VERSION ""

NS_ :

BS_:

BU_: VDM CMR_DSMC SOBDMC_HPCM_FD1 IPMA_ADAS PSCM ABS_ESC TCCM TCM_DSL PCM_HEV PCM ECM_Diesel GENERIC_GWMWakeup GWM _delete TSTR

BO_ 1046 BrakeSysFeatures_2: 8 ABS_ESC
 SG_ HsaMde_D_Mem : 33|2@0+ (1,0) [0|3] "SED"  GWM
 SG_ BrkBstrVac_B_Rq : 27|1@0+ (1,0) [0|1] "Discrete"  ECM_Diesel,PCM,PCM_HEV,GWM
 SG_ HdcMde_D_Actl : 31|3@0+ (1,0) [0|7] "SED"  GWM
 SG_ RearDiffLck_Tq2_RqMx : 51|12@0+ (4,0) [0|16376] "Nm"  GWM
 SG_ TRLR_SWAY_EVNT_IN_PROG : 25|1@0+ (1,0) [0|1] "SED"  GWM
 SG_ TRLR_SWAY_CONFIG_STAT : 26|1@0+ (1,0) [0|1] "SED"  GWM
 SG_ TCMode : 15|1@0+ (1,0) [0|1] "SED"  VDM,IPMA_ADAS,ECM_Diesel,PCM,PCM_HEV,GWM
 SG_ DrvSlipCtlLamp_D_Rq : 42|2@0+ (1,0) [0|3] "SED"  VDM,IPMA_ADAS,ECM_Diesel,PCM,PCM_HEV,GWM
 SG_ Abs_B_Falt : 5|1@0+ (1,0) [0|1] "SED"  ECM_Diesel,PCM,PCM_HEV,GWM
 SG_ DrvSlipCtlMde_D_Ind : 44|2@0+ (1,0) [0|3] "SED"  TCCM,IPMA_ADAS,ECM_Diesel,PCM,PCM_HEV,GWM
 SG_ DrvAntiLckLamp_D_Rq : 55|2@0+ (1,0) [0|3] "SED"  ECM_Diesel,GWM,IPMA_ADAS
 SG_ BpedMove_No_Cnt : 3|4@0+ (1,0) [0|15] "Unitless"  ECM_Diesel,GWM
 SG_ StabCtlBrk_B_Avail : 4|1@0+ (1,0) [0|1] "SED"  VDM,TCCM,GWM
 SG_ DrvHdcWarnInfo_D_Rq : 35|2@0+ (1,0) [0|3] "SED"  GWM
 SG_ DrvHdcMsg_D_Rq : 10|3@0+ (1,0) [0|7] "SED"  GWM
 SG_ DrvHdcLampInfo_D_Rq : 12|2@0+ (1,0) [0|3] "SED"  GWM
 SG_ BpedMove_D_Actl : 7|2@0+ (1,0) [0|3] "SED"  ECM_Diesel,GWM
 SG_ ChimeBrk_B_Rq : 14|1@0+ (1,0) [0|1] "SED"  GWM
 SG_ BrkLamp_B_Rq : 13|1@0+ (1,0) [0|1] "SED"  GWM
 SG_ HILL_DESC_MC : 47|3@0+ (1,0) [0|7] "SED"  GWM
 SG_ RearDiffElckrOpen_B_Rq : 40|1@0+ (1,0) [0|1] "SED"  GWM,TCCM

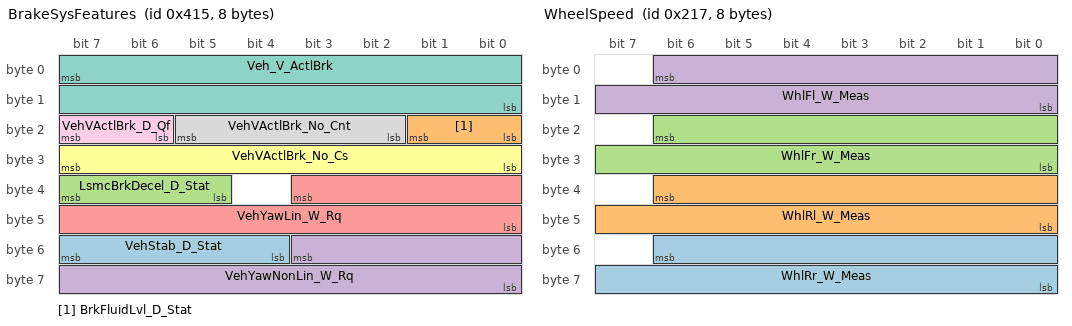
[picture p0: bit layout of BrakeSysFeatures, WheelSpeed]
BO_ 1045 BrakeSysFeatures: 8 ABS_ESC
 SG_ VehStab_D_Stat : 55|4@0+ (1,0) [0|15] "SED"  TCCM,PCM_HEV,PCM,GWM
 SG_ BrkFluidLvl_D_Stat : 17|2@0+ (1,0) [0|3] "SED"  GWM
 SG_ LsmcBrkDecel_D_Stat : 39|3@0+ (1,0) [0|7] "SED"  PSCM,GWM
 SG_ VehYawNonLin_W_Rq : 51|12@0+ (0.03663,-75) [-75|74.92659] "deg/s"  ECM_Diesel,GWM
 SG_ VehYawLin_W_Rq : 35|12@0+ (0.03663,-75) [-75|74.92659] "deg/s"  ECM_Diesel,GWM
 SG_ VehVActlBrk_No_Cs : 31|8@0+ (1,0) [0|255] "Unitless"  TCCM,CMR_DSMC,SOBDMC_HPCM_FD1,ECM_Diesel,PCM,PCM_HEV,PSCM,TCM_DSL,GWM,IPMA_ADAS
 SG_ Veh_V_ActlBrk : 7|16@0+ (0.01,0) [0|655.35] "kph"  TCCM,CMR_DSMC,SOBDMC_HPCM_FD1,IPMA_ADAS,ECM_Diesel,PCM,PCM_HEV,PSCM,TCM_DSL,GWM
 SG_ VehVActlBrk_No_Cnt : 21|4@0+ (1,0) [0|15] "Unitless"  TCCM,CMR_DSMC,SOBDMC_HPCM_FD1,ECM_Diesel,PCM,PCM_HEV,PSCM,TCM_DSL,GWM,IPMA_ADAS
 SG_ VehVActlBrk_D_Qf : 23|2@0+ (1,0) [0|3] "SED"  TCCM,CMR_DSMC,SOBDMC_HPCM_FD1,IPMA_ADAS,ECM_Diesel,PCM,PCM_HEV,PSCM,TCM_DSL,GWM

BO_ 535 WheelSpeed: 8 ABS_ESC
 SG_ WhlRr_W_Meas : 54|15@0+ (0.01,0) [0|327.65] "rad/s"  VDM,IPMA_ADAS,GWM,ECM_Diesel,PCM,PCM_HEV,PSCM,TCCM,TCM_DSL
 SG_ WhlRl_W_Meas : 38|15@0+ (0.01,0) [0|327.65] "rad/s"  VDM,IPMA_ADAS,GWM,ECM_Diesel,PCM,PCM_HEV,PSCM,TCCM,TCM_DSL
 SG_ WhlFr_W_Meas : 22|15@0+ (0.01,0) [0|327.65] "rad/s"  VDM,IPMA_ADAS,GWM,ECM_Diesel,PCM,PCM_HEV,PSCM,TCCM,TCM_DSL
 SG_ WhlFl_W_Meas : 6|15@0+ (0.01,0) [0|327.65] "rad/s"  VDM,IPMA_ADAS,GWM,ECM_Diesel,PCM,PCM_HEV,PSCM,TCCM,TCM_DSL

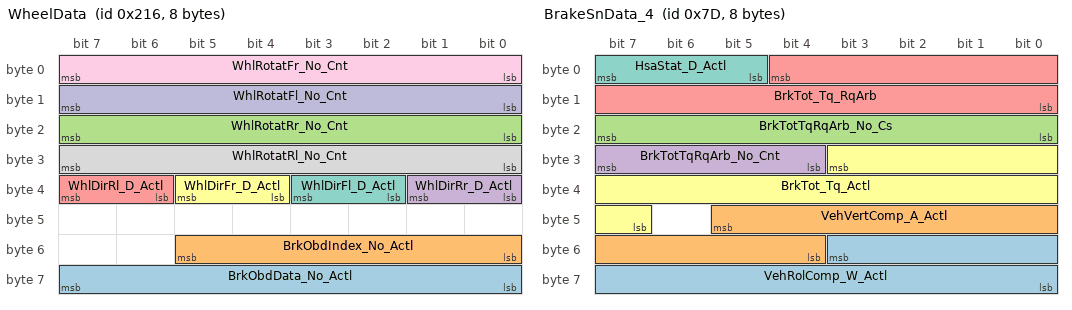
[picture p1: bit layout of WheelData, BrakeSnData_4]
BO_ 534 WheelData: 8 ABS_ESC
 SG_ BrkObdData_No_Actl : 63|8@0+ (1,0) [0|255] "unitless"  SOBDMC_HPCM_FD1,GWM
 SG_ BrkObdIndex_No_Actl : 53|6@0+ (1,0) [0|63] "unitless"  SOBDMC_HPCM_FD1,GWM
 SG_ WhlRotatRr_No_Cnt : 23|8@0+ (1,0) [0|255] "Unitless"  IPMA_ADAS,GWM,PSCM
 SG_ WhlDirRr_D_Actl : 33|2@0+ (1,0) [0|3] "SED"  IPMA_ADAS,GWM,ECM_Diesel,PCM_HEV,PSCM
 SG_ WhlDirRl_D_Actl : 39|2@0+ (1,0) [0|3] "SED"  IPMA_ADAS,GWM,PSCM,ECM_Diesel,PCM_HEV
 SG_ WhlDirFr_D_Actl : 37|2@0+ (1,0) [0|3] "SED"  IPMA_ADAS,GWM,ECM_Diesel,PCM_HEV,PSCM
 SG_ WhlDirFl_D_Actl : 35|2@0+ (1,0) [0|3] "SED"  IPMA_ADAS,GWM,ECM_Diesel,PCM_HEV,PSCM
 SG_ WhlRotatRl_No_Cnt : 31|8@0+ (1,0) [0|255] "Unitless"  IPMA_ADAS,GWM,PSCM
 SG_ WhlRotatFr_No_Cnt : 7|8@0+ (1,0) [0|255] "Unitless"  IPMA_ADAS,GWM,PSCM
 SG_ WhlRotatFl_No_Cnt : 15|8@0+ (1,0) [0|255] "Unitless"  IPMA_ADAS,GWM,PSCM

BO_ 531 DesiredTorqBrk: 8 ABS_ESC
 SG_ VehStop_D_Stat : 28|2@0+ (1,0) [0|3] "SED"  IPMA_ADAS,GWM
 SG_ TracCtlPtActv_B_Actl : 31|1@0+ (1,0) [0|1] "SED"  VDM,IPMA_ADAS,TCCM,ECM_Diesel,PCM,PCM_HEV,TCM_DSL,GWM
 SG_ LscmbbMntr_B_Err : 17|1@0+ (1,0) [0|1] "SED"  GWM
 SG_ LscmbbBrkDis_B_Actl : 19|1@0+ (1,0) [0|1] "SED"  GWM
 SG_ LscmbbDeny_B_ActlBrk : 18|1@0+ (1,0) [0|1] "SED"  GWM
 SG_ PrkBrkYwLamp_D_Rq : 38|2@0+ (1,0) [0|3] "SED"  GWM
 SG_ PrkBrkRedLamp_D_Rq : 30|2@0+ (1,0) [0|3] "SED"  GWM
 SG_ LscmbbBrkDecel_B_Actl : 20|1@0+ (1,0) [0|1] "SED"  GWM
 SG_ AbsActv_B_Actl : 45|1@0+ (1,0) [0|1] "SED"  VDM,SOBDMC_HPCM_FD1,IPMA_ADAS,ECM_Diesel,PCM,PCM_HEV,TCM_DSL,PSCM,GWM
 SG_ StabCtlBrkActv_B_Actl : 23|1@0+ (1,0) [0|1] "SED"  VDM,IPMA_ADAS,PCM,PCM_HEV,TCM_DSL,PSCM,TCCM,ECM_Diesel,GWM
 SG_ CmbbBrkPrchg_B_Actl : 59|1@0+ (1,0) [0|1] "SED"  IPMA_ADAS,GWM
 SG_ CmbbBrkDecel_B_Actl : 58|1@0+ (1,0) [0|1] "SED"  CMR_DSMC,IPMA_ADAS,GWM
 SG_ CmbbBaSensInc_B_Actl : 57|1@0+ (1,0) [0|1] "SED"  IPMA_ADAS,GWM
 SG_ AccBrkWarm_B_Actl : 63|1@0+ (1,0) [0|1] "SED"  IPMA_ADAS,GWM
 SG_ AccBrkTotTqMn_B_Actl : 62|1@0+ (1,0) [0|1] "SED"  IPMA_ADAS,GWM
 SG_ AccBrkPrchgActv_B_Actl : 61|1@0+ (1,0) [0|1] "SED"  IPMA_ADAS,GWM
 SG_ AccBrkDis_B_Actl : 44|1@0+ (1,0) [0|1] "SED"  IPMA_ADAS,GWM
 SG_ AccBrkDeny_B_Actl : 42|1@0+ (1,0) [0|1] "SED"  IPMA_ADAS,ECM_Diesel,PCM,PCM_HEV,GWM
 SG_ AccBrkActv_B_Actl : 43|1@0+ (1,0) [0|1] "SED"  IPMA_ADAS,ECM_Diesel,GWM
 SG_ PrplDrgCtlActv_B_Actl : 46|1@0+ (1,0) [0|1] "SED"  ECM_Diesel,PCM,PCM_HEV,TCM_DSL,GWM
 SG_ PrplWhlTot_Tq_RqMx : 7|16@0+ (4,-131072) [-131072|131068] "Nm"  ECM_Diesel,PCM,PCM_HEV,TCCM,GWM
 SG_ LscmbbBaSensInc_B_Actl : 21|1@0+ (1,0) [0|1] "SED"  GWM
 SG_ CmbbBrkDis_B_Actl : 56|1@0+ (1,0) [0|1] "SED"  IPMA_ADAS,PSCM,GWM
 SG_ CmbbDeny_B_ActlBrk : 60|1@0+ (1,0) [0|1] "SED"  IPMA_ADAS,PSCM,ECM_Diesel,PCM,PCM_HEV,GWM
 SG_ CcDis_B_Cmd : 47|1@0+ (1,0) [0|1] "SED"  PCM,PCM_HEV,GWM
 SG_ VehLongOvrGnd_A_Est : 41|10@0+ (0.035,-17.9) [-17.9|17.835] "m/s^2"  VDM,IPMA_ADAS,TCCM,GWM
 SG_ LscmbBrkPrchg_B_Actl : 16|1@0+ (1,0) [0|1] "SED"  GWM
 SG_ AccStopActv_B_ActlBrk : 22|1@0+ (1,0) [0|1] "SED"  IPMA_ADAS,ECM_Diesel,PCM,PCM_HEV,GWM
 SG_ AccDis_B_ActlEpb : 32|1@0+ (1,0) [0|1] "SED"  IPMA_ADAS,GWM
 SG_ PrkBrkMsgTxt_D_Rq : 36|4@0+ (1,0) [0|15] "SED"  GWM
 SG_ PrkBrkStatus : 26|3@0+ (1,0) [0|7] "SED"  IPMA_ADAS,ECM_Diesel,PCM,PCM_HEV,TCM_DSL,GWM

BO_ 125 BrakeSnData_4: 8 ABS_ESC
 SG_ VehRolComp_W_Actl : 51|12@0+ (0.03663,-75) [-75|74.92659] "degrees/sec"  VDM,GWM
 SG_ VehVertComp_A_Actl : 45|10@0+ (0.035,-17.9) [-17.9|17.835] "m/s^2"  VDM,PSCM,GWM
 SG_ BrkTotTqRqArb_No_Cs : 23|8@0+ (1,0) [0|255] "Unitless"  ECM_Diesel,PCM,PCM_HEV,GWM
 SG_ BrkTotTqRqArb_No_Cnt : 31|4@0+ (1,0) [0|15] "Unitless"  ECM_Diesel,PCM,PCM_HEV,GWM
 SG_ BrkTot_Tq_RqArb : 4|13@0+ (4,0) [0|32756] "Nm"  VDM,IPMA_ADAS,ECM_Diesel,PCM,PCM_HEV,TCM_DSL,PSCM,GWM
 SG_ BrkTot_Tq_Actl : 27|13@0+ (4,0) [0|32756] "Nm"  ECM_Diesel,PCM,PCM_HEV,PSCM,GWM,TCCM
 SG_ HsaStat_D_Actl : 7|3@0+ (1,0) [0|7] "SED"  ECM_Diesel,PCM,PCM_HEV,TCM_DSL,GWM

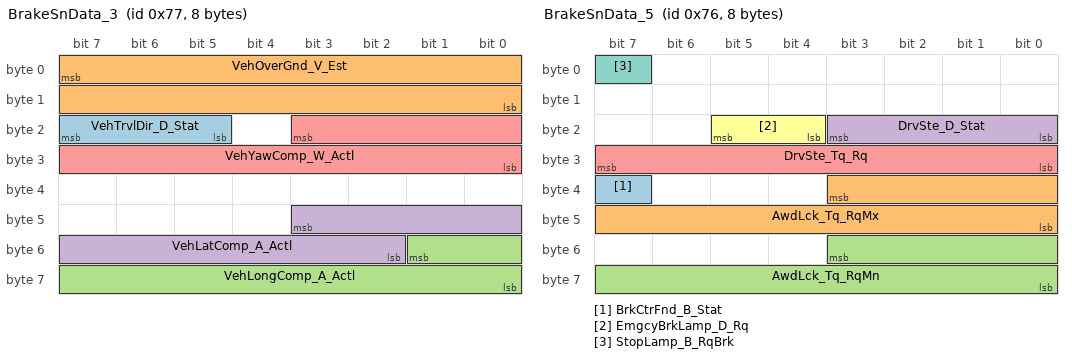
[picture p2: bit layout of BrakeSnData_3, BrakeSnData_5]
BO_ 119 BrakeSnData_3: 8 ABS_ESC
 SG_ VehTrvlDir_D_Stat : 23|3@0+ (1,0) [0|7] "SED"  GWM
 SG_ VehOverGnd_V_Est : 7|16@0+ (0.01,0) [0|655.33] "kph"  VDM,IPMA_ADAS,TCCM,PSCM,GWM
 SG_ VehLongComp_A_Actl : 49|10@0+ (0.035,-17.9) [-17.9|17.835] "m/s^2"  VDM,ECM_Diesel,PCM,PCM_HEV,TCM_DSL,PSCM,GWM
 SG_ VehLatComp_A_Actl : 43|10@0+ (0.035,-17.9) [-17.9|17.835] "m/s^2"  VDM,ECM_Diesel,PCM,PCM_HEV,TCM_DSL,PSCM,TCCM,GWM
 SG_ VehYawComp_W_Actl : 19|12@0+ (0.03663,-75) [-75|74.92659] "deg/s"  VDM,TCCM,IPMA_ADAS,ECM_Diesel,PCM,PCM_HEV,TCM_DSL,PSCM,GWM

BO_ 118 BrakeSnData_5: 8 ABS_ESC
 SG_ BrkCtrFnd_B_Stat : 39|1@0+ (1,0) [0|1] "SED"  GWM
 SG_ AwdLck_Tq_RqMx : 35|12@0+ (1,0) [0|4095] "Nm"  GWM,TCCM
 SG_ AwdLck_Tq_RqMn : 51|12@0+ (1,0) [0|4095] "Nm"  GWM,TCCM
 SG_ DrvSte_D_Stat : 19|4@0+ (1,0) [0|15] "SED"  PSCM,GWM
 SG_ DrvSte_Tq_Rq : 31|8@0+ (0.0625,-8) [-8|7.8125] "Nm"  PSCM,GWM
 SG_ EmgcyBrkLamp_D_Rq : 21|2@0+ (1,0) [0|3] "SED"  GWM
 SG_ StopLamp_B_RqBrk : 7|1@0+ (1,0) [0|1] "SED"  GWM

BO_ 1034 GGCC_Config_Mgmt_ID_1_FD1: 8 GWM
 SG_ VehicleGGCCData : 7|64@0+ (1,0) [0|1.84467e+19] "mixed"  VDM,CMR_DSMC,SOBDMC_HPCM_FD1,IPMA_ADAS,ABS_ESC,ECM_Diesel,PCM,PCM_HEV,PSCM,TCCM,TCM_DSL

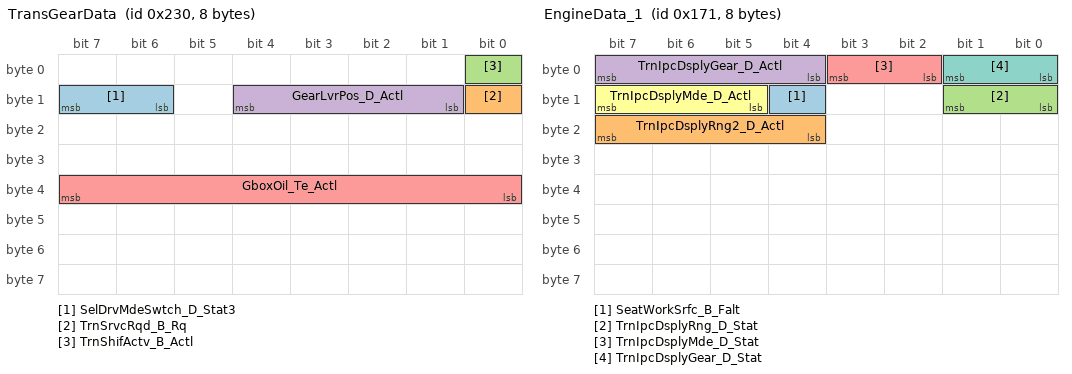
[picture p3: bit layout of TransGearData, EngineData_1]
BO_ 560 TransGearData: 8 TCM_DSL
 SG_ SelDrvMdeSwtch_D_Stat3 : 15|2@0+ (1,0) [0|3] "SED"  GWM,ABS_ESC
 SG_ TrnSrvcRqd_B_Rq : 8|1@0+ (1,0) [0|1] "SED"  GWM
 SG_ TrnShifActv_B_Actl : 0|1@0+ (1,0) [0|1] "SED"  GWM,ABS_ESC,ECM_Diesel
 SG_ GearLvrPos_D_Actl : 12|4@0+ (1,0) [0|15] "SED"  VDM,IPMA_ADAS,GWM,ABS_ESC,PSCM,TCCM,ECM_Diesel
 SG_ GboxOil_Te_Actl : 39|8@0+ (1,-60) [-60|193] "degC"  SOBDMC_HPCM_FD1,GWM,TCCM,ECM_Diesel

BO_ 369 EngineData_1: 8 PCM
 SG_ SeatWorkSrfc_B_Falt : 12|1@0+ (1,0) [0|1] "SED"  GWM
 SG_ TrnIpcDsplyRng2_D_Actl : 23|4@0+ (1,0) [0|15] "SED"  GWM
 SG_ TrnIpcDsplyRng_D_Stat : 9|2@0+ (1,0) [0|3] "SED"  GWM
 SG_ TrnIpcDsplyGear_D_Actl : 7|4@0+ (1,0) [0|15] "SED"  GWM
 SG_ TrnIpcDsplyMde_D_Stat : 3|2@0+ (1,0) [0|3] "SED"  GWM
 SG_ TrnIpcDsplyMde_D_Actl : 15|3@0+ (1,0) [0|7] "SED"  GWM
 SG_ TrnIpcDsplyGear_D_Stat : 1|2@0+ (1,0) [0|3] "SED"  GWM

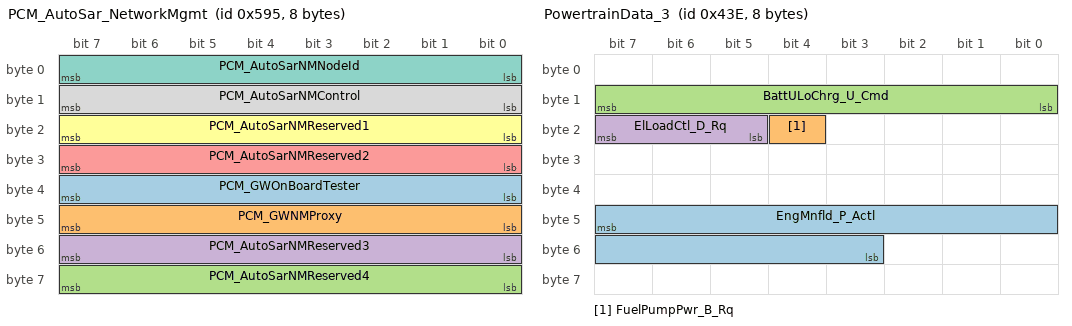
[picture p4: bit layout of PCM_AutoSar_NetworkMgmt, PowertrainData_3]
BO_ 1429 PCM_AutoSar_NetworkMgmt: 8 PCM_HEV
 SG_ PCM_GWOnBoardTester : 39|8@0+ (1,0) [0|255] "unitless"  TCM_DSL
 SG_ PCM_GWNMProxy : 47|8@0+ (1,0) [0|255] "unitless"  TCM_DSL
 SG_ PCM_AutoSarNMReserved4 : 63|8@0+ (1,0) [0|255] "unitless"  TCM_DSL
 SG_ PCM_AutoSarNMReserved3 : 55|8@0+ (1,0) [0|255] "unitless"  TCM_DSL
 SG_ PCM_AutoSarNMReserved2 : 31|8@0+ (1,0) [0|255] "unitless"  TCM_DSL
 SG_ PCM_AutoSarNMReserved1 : 23|8@0+ (1,0) [0|255] "unitless"  TCM_DSL
 SG_ PCM_AutoSarNMNodeId : 7|8@0+ (1,0) [0|255] "unitless"  TCM_DSL
 SG_ PCM_AutoSarNMControl : 15|8@0+ (1,0) [0|255] "unitless"  TCM_DSL

BO_ 1086 PowertrainData_3: 8 PCM_HEV
 SG_ EngMnfld_P_Actl : 47|13@0+ (0.1,-206.8) [-206.8|612.3] "kilopascal"  GWM
 SG_ FuelPumpPwr_B_Rq : 20|1@0+ (1,0) [0|1] "SED"  GWM
 SG_ BattULoChrg_U_Cmd : 15|8@0+ (0.025,10.6) [10.6|16.975] "volt"  GWM
 SG_ ElLoadCtl_D_Rq : 23|3@0+ (1,0) [0|7] "SED"  GWM

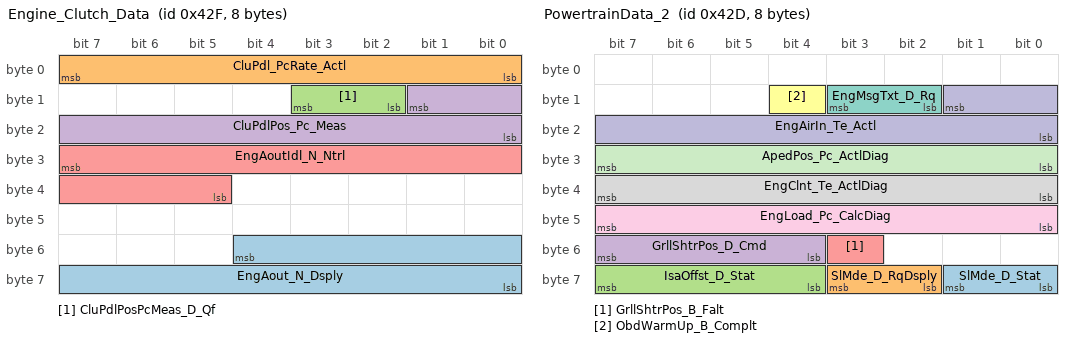
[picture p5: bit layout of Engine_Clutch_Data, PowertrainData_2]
BO_ 1071 Engine_Clutch_Data: 8 PCM_HEV
 SG_ EngAout_N_Dsply : 52|13@0+ (2,0) [0|16382] "rpm"  GWM
 SG_ CluPdl_PcRate_Actl : 7|8@0+ (0.04,-5) [-5|5.2] "%/ms"  GWM
 SG_ CluPdlPosPcMeas_D_Qf : 11|2@0+ (1,0) [0|3] "SED"  ABS_ESC,GWM
 SG_ CluPdlPos_Pc_Meas : 9|10@0+ (0.1,0) [0|102.3] "%"  ABS_ESC,GWM
 SG_ EngAoutIdl_N_Ntrl : 31|11@0+ (2,0) [0|4094] "rpm"  ABS_ESC,GWM

BO_ 1069 PowertrainData_2: 8 PCM_HEV
 SG_ SlMde_D_Stat : 57|2@0+ (1,0) [0|3] "SED"  GWM
 SG_ SlMde_D_RqDsply : 59|2@0+ (1,0) [0|3] "SED"  GWM
 SG_ IsaOffst_D_Stat : 63|4@0+ (1,0) [0|15] "SED"  GWM
 SG_ GrllShtrPos_D_Cmd : 55|4@0+ (1,0) [0|15] "SED"  GWM
 SG_ GrllShtrPos_B_Falt : 51|1@0+ (1,0) [0|1] "SED"  GWM
 SG_ ObdWarmUp_B_Complt : 12|1@0+ (1,0) [0|1] "SED"  SOBDMC_HPCM_FD1,GWM
 SG_ EngMsgTxt_D_Rq : 11|2@0+ (1,0) [0|3] "SED"  GWM
 SG_ EngClnt_Te_ActlDiag : 39|8@0+ (1,-40) [-40|215] "degC"  SOBDMC_HPCM_FD1,TCM_DSL,GWM
 SG_ EngLoad_Pc_CalcDiag : 47|8@0+ (0.392157,0) [0|100.000035] "%"  SOBDMC_HPCM_FD1,TCM_DSL,GWM
 SG_ EngAirIn_Te_Actl : 9|10@0+ (0.25,-128) [-128|127.25] "degC"  GWM,TCM_DSL
 SG_ ApedPos_Pc_ActlDiag : 31|8@0+ (0.392157,0) [0|100.000035] "%"  SOBDMC_HPCM_FD1,TCM_DSL,GWM

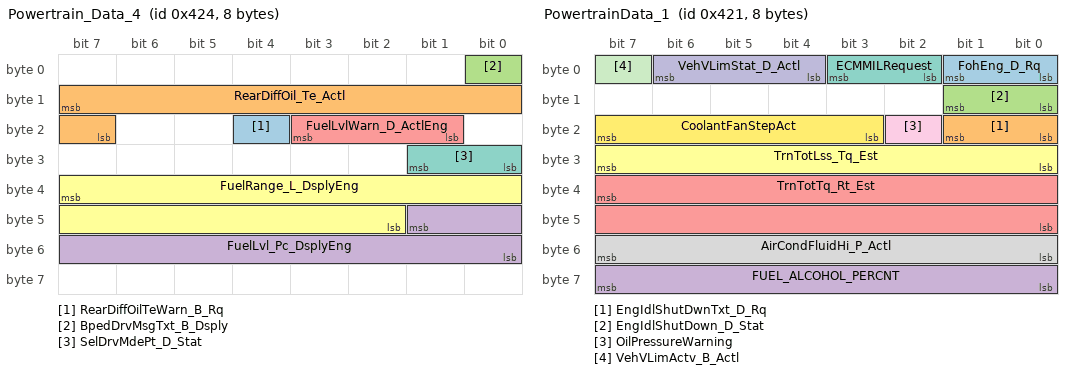
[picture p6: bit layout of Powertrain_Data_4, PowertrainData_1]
BO_ 1060 Powertrain_Data_4: 8 PCM_HEV
 SG_ RearDiffOilTeWarn_B_Rq : 20|1@0+ (1,0) [0|1] "SED"  GWM
 SG_ RearDiffOil_Te_Actl : 15|9@0+ (1,-40) [-40|470] "degC"  GWM
 SG_ BpedDrvMsgTxt_B_Dsply : 0|1@0+ (1,0) [0|1] "SED"  GWM
 SG_ FuelLvl_Pc_DsplyEng : 41|10@0+ (0.108696,-5.217408) [-5.217408|105.9786] "percent"  GWM
 SG_ FuelLvlWarn_D_ActlEng : 19|3@0+ (1,0) [0|7] "SED"  GWM
 SG_ FuelRange_L_DsplyEng : 39|14@0+ (0.1,0) [0|1638.3] "kilometer"  GWM
 SG_ SelDrvMdePt_D_Stat : 25|2@0+ (1,0) [0|3] "SED"  ABS_ESC,GWM

BO_ 1057 PowertrainData_1: 8 PCM_HEV
 SG_ FohEng_D_Rq : 1|2@0+ (1,0) [0|3] "SED"  GWM
 SG_ EngIdlShutDwnTxt_D_Rq : 17|2@0+ (1,0) [0|3] "SED"  GWM
 SG_ EngIdlShutDown_D_Stat : 9|2@0+ (1,0) [0|3] "SED"  GWM
 SG_ FUEL_ALCOHOL_PERCNT : 63|8@0+ (0.393700787,0) [0|99.999899898] "Percent"  GWM
 SG_ TrnTotTq_Rt_Est : 39|16@0+ (0.001,0) [0|65.533] "Unitless"  GWM
 SG_ TrnTotLss_Tq_Est : 31|8@0+ (0.5,0) [0|126.5] "Nm"  GWM
 SG_ ECMMILRequest : 3|2@0+ (1,0) [0|3] "SED"  GWM
 SG_ AirCondFluidHi_P_Actl : 55|8@0+ (0.125,0) [0|31.625] "bar"  SOBDMC_HPCM_FD1,GWM
 SG_ OilPressureWarning : 18|1@0+ (1,0) [0|1] "SED"  GWM
 SG_ VehVLimStat_D_Actl : 6|3@0+ (1,0) [0|7] "SED"  GWM,TCM_DSL
 SG_ VehVLimActv_B_Actl : 7|1@0+ (1,0) [0|1] "SED"  GWM,TCM_DSL
 SG_ CoolantFanStepAct : 23|5@0+ (1,0) [0|31] "Steps"  GWM

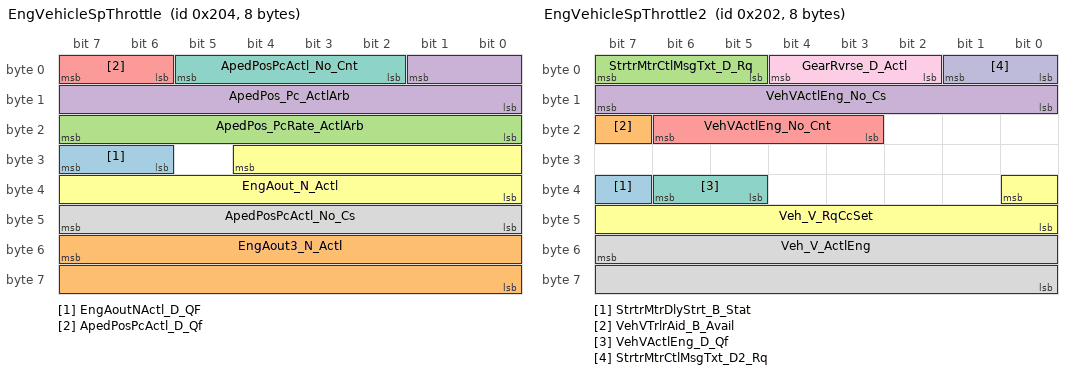
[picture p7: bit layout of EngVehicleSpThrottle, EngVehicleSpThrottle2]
BO_ 516 EngVehicleSpThrottle: 8 PCM_HEV
 SG_ EngAoutNActl_D_QF : 31|2@0+ (1,0) [0|3] "SED"  TCM_DSL,GWM
 SG_ EngAout3_N_Actl : 55|16@0+ (0.25,0) [0|16383.5] "RPM"  SOBDMC_HPCM_FD1,GWM
 SG_ ApedPos_PcRate_ActlArb : 23|8@0+ (0.04,-5) [-5|5.12] "%/ms"  TCM_DSL,GWM
 SG_ ApedPos_Pc_ActlArb : 1|10@0+ (0.1,0) [0|102.3] "%"  VDM,CMR_DSMC,SOBDMC_HPCM_FD1,IPMA_ADAS,TCCM,ABS_ESC,PSCM,TCM_DSL,GWM
 SG_ ApedPosPcActl_D_Qf : 7|2@0+ (1,0) [0|3] "SED"  VDM,CMR_DSMC,IPMA_ADAS,SOBDMC_HPCM_FD1,ABS_ESC,PSCM,TCM_DSL,GWM
 SG_ EngAout_N_Actl : 28|13@0+ (2,0) [0|16382] "rpm"  VDM,ABS_ESC,PSCM,TCCM,TCM_DSL,GWM
 SG_ ApedPosPcActl_No_Cnt : 5|4@0+ (1,0) [0|15] "Unitless"  ABS_ESC,SOBDMC_HPCM_FD1,GWM
 SG_ ApedPosPcActl_No_Cs : 47|8@0+ (1,0) [0|255] "Unitless"  ABS_ESC,SOBDMC_HPCM_FD1,GWM

BO_ 514 EngVehicleSpThrottle2: 8 PCM_HEV
 SG_ StrtrMtrDlyStrt_B_Stat : 39|1@0+ (1,0) [0|1] "SED"  GWM
 SG_ VehVTrlrAid_B_Avail : 23|1@0+ (1,0) [0|1] "SED"  PSCM,GWM
 SG_ StrtrMtrCtlMsgTxt_D_Rq : 7|3@0+ (1,0) [0|7] "SED"  GWM
 SG_ VehVActlEng_No_Cs : 15|8@0+ (1,0) [0|255] "Unitless"  PSCM,GWM
 SG_ VehVActlEng_No_Cnt : 22|4@0+ (1,0) [0|15] "Unitless"  PSCM,GWM
 SG_ Veh_V_RqCcSet : 32|9@0+ (0.5,0) [0|255.5] "kph"  IPMA_ADAS,ABS_ESC,TCM_DSL,GWM
 SG_ VehVActlEng_D_Qf : 38|2@0+ (1,0) [0|3] "SED"  VDM,IPMA_ADAS,ABS_ESC,PSCM,TCM_DSL,GWM
 SG_ Veh_V_ActlEng : 55|16@0+ (0.01,0) [0|655.35] "kph"  VDM,SOBDMC_HPCM_FD1,IPMA_ADAS,ABS_ESC,PSCM,TCM_DSL,GWM
 SG_ GearRvrse_D_Actl : 4|3@0+ (1,0) [0|7] "SED"  CMR_DSMC,IPMA_ADAS,ABS_ESC,PSCM,GWM
 SG_ StrtrMtrCtlMsgTxt_D2_Rq : 1|2@0+ (1,0) [0|3] "SED"  GWM

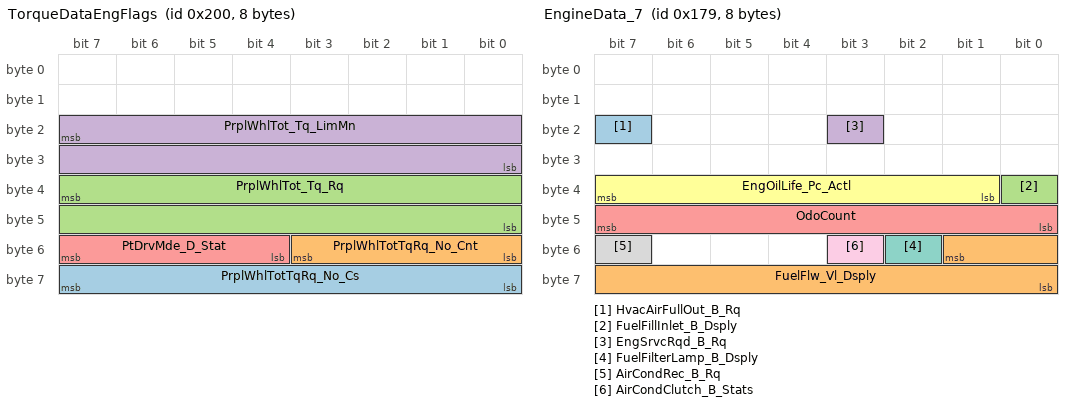
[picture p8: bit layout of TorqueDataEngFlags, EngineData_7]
BO_ 512 TorqueDataEngFlags: 8 PCM_HEV
 SG_ PrplWhlTotTqRq_No_Cs : 63|8@0+ (1,0) [0|255] "Unitless"  ABS_ESC,GWM
 SG_ PrplWhlTotTqRq_No_Cnt : 51|4@0+ (1,0) [0|15] "Unitless"  ABS_ESC,GWM
 SG_ PrplWhlTot_Tq_Rq : 39|16@0+ (4,-131072) [-131072|131068] "Nm"  VDM,TCCM,ABS_ESC,GWM
 SG_ PrplWhlTot_Tq_LimMn : 23|16@0+ (4,-131072) [-131072|131068] "Nm"  ABS_ESC,GWM
 SG_ PtDrvMde_D_Stat : 55|4@0+ (1,0) [0|15] "SED"  IPMA_ADAS,GWM

BO_ 377 EngineData_7: 8 PCM_HEV
 SG_ HvacAirFullOut_B_Rq : 23|1@0+ (1,0) [0|1] "SED"  GWM
 SG_ FuelFlw_Vl_Dsply : 49|10@0+ (25,0) [0|25575] "Micro_Liter"  GWM
 SG_ FuelFillInlet_B_Dsply : 32|1@0+ (1,0) [0|1] "SED"  GWM
 SG_ EngSrvcRqd_B_Rq : 19|1@0+ (1,0) [0|1] "SED"  GWM
 SG_ OdoCount : 47|8@0+ (0.2,0) [0|50.8] "Meters"  GWM
 SG_ EngOilLife_Pc_Actl : 39|7@0+ (1,0) [0|100] "Percent"  GWM
 SG_ FuelFilterLamp_B_Dsply : 50|1@0+ (1,0) [0|1] "SED"  GWM
 SG_ AirCondRec_B_Rq : 55|1@0+ (1,0) [0|1] "SED"  GWM
 SG_ AirCondClutch_B_Stats : 51|1@0+ (1,0) [0|1] "SED"  GWM

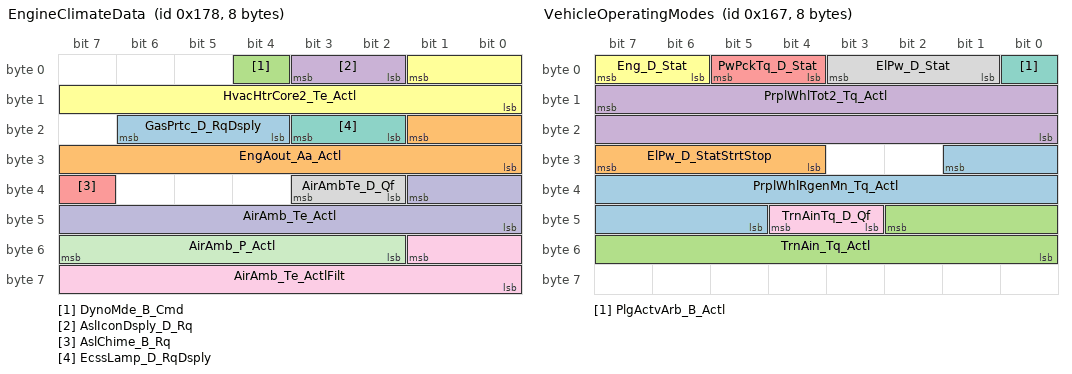
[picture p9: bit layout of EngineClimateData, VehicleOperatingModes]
BO_ 376 EngineClimateData: 8 PCM_HEV
 SG_ GasPrtc_D_RqDsply : 22|3@0+ (1,0) [0|7] "SED"  GWM
 SG_ EngAout_Aa_Actl : 17|10@0+ (0.05,-25.6) [-25.6|25.55] "rpm/ms"  ABS_ESC,GWM
 SG_ DynoMde_B_Cmd : 4|1@0+ (1,0) [0|1] "SED"  TCM_DSL,ABS_ESC,GWM
 SG_ AslIconDsply_D_Rq : 3|2@0+ (1,0) [0|3] "SED"  GWM
 SG_ AslChime_B_Rq : 39|1@0+ (1,0) [0|1] "SED"  GWM
 SG_ HvacHtrCore2_Te_Actl : 1|10@0+ (0.25,-50) [-50|205.5] "degC"  SOBDMC_HPCM_FD1,GWM
 SG_ EcssLamp_D_RqDsply : 19|2@0+ (1,0) [0|3] "SED"  GWM
 SG_ AirAmbTe_D_Qf : 35|2@0+ (1,0) [0|3] "SED"  SOBDMC_HPCM_FD1,IPMA_ADAS,ABS_ESC,TCCM,GWM
 SG_ AirAmb_Te_ActlFilt : 49|10@0+ (0.25,-128) [-128|127.75] "deg C"  SOBDMC_HPCM_FD1,IPMA_ADAS,GWM
 SG_ AirAmb_Te_Actl : 33|10@0+ (0.25,-128) [-128|127.75] "degC"  ABS_ESC,TCCM,GWM
 SG_ AirAmb_P_Actl : 55|6@0+ (10,500) [500|1110] "mbar"  ABS_ESC,TCM_DSL,GWM

BO_ 359 VehicleOperatingModes: 8 PCM_HEV
 SG_ PrplWhlRgenMn_Tq_Actl : 25|13@0+ (4,-16380) [-16380|16380] "Nm"  ABS_ESC,GWM
 SG_ ElPw_D_StatStrtStop : 31|4@0+ (1,0) [0|15] "SED"  ABS_ESC,PSCM,GWM
 SG_ TrnAin_Tq_Actl : 42|11@0+ (1,-500) [-500|1547] "Nm"  ABS_ESC,GWM
 SG_ PrplWhlTot2_Tq_Actl : 15|16@0+ (4,-131072) [-131072|131060] "Nm"  ABS_ESC,PSCM,TCCM,GWM
 SG_ PwPckTq_D_Stat : 5|2@0+ (1,0) [0|3] "SED"  VDM,CMR_DSMC,IPMA_ADAS,ABS_ESC,PSCM,TCCM,TCM_DSL,GWM
 SG_ Eng_D_Stat : 7|2@0+ (1,0) [0|3] "SED"  ABS_ESC,GWM
 SG_ PlgActvArb_B_Actl : 0|1@0+ (1,0) [0|1] "SED"  GWM
 SG_ ElPw_D_Stat : 3|3@0+ (1,0) [0|7] "SED"  VDM,CMR_DSMC,IPMA_ADAS,ABS_ESC,PSCM,TCCM,TCM_DSL,GWM
 SG_ TrnAinTq_D_Qf : 44|2@0+ (1,0) [0|3] "SED"  ABS_ESC,GWM

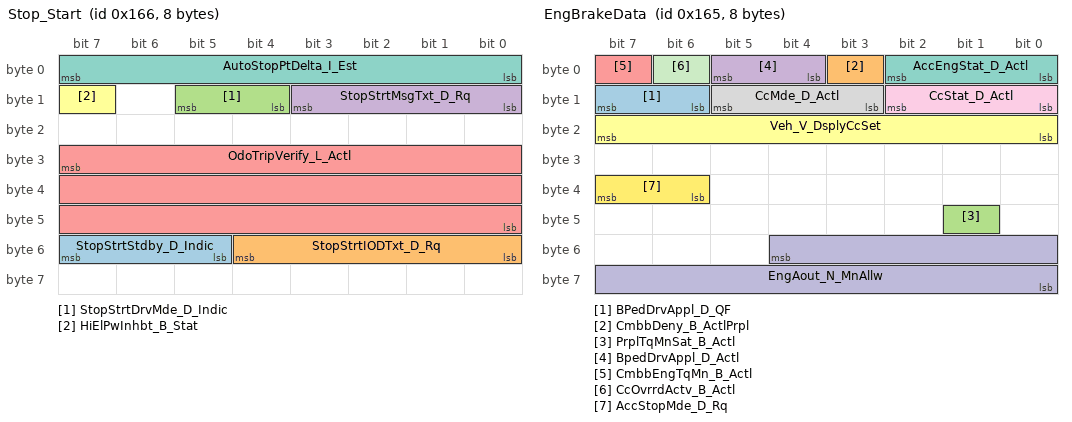
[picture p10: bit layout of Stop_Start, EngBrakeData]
BO_ 358 Stop_Start: 8 PCM_HEV
 SG_ StopStrtStdby_D_Indic : 55|3@0+ (1,0) [0|7] "SED"  GWM
 SG_ StopStrtIODTxt_D_Rq : 52|5@0+ (1,0) [0|31] "SED"  GWM
 SG_ StopStrtDrvMde_D_Indic : 13|2@0+ (1,0) [0|3] "SED"  GWM
 SG_ StopStrtMsgTxt_D_Rq : 11|4@0+ (1,0) [0|15] "SED"  GWM
 SG_ OdoTripVerify_L_Actl : 31|24@0+ (0.1,0) [0|1677721.4] "km"  GWM
 SG_ HiElPwInhbt_B_Stat : 15|1@0+ (1,0) [0|1] "SED"  GWM
 SG_ AutoStopPtDelta_I_Est : 7|8@0+ (1,-127) [-127|127] "Amps"  GWM

BO_ 357 EngBrakeData: 8 PCM_HEV
 SG_ BPedDrvAppl_D_QF : 15|2@0+ (1,0) [0|3] "SED"  CMR_DSMC,SOBDMC_HPCM_FD1,IPMA_ADAS,ABS_ESC,PSCM,TCM_DSL,GWM
 SG_ CmbbDeny_B_ActlPrpl : 3|1@0+ (1,0) [0|1] "SED"  IPMA_ADAS,GWM
 SG_ PrplTqMnSat_B_Actl : 41|1@0+ (1,0) [0|1] "SED"  IPMA_ADAS,GWM
 SG_ BpedDrvAppl_D_Actl : 5|2@0+ (1,0) [0|3] "SED"  CMR_DSMC,SOBDMC_HPCM_FD1,IPMA_ADAS,ABS_ESC,PSCM,TCCM,TCM_DSL,GWM
 SG_ CmbbEngTqMn_B_Actl : 7|1@0+ (1,0) [0|1] "SED"  IPMA_ADAS,GWM
 SG_ Veh_V_DsplyCcSet : 23|8@0+ (1,0) [0|253] "Unitless"  GWM,IPMA_ADAS
 SG_ AccEngStat_D_Actl : 2|3@0+ (1,0) [0|7] "SED"  IPMA_ADAS,GWM
 SG_ CcMde_D_Actl : 13|3@0+ (1,0) [0|7] "SED"  VDM,TCM_DSL,ABS_ESC,GWM
 SG_ CcStat_D_Actl : 10|3@0+ (1,0) [0|7] "SED"  CMR_DSMC,SOBDMC_HPCM_FD1,IPMA_ADAS,ABS_ESC,TCCM,TCM_DSL,GWM
 SG_ EngAout_N_MnAllw : 52|13@0+ (2,0) [0|16382] "rpm"  SOBDMC_HPCM_FD1,GWM
 SG_ CcOvrrdActv_B_Actl : 6|1@0+ (1,0) [0|1] "SED"  VDM,IPMA_ADAS,ABS_ESC,TCCM,TCM_DSL,GWM
 SG_ AccStopMde_D_Rq : 39|2@0+ (1,0) [0|3] "SED"  IPMA_ADAS,ABS_ESC,GWM

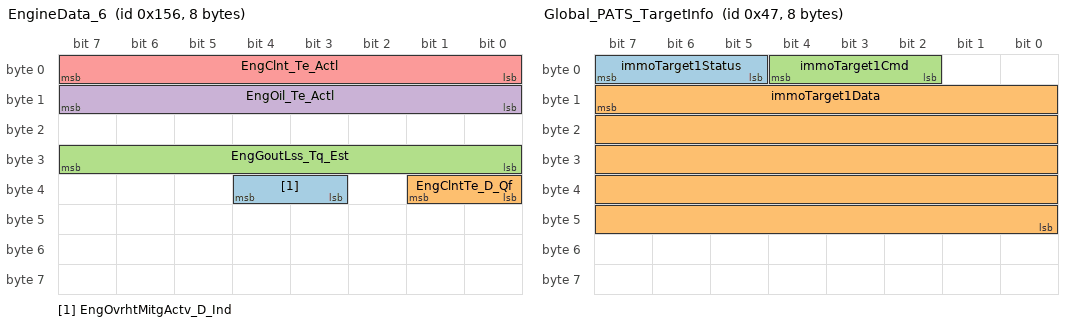
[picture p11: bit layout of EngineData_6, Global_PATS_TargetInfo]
BO_ 342 EngineData_6: 8 PCM_HEV
 SG_ EngOvrhtMitgActv_D_Ind : 36|2@0+ (1,0) [0|3] "SED"  GWM
 SG_ EngClntTe_D_Qf : 33|2@0+ (1,0) [0|3] "SED"  VDM,SOBDMC_HPCM_FD1,TCM_DSL,GWM
 SG_ EngGoutLss_Tq_Est : 31|8@0+ (1,0) [0|255] "Nm"  SOBDMC_HPCM_FD1,GWM
 SG_ EngOil_Te_Actl : 15|8@0+ (1,-60) [-60|193] "degC"  GWM
 SG_ EngClnt_Te_Actl : 7|8@0+ (1,-60) [-60|195] "degC"  VDM,SOBDMC_HPCM_FD1,TCM_DSL,GWM

BO_ 71 Global_PATS_TargetInfo: 8 PCM_HEV
 SG_ immoTarget1Status : 7|3@0+ (1,0) [0|7] "SED"  ABS_ESC,TCM_DSL,GWM
 SG_ immoTarget1Data : 15|40@0+ (1,0) [0|1.0995116278e+12] "Encrypted"  ABS_ESC,GWM
 SG_ immoTarget1Cmd : 4|3@0+ (1,0) [0|7] "SED"  ABS_ESC,GWM

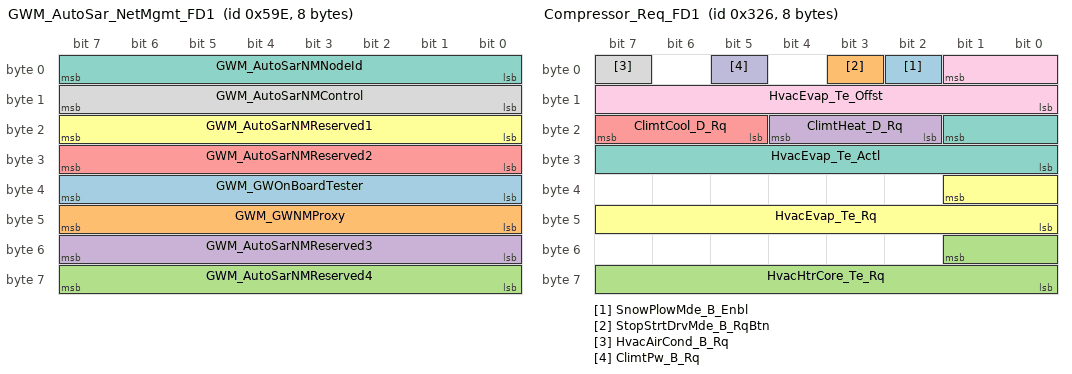
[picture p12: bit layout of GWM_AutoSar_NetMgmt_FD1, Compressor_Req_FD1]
BO_ 1438 GWM_AutoSar_NetMgmt_FD1: 8 GWM
 SG_ GWM_GWOnBoardTester : 39|8@0+ (1,0) [0|255] "unitless"  PCM_HEV,PCM,SOBDMC_HPCM_FD1,PSCM,ABS_ESC
 SG_ GWM_GWNMProxy : 47|8@0+ (1,0) [0|255] "unitless"  PCM_HEV,PCM,SOBDMC_HPCM_FD1,PSCM,ABS_ESC
 SG_ GWM_AutoSarNMReserved4 : 63|8@0+ (1,0) [0|255] "unitless"  PCM_HEV,PCM,SOBDMC_HPCM_FD1,PSCM,ABS_ESC
 SG_ GWM_AutoSarNMReserved3 : 55|8@0+ (1,0) [0|255] "unitless"  PCM_HEV,PCM,SOBDMC_HPCM_FD1,PSCM,ABS_ESC
 SG_ GWM_AutoSarNMReserved2 : 31|8@0+ (1,0) [0|255] "unitless"  PCM_HEV,PCM,SOBDMC_HPCM_FD1,PSCM,ABS_ESC
 SG_ GWM_AutoSarNMReserved1 : 23|8@0+ (1,0) [0|255] "unitless"  PCM_HEV,PCM,SOBDMC_HPCM_FD1,PSCM,ABS_ESC
 SG_ GWM_AutoSarNMNodeId : 7|8@0+ (1,0) [0|255] "unitless"  PCM_HEV,PCM,SOBDMC_HPCM_FD1,PSCM,ABS_ESC
 SG_ GWM_AutoSarNMControl : 15|8@0+ (1,0) [0|255] "unitless"  PCM_HEV,PCM,SOBDMC_HPCM_FD1,PSCM,ABS_ESC

BO_ 131 Steering_Data_FD1: 8 GWM
 SG_ HeadLghtHiFlash_D_Stat : 7|2@0+ (1,0) [0|3] "SED" Vector__XXX
 SG_ TurnLghtSwtch_D_Stat : 5|2@0+ (1,0) [0|3] "SED"  IPMA_ADAS,PSCM
 SG_ WiprFront_D_Stat : 3|4@0+ (1,0) [0|15] "SED"  ABS_ESC,IPMA_ADAS,PCM,PCM_HEV
 SG_ LghtAmb_D_Sns : 15|3@0+ (1,0) [0|7] "SED"  IPMA_ADAS
 SG_ AccButtnGapDecPress : 12|1@0+ (1,0) [0|1] "SED"  IPMA_ADAS
 SG_ AccButtnGapIncPress : 11|1@0+ (1,0) [0|1] "SED"  IPMA_ADAS
 SG_ AslButtnOnOffCnclPress : 10|1@0+ (1,0) [0|1] "SED"  ECM_Diesel,PCM,PCM_HEV
 SG_ AslButtnOnOffPress : 9|1@0+ (1,0) [0|1] "SED"  ECM_Diesel,PCM,PCM_HEV
 SG_ CcAslButtnCnclPress : 8|1@0+ (1,0) [0|1] "SED"  ECM_Diesel,IPMA_ADAS,PCM,PCM_HEV
 SG_ LaSwtchPos_D_Stat : 23|2@0+ (1,0) [0|3] "SED"  IPMA_ADAS
 SG_ CcAslButtnCnclResPress : 21|1@0+ (1,0) [0|1] "SED"  ECM_Diesel,IPMA_ADAS,PCM,PCM_HEV
 SG_ CcAslButtnDeny_B_Actl : 20|1@0+ (1,0) [0|1] "SED"  ECM_Diesel,IPMA_ADAS,PCM,PCM_HEV
 SG_ CcAslButtnIndxDecPress : 19|1@0+ (1,0) [0|1] "SED"  ECM_Diesel,PCM,PCM_HEV
 SG_ CcAslButtnIndxIncPress : 18|1@0+ (1,0) [0|1] "SED"  ECM_Diesel,PCM,PCM_HEV
 SG_ CcAslButtnOffCnclPress : 17|1@0+ (1,0) [0|1] "SED" Vector__XXX
 SG_ CcAslButtnOnOffCncl : 16|1@0+ (1,0) [0|1] "SED" Vector__XXX
 SG_ CcAslButtnOnPress : 31|1@0+ (1,0) [0|1] "SED"  ECM_Diesel,IPMA_ADAS,PCM,PCM_HEV
 SG_ CcAslButtnResDecPress : 30|1@0+ (1,0) [0|1] "SED" Vector__XXX
 SG_ CcAslButtnResIncPress : 29|1@0+ (1,0) [0|1] "SED"  ABS_ESC,ECM_Diesel,IPMA_ADAS,PCM,PCM_HEV
 SG_ CcAslButtnSetDecPress : 28|1@0+ (1,0) [0|1] "SED"  ABS_ESC,ECM_Diesel,IPMA_ADAS,PCM,PCM_HEV
 SG_ CcAslButtnSetIncPress : 27|1@0+ (1,0) [0|1] "SED"  ABS_ESC,ECM_Diesel,IPMA_ADAS,PCM,PCM_HEV
 SG_ CcAslButtnSetPress : 26|1@0+ (1,0) [0|1] "SED" Vector__XXX
 SG_ CcAsllButtnResPress : 25|1@0+ (1,0) [0|1] "SED"  ECM_Diesel,IPMA_ADAS,PCM,PCM_HEV
 SG_ CcButtnOffPress : 24|1@0+ (1,0) [0|1] "SED"  ECM_Diesel,IPMA_ADAS,PCM,PCM_HEV
 SG_ CcButtnOnOffCnclPress : 39|1@0+ (1,0) [0|1] "SED"  ECM_Diesel,IPMA_ADAS,PCM,PCM_HEV
 SG_ CcButtnOnOffPress : 38|1@0+ (1,0) [0|1] "SED"  ECM_Diesel,IPMA_ADAS,PCM,PCM_HEV
 SG_ CcButtnOnPress : 37|1@0+ (1,0) [0|1] "SED"  ECM_Diesel,IPMA_ADAS,PCM,PCM_HEV
 SG_ HeadLghtHiFlash_D_Actl : 36|2@0+ (1,0) [0|3] "SED"  IPMA_ADAS
 SG_ HeadLghtHiOn_B_StatAhb : 34|1@0+ (1,0) [0|1] "SED"  IPMA_ADAS
 SG_ AhbStat_B_Dsply : 33|1@0+ (1,0) [0|1] "SED" Vector__XXX
 SG_ AccButtnGapTogglePress : 32|1@0+ (1,0) [0|1] "SED"  IPMA_ADAS
 SG_ WiprFrontSwtch_D_Stat : 47|4@0+ (1,0) [0|15] "SED" Vector__XXX
 SG_ HeadLghtHiCtrl_D_RqAhb : 43|3@0+ (1,0) [0|7] "SED" Vector__XXX
 SG_ TjaButtnOnOffPress : 40|1@0+ (1,0) [0|1] "SED"  IPMA_ADAS

BO_ 968 Cluster_Lighting_Rq_FD1: 8 GWM
 SG_ SlMde_D_Rq : 27|2@0+ (1,0) [0|3] "SED"  ECM_Diesel
 SG_ IsaOffst_D_Rq : 31|4@0+ (1,0) [0|15] "SED"  ECM_Diesel

BO_ 806 Compressor_Req_FD1: 8 GWM
 SG_ SnowPlowMde_B_Enbl : 2|1@0+ (1,0) [0|1] "SED" Vector__XXX
 SG_ StopStrtDrvMde_B_RqBtn : 3|1@0+ (1,0) [0|1] "SED"  ECM_Diesel,PCM
 SG_ HvacHtrCore_Te_Rq : 49|10@0+ (0.25,-50) [-50|205.75] "degC"  PCM_HEV,SOBDMC_HPCM_FD1,ECM_Diesel
 SG_ ClimtHeat_D_Rq : 20|3@0+ (1,0) [0|7] "SED"  SOBDMC_HPCM_FD1,ECM_Diesel,PCM,PCM_HEV
 SG_ ClimtCool_D_Rq : 23|3@0+ (1,0) [0|7] "SED"  SOBDMC_HPCM_FD1,ECM_Diesel,PCM,PCM_HEV
 SG_ HvacEvap_Te_Rq : 33|10@0+ (0.125,-50) [-50|77.875] "Degrees C"  SOBDMC_HPCM_FD1,ECM_Diesel,PCM,PCM_HEV
 SG_ HvacEvap_Te_Actl : 17|10@0+ (0.125,-50) [-50|77.75] "Degrees C"  SOBDMC_HPCM_FD1,ECM_Diesel,PCM,PCM_HEV
 SG_ HvacAirCond_B_Rq : 7|1@0+ (1,0) [0|1] "SED"  ECM_Diesel,PCM,PCM_HEV
 SG_ HvacEvap_Te_Offst : 1|10@0+ (0.125,-50) [-50|77.875] "Degrees C"  ECM_Diesel,PCM,PCM_HEV
 SG_ ClimtPw_B_Rq : 5|1@0+ (1,0) [0|1] "SED"  ECM_Diesel,PCM

BO_ 1072 Cluster_Info1_FD1: 8 GWM
 SG_ LscmbbStat_B_Actl : 2|1@0+ (1,0) [0|1] "SED" Vector__XXX
 SG_ HaDsplyCpblty_B_Stat : 42|1@0+ (1,0) [0|1] "SED"  IPMA_ADAS
 SG_ AccDeny_B_RqIpc : 7|1@0+ (1,0) [0|1] "SED"  IPMA_ADAS
 SG_ DrvSlipCtlMde_D_Rq : 33|2@0+ (1,0) [0|3] "SED"  ABS_ESC
 SG_ EngIdlShutDown_B_RqDrv : 3|1@0+ (1,0) [0|1] "SED"  ECM_Diesel,PCM,PCM_HEV
 SG_ HsaMde_D_Rq : 54|2@0+ (1,0) [0|3] "SED"  ABS_ESC
 SG_ NtrlTowMdeEnbl_B_RqDrv : 1|1@0+ (1,0) [0|1] "SED"  TCCM,TCM_DSL,PCM_HEV,PCM
 SG_ BulbChkActv_B_Stat : 55|1@0+ (1,0) [0|1] "SED" Vector__XXX
 SG_ ParkDetect_Stat : 52|1@0+ (1,0) [0|1] "SED"  PCM_HEV,PCM
 SG_ ReducedGuard_D_Rq : 51|2@0+ (1,0) [0|3] "SED" Vector__XXX
 SG_ TrlrBrkMde_D_Rq : 57|1@0+ (1,0) [0|1] "SED" Vector__XXX
 SG_ TRLR_SWAY_CONFIG_CMD : 56|1@0+ (1,0) [0|1] "SED"  ABS_ESC
 SG_ TRAILER_BRAKE_CONFIG : 37|1@0+ (1,0) [0|1] "SED" Vector__XXX
 SG_ Power_Liftgate_Mode_Cmd : 39|1@0+ (1,0) [0|1] "SED" Vector__XXX
 SG_ AccEnbl_B_RqDrv : 35|1@0+ (1,0) [0|1] "SED"  IPMA_ADAS
 SG_ OdometerMasterValue : 15|24@0+ (1,0) [0|16777214] "km"  VDM,SOBDMC_HPCM_FD1,TCCM,CMR_DSMC,ABS_ESC,ECM_Diesel,IPMA_ADAS,PCM,PCM_HEV,PSCM,TCM_DSL
 SG_ EngOilLife_B_RqReset : 43|1@0+ (1,0) [0|1] "SED"  ECM_Diesel,PCM,PCM_HEV
 SG_ ePRNDL_MODE : 0|1@0+ (1,0) [0|1] "SED"  PCM,PCM_HEV,TCM_DSL
 SG_ DrvSlipCtlMde_B_Rq2 : 34|1@0+ (1,0) [0|1] "SED"  ABS_ESC
 SG_ MetricActv_B_Actl : 6|1@0+ (1,0) [0|1] "SED"  ECM_Diesel,IPMA_ADAS,PCM,PCM_HEV
 SG_ KeyTypeChngMykey_D_Rq : 41|2@0+ (1,0) [0|3] "SED" Vector__XXX
 SG_ ManRgen_D_Rq : 5|2@0+ (1,0) [0|3] "SED"  ECM_Diesel

BO_ 963 BCM_Lamp_Stat_FD1: 8 GWM
 SG_ Illuminated_Entry_Stat : 63|2@0+ (1,0) [0|3] "SED" Vector__XXX
 SG_ Dr_Courtesy_Light_Stat : 49|2@0+ (1,0) [0|3] "SED" Vector__XXX
 SG_ Courtesy_Delay_Status : 51|2@0+ (1,0) [0|3] "SED" Vector__XXX
 SG_ ImpactEvntFdbck_D_Stat : 53|2@0+ (1,0) [0|3] "SED"  CMR_DSMC
 SG_ WrlssAcsyChrgInhbt_B_Rq : 40|1@0+ (1,0) [0|1] "SED" Vector__XXX
 SG_ PudLampPsngr_D_Rq : 57|2@0+ (1,0) [0|3] "SED" Vector__XXX
 SG_ HeadLampLoOut_B_Stat : 32|1@0+ (1,0) [0|1] "SED" Vector__XXX
 SG_ CrnrLghtRight_Pc_Rq : 47|7@0+ (1,0) [0|100] "percent" Vector__XXX
 SG_ CrnrLghtLeft_Pc_Rq : 39|7@0+ (1,0) [0|100] "percent" Vector__XXX
 SG_ HeadLghtHiFdbck_D_Stat : 55|2@0+ (1,0) [0|3] "SED" Vector__XXX
 SG_ PudLampDrv_D_Rq : 59|2@0+ (1,0) [0|3] "SED" Vector__XXX
 SG_ TrnNotInPrkChime_B_Rq : 24|1@0+ (1,0) [0|1] "SED" Vector__XXX
 SG_ PrkLightChime_B_Rq : 25|1@0+ (1,0) [0|1] "SED" Vector__XXX
 SG_ KeyInIgnWarn_B_Cmd : 27|1@0+ (1,0) [0|1] "SED" Vector__XXX
 SG_ HomeSafeLtChime_B_Rq : 28|1@0+ (1,0) [0|1] "SED" Vector__XXX
 SG_ StopLghtOn_B_Stat : 8|1@0+ (1,0) [0|1] "SED" Vector__XXX
 SG_ RvrseLghtOn_B_Stat : 9|1@0+ (1,0) [0|1] "SED" Vector__XXX
 SG_ PrkLght_D_Stat : 13|2@0+ (1,0) [0|3] "SED" Vector__XXX
 SG_ HeadLghtSwtch_D_Stat : 15|2@0+ (1,0) [0|3] "SED"  IPMA_ADAS
 SG_ HeadLampLoFrOn_B_Stat : 2|1@0+ (1,0) [0|1] "SED"  IPMA_ADAS
 SG_ HeadLampLoFlOn_B_Stat : 3|1@0+ (1,0) [0|1] "SED"  IPMA_ADAS
 SG_ HeadLampLoActv_B_Stat : 4|1@0+ (1,0) [0|1] "SED"  IPMA_ADAS,PCM,ECM_Diesel
 SG_ Headlamp_On_Wrning_Cmd : 29|1@0+ (1,0) [0|1] "SED" Vector__XXX
 SG_ Park_Brake_Chime_Rqst : 26|1@0+ (1,0) [0|1] "SED" Vector__XXX
 SG_ HeadLghtHiOn_B_Stat : 1|1@0+ (1,0) [0|1] "SED"  ECM_Diesel,IPMA_ADAS,PCM
 SG_ BrkWarnInd_B_Rq : 20|1@0+ (1,0) [0|1] "SED" Vector__XXX
 SG_ Brk_Fluid_Lvl_Low : 31|2@0+ (1,0) [0|3] "SED" Vector__XXX
 SG_ ReducedGuard_D_Stat : 19|2@0+ (1,0) [0|3] "SED" Vector__XXX
 SG_ Perimeter_Alarm_Status : 17|2@0+ (1,0) [0|3] "SED" Vector__XXX
 SG_ Courtesy_BSave_Stat : 7|2@0+ (1,0) [0|3] "SED" Vector__XXX
 SG_ DrTgateLck_D_Stat : 61|2@0+ (1,0) [0|3] "SED" Vector__XXX
 SG_ WndwGlbl_D_Cmd : 23|3@0+ (1,0) [0|7] "SED" Vector__XXX
 SG_ PudLamp_D_Rq : 11|2@0+ (1,0) [0|3] "SED" Vector__XXX
 SG_ DayRnngLampOn_B_Stat : 5|1@0+ (1,0) [0|1] "SED" Vector__XXX
 SG_ PerimeterAlarmChimeRq : 0|1@0+ (1,0) [0|1] "SED" Vector__XXX

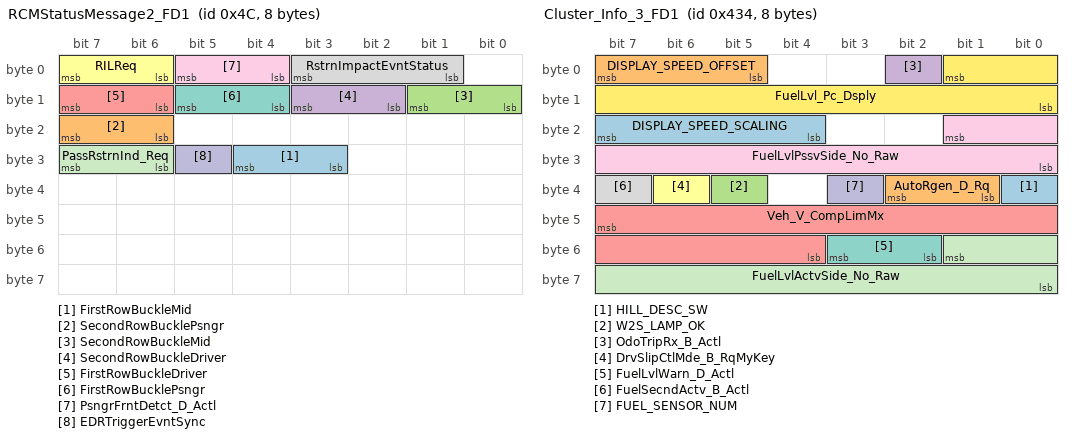
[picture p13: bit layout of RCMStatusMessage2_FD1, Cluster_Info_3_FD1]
BO_ 76 RCMStatusMessage2_FD1: 8 GWM
 SG_ FirstRowBuckleMid : 28|2@0+ (1,0) [0|3] "SED"  IPMA_ADAS
 SG_ SecondRowBucklePsngr : 23|2@0+ (1,0) [0|3] "SED" Vector__XXX
 SG_ SecondRowBuckleMid : 9|2@0+ (1,0) [0|3] "SED" Vector__XXX
 SG_ SecondRowBuckleDriver : 11|2@0+ (1,0) [0|3] "SED" Vector__XXX
 SG_ FirstRowBuckleDriver : 15|2@0+ (1,0) [0|3] "SED"  CMR_DSMC,ABS_ESC,IPMA_ADAS,ECM_Diesel,PCM,PCM_HEV,TCM_DSL
 SG_ RILReq : 7|2@0+ (1,0) [0|3] "SED" Vector__XXX
 SG_ FirstRowBucklePsngr : 13|2@0+ (1,0) [0|3] "SED"  IPMA_ADAS
 SG_ RstrnImpactEvntStatus : 3|3@0+ (1,0) [0|7] "SED"  CMR_DSMC,SOBDMC_HPCM_FD1,ABS_ESC,IPMA_ADAS,ECM_Diesel,PCM,PCM_HEV,TCM_DSL
 SG_ PsngrFrntDetct_D_Actl : 5|2@0+ (1,0) [0|3] "SED" Vector__XXX
 SG_ EDRTriggerEvntSync : 29|1@0+ (1,0) [0|1] "SED"  IPMA_ADAS
 SG_ PassRstrnInd_Req : 31|2@0+ (1,0) [0|3] "SED" Vector__XXX

BO_ 65 Global_PATS_Cntrl_Info_FD1: 8 GWM
 SG_ immoControlData_T1 : 15|40@0+ (1,0) [0|1.0995116278e+12] "Encrypted"  ECM_Diesel,PCM,PCM_HEV
 SG_ immoControlCmd_T1 : 7|3@0+ (1,0) [0|7] "SED"  ECM_Diesel,PCM,PCM_HEV

BO_ 1076 Cluster_Info_3_FD1: 8 GWM
 SG_ HILL_DESC_SW : 32|1@0+ (1,0) [0|1] "SED"  ABS_ESC
 SG_ AutoRgen_D_Rq : 34|2@0+ (1,0) [0|3] "SED"  ECM_Diesel
 SG_ W2S_LAMP_OK : 37|1@0+ (1,0) [0|1] "SED" Vector__XXX
 SG_ OdoTripRx_B_Actl : 2|1@0+ (1,0) [0|1] "SED"  ECM_Diesel,PCM,PCM_HEV
 SG_ Veh_V_CompLimMx : 47|12@0+ (0.1,0) [0|409.5] "km/h"  ECM_Diesel,PCM,PCM_HEV
 SG_ DrvSlipCtlMde_B_RqMyKey : 38|1@0+ (1,0) [0|1] "SED"  ABS_ESC
 SG_ FuelLvlWarn_D_Actl : 51|2@0+ (1,0) [0|3] "SED" Vector__XXX
 SG_ FuelSecndActv_B_Actl : 39|1@0+ (1,0) [0|1] "SED" Vector__XXX
 SG_ FuelLvlPssvSide_No_Raw : 17|10@0+ (1,0) [0|1023] "Unitless"  ECM_Diesel,PCM,PCM_HEV
 SG_ FUEL_SENSOR_NUM : 35|1@0+ (1,0) [0|1] "SED"  ECM_Diesel,PCM,PCM_HEV
 SG_ FuelLvlActvSide_No_Raw : 49|10@0+ (1,0) [0|1023] "Unitless"  ECM_Diesel,PCM,PCM_HEV
 SG_ FuelLvl_Pc_Dsply : 1|10@0+ (0.108696,-5.217408) [-5.217408|105.9786] "Percent"  VDM,ECM_Diesel
 SG_ DISPLAY_SPEED_SCALING : 23|4@0+ (0.5,100) [100|107.5] "%"  IPMA_ADAS,ECM_Diesel,PCM,PCM_HEV
 SG_ DISPLAY_SPEED_OFFSET : 7|3@0+ (0.5,0) [0|3.5] "kph"  IPMA_ADAS,ECM_Diesel,PCM,PCM_HEV

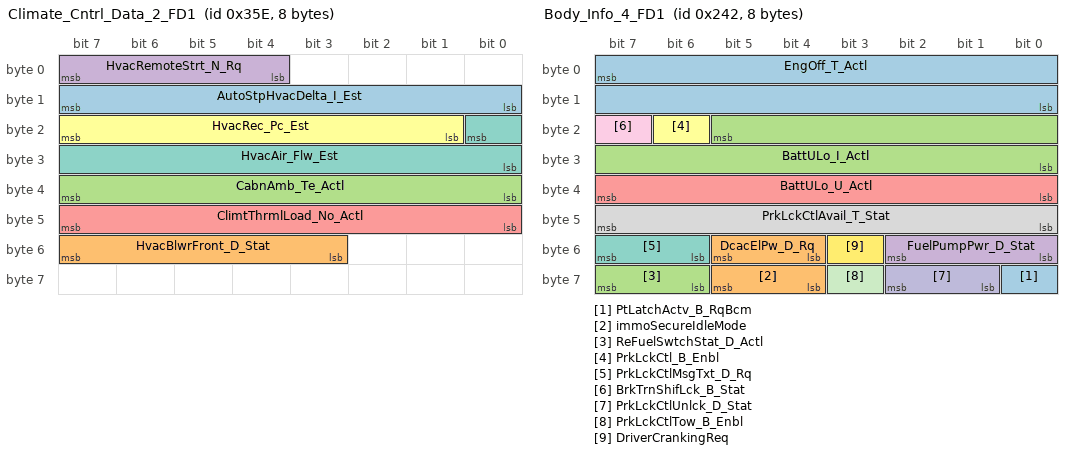
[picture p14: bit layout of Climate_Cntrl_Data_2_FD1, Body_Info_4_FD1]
BO_ 862 Climate_Cntrl_Data_2_FD1: 8 GWM
 SG_ AutoStpHvacDelta_I_Est : 15|8@0+ (1,-192) [-192|62] "ampere" Vector__XXX
 SG_ HvacBlwrFront_D_Stat : 55|5@0+ (1,0) [0|31] "SED"  ECM_Diesel,PCM,PCM_HEV
 SG_ CabnAmb_Te_Actl : 39|8@0+ (0.5,-57) [-57|70] "degreesC"  SOBDMC_HPCM_FD1,PCM_HEV
 SG_ HvacRemoteStrt_N_Rq : 7|4@0+ (100,450) [450|1950] "RPM"  ECM_Diesel,PCM,PCM_HEV
 SG_ ClimtThrmlLoad_No_Actl : 47|8@0+ (1,0) [0|254] "unitless"  SOBDMC_HPCM_FD1,PCM_HEV
 SG_ HvacRec_Pc_Est : 23|7@0+ (1,0) [0|127] "Percent"  PCM_HEV,SOBDMC_HPCM_FD1
 SG_ HvacAir_Flw_Est : 16|9@0+ (0.5,0) [0|255.5] "liter/second"  SOBDMC_HPCM_FD1

BO_ 578 Body_Info_4_FD1: 8 GWM
 SG_ PtLatchActv_B_RqBcm : 56|1@0+ (1,0) [0|1] "SED"  ECM_Diesel,PCM,PCM_HEV,TCM_DSL
 SG_ immoSecureIdleMode : 61|2@0+ (1,0) [0|3] "SED"  ECM_Diesel,PCM,PCM_HEV
 SG_ ReFuelSwtchStat_D_Actl : 63|2@0+ (1,0) [0|3] "SED" Vector__XXX
 SG_ FuelPumpPwr_D_Stat : 50|3@0+ (1,0) [0|7] "SED"  ECM_Diesel,PCM,PCM_HEV
 SG_ BattULo_U_Actl : 39|8@0+ (0.0625,0) [0|15.875] "volt"  CMR_DSMC,SOBDMC_HPCM_FD1,ABS_ESC,IPMA_ADAS,PSCM,ECM_Diesel,PCM,PCM_HEV
 SG_ PrkLckCtl_B_Enbl : 22|1@0+ (1,0) [0|1] "SED" Vector__XXX
 SG_ PrkLckCtlMsgTxt_D_Rq : 55|2@0+ (1,0) [0|3] "SED" Vector__XXX
 SG_ PrkLckCtlAvail_T_Stat : 47|8@0+ (1,0) [0|255] "second" Vector__XXX
 SG_ BrkTrnShifLck_B_Stat : 23|1@0+ (1,0) [0|1] "SED"  PCM,PCM_HEV,TCM_DSL
 SG_ PrkLckCtlUnlck_D_Stat : 58|2@0+ (1,0) [0|3] "SED" Vector__XXX
 SG_ PrkLckCtlTow_B_Enbl : 59|1@0+ (1,0) [0|1] "SED" Vector__XXX
 SG_ DriverCrankingReq : 51|1@0+ (1,0) [0|1] "SED"  ECM_Diesel,PCM,PCM_HEV
 SG_ EngOff_T_Actl : 7|16@0+ (1,0) [0|65534] "second^0.5"  ABS_ESC,IPMA_ADAS,TCCM,ECM_Diesel,PCM,PCM_HEV,TCM_DSL
 SG_ DcacElPw_D_Rq : 53|2@0+ (1,0) [0|3] "SED"  ECM_Diesel,PCM
 SG_ BattULo_I_Actl : 21|14@0+ (0.0625,-512) [-512|511.875] "ampere"  ECM_Diesel,PCM,PCM_HEV

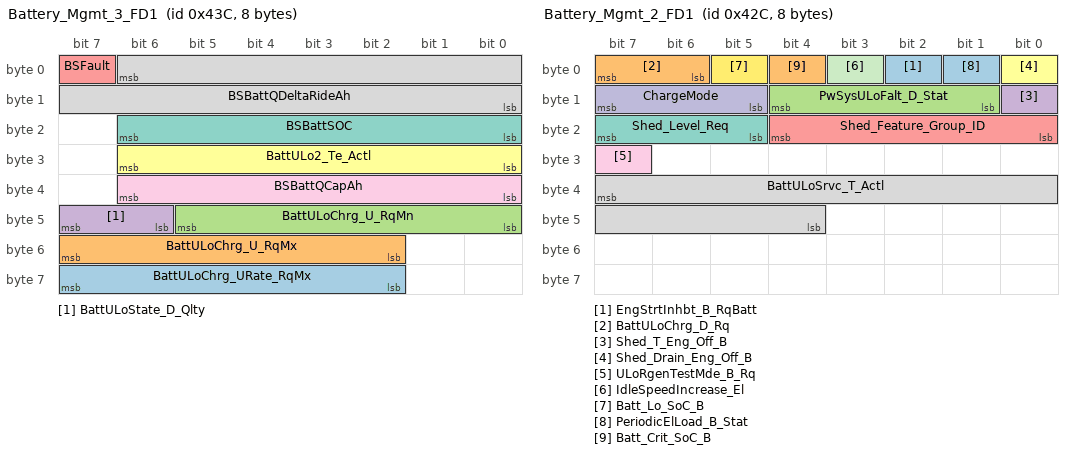
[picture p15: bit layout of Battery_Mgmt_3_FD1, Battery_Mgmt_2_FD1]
BO_ 1084 Battery_Mgmt_3_FD1: 8 GWM
 SG_ BattULoChrg_URate_RqMx : 63|6@0+ (0.1,0) [0|6.3] "volts/second"  ECM_Diesel,PCM,PCM_HEV
 SG_ BattULoChrg_U_RqMx : 55|6@0+ (0.1,10.6) [10.6|16.9] "volt"  ECM_Diesel,PCM,PCM_HEV
 SG_ BattULoChrg_U_RqMn : 45|6@0+ (0.1,10.6) [10.6|16.9] "volt"  ECM_Diesel,PCM,PCM_HEV
 SG_ BattULoState_D_Qlty : 47|2@0+ (1,0) [0|3] "SED"  ECM_Diesel,PCM,PCM_HEV
 SG_ BSFault : 7|1@0+ (1,0) [0|1] "SED"  ECM_Diesel,PCM,PCM_HEV
 SG_ BattULo2_Te_Actl : 30|7@0+ (1,-40) [-40|86] "degC"  ECM_Diesel,PCM,PCM_HEV
 SG_ BSBattSOC : 22|7@0+ (1,0) [0|127] "%"  ECM_Diesel,PCM,PCM_HEV
 SG_ BSBattQDeltaRideAh : 6|15@0+ (0.0078125,-100) [-100|155.9921875] "ampere*hour"  ECM_Diesel,PCM,PCM_HEV
 SG_ BSBattQCapAh : 38|7@0+ (1,0) [0|127] "ampere*hour"  ECM_Diesel,PCM,PCM_HEV

BO_ 1068 Battery_Mgmt_2_FD1: 8 GWM
 SG_ EngStrtInhbt_B_RqBatt : 2|1@0+ (1,0) [0|1] "SED"  ECM_Diesel,PCM
 SG_ BattULoChrg_D_Rq : 7|2@0+ (1,0) [0|3] "SED"  ECM_Diesel,PCM
 SG_ PwSysULoFalt_D_Stat : 12|4@0+ (1,0) [0|15] "SED" Vector__XXX
 SG_ Shed_T_Eng_Off_B : 8|1@0+ (1,0) [0|1] "SED" Vector__XXX
 SG_ Shed_Feature_Group_ID : 20|5@0+ (1,0) [0|31] "SED"  ECM_Diesel,PCM,PCM_HEV,IPMA_ADAS
 SG_ Shed_Drain_Eng_Off_B : 0|1@0+ (1,0) [0|1] "SED" Vector__XXX
 SG_ Shed_Level_Req : 23|3@0+ (1,0) [0|7] "SED"  ECM_Diesel,PCM,PCM_HEV,IPMA_ADAS
 SG_ BattULoSrvc_T_Actl : 39|12@0+ (1,0) [0|4095] "days" Vector__XXX
 SG_ ULoRgenTestMde_B_Rq : 31|1@0+ (1,0) [0|1] "SED"  ECM_Diesel,PCM
 SG_ ChargeMode : 15|3@0+ (1,0) [0|7] "SED"  ECM_Diesel,PCM
 SG_ IdleSpeedIncrease_El : 3|1@0+ (1,0) [0|1] "SED" Vector__XXX
 SG_ Batt_Lo_SoC_B : 5|1@0+ (1,0) [0|1] "SED" Vector__XXX
 SG_ PeriodicElLoad_B_Stat : 1|1@0+ (1,0) [0|1] "SED"  ECM_Diesel
 SG_ Batt_Crit_SoC_B : 4|1@0+ (1,0) [0|1] "SED" Vector__XXX

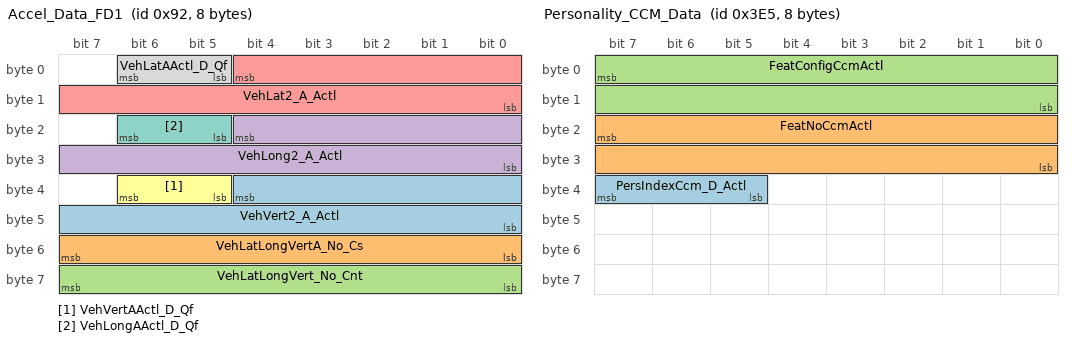
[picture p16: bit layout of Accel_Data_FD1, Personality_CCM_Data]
BO_ 146 Accel_Data_FD1: 8 GWM
 SG_ VehVert2_A_Actl : 36|13@0+ (0.01,-40) [-40|41.89] "m/s^2"  VDM,TCCM,IPMA_ADAS,ABS_ESC,ECM_Diesel
 SG_ VehLatLongVertA_No_Cs : 55|8@0+ (1,0) [0|255] "Unitless"  TCCM,IPMA_ADAS,ABS_ESC
 SG_ VehLatLongVert_No_Cnt : 63|8@0+ (1,0) [0|255] "Unitless"  VDM,TCCM,IPMA_ADAS,ABS_ESC
 SG_ VehLong2_A_Actl : 20|13@0+ (0.01,-40) [-40|41.89] "m/s^2"  VDM,TCCM,ABS_ESC,ECM_Diesel,IPMA_ADAS
 SG_ VehLat2_A_Actl : 4|13@0+ (0.01,-40) [-40|41.89] "m/s^2"  VDM,TCCM,ABS_ESC,ECM_Diesel,IPMA_ADAS
 SG_ VehVertAActl_D_Qf : 38|2@0+ (1,0) [0|3] "SED"  VDM,TCCM,IPMA_ADAS,ABS_ESC
 SG_ VehLongAActl_D_Qf : 22|2@0+ (1,0) [0|3] "SED"  VDM,TCCM,ABS_ESC,ECM_Diesel
 SG_ VehLatAActl_D_Qf : 6|2@0+ (1,0) [0|3] "SED"  VDM,TCCM,ABS_ESC

BO_ 997 Personality_CCM_Data: 8 IPMA_ADAS
 SG_ PersIndexCcm_D_Actl : 39|3@0+ (1,0) [0|7] "SED"  GWM
 SG_ FeatNoCcmActl : 23|16@0+ (1,0) [0|65535] "Number"  GWM
 SG_ FeatConfigCcmActl : 7|16@0+ (1,0) [0|65535] "Undefined"  GWM

CM_ SG_ 1046 TCMode "Signal data set to 0x0 for ABS only vehicle option content";
CM_ SG_ 1046 DrvAntiLckLamp_D_Rq "update value table v8.34, not align w/GSDB, need etracker.  ABS & IPC implemented as updated.";
CM_ SG_ 1046 BpedMove_D_Actl "CCMGenSigTimeoutTime=1000";
CM_ SG_ 534 BrkObdData_No_Actl "Signal not transmitted on gas, diesel and HEV.  Only supported on PHEV.";
CM_ SG_ 534 BrkObdIndex_No_Actl "Signal not transmitted on gas, diesel and HEV.  Only supported on PHEV.";
CM_ SG_ 534 WhlRotatRr_No_Cnt "DCR 1833 to update Tx from GWM to EP100ms. Wheel Count signals are used by complex algorithm to determine Tire Pressure by Location & can't change from 20msec. (jweinfur)";
CM_ SG_ 534 WhlRotatRl_No_Cnt "DCR 1833 to update Tx from GWM to EP100ms. Wheel Count signals are used by complex algorithm to determine Tire Pressure by Location & can't change from 20msec. (jweinfur)";
CM_ SG_ 534 WhlRotatFr_No_Cnt "DCR 1833 to update Tx from GWM to EP100ms. Wheel Count signals are used by complex algorithm to determine Tire Pressure by Location & can't change from 20msec. (jweinfur)";
CM_ SG_ 534 WhlRotatFl_No_Cnt "DCR 1833 to update Tx from GWM to EP100ms. Wheel Count signals are used by complex algorithm to determine Tire Pressure by Location & can't change from 20msec. (jweinfur)";
CM_ SG_ 531 VehLongOvrGnd_A_Est "CCMGenSigTimeoutTime=1000";
CM_ SG_ 1034 VehicleGGCCData "RCMGenSigTimeout=6000";
CM_ SG_ 560 SelDrvMdeSwtch_D_Stat3 "ECM_HEV,  PCM & PCM_HEV do not support or Transmit signal.";
CM_ SG_ 560 TrnSrvcRqd_B_Rq "Signal not transmitted on Diesel & HEV variants. MHT(U611/625) HPCM Rx 0x230 from PCM_HEV. Powersplit FWD HEVs(Cx482/3 430) HPCM Tx 0x230.";
CM_ SG_ 560 TrnShifActv_B_Actl " . MHT(U611/625) HPCM Rx 0x230 from PCM_HEV. Powersplit FWD HEVs(Cx482/3 430) HPCM Tx 0x230.";
CM_ SG_ 560 GboxOil_Te_Actl " . MHT(U611/625) HPCM Rx 0x230 from PCM_HEV. Powersplit FWD HEVs(Cx482/3 430) HPCM Tx 0x230.";
CM_ SG_ 369 SeatWorkSrfc_B_Falt "Signal Not transmitted by TCM_DSL";
CM_ SG_ 369 TrnIpcDsplyRng2_D_Actl " .";
CM_ SG_ 369 TrnIpcDsplyRng_D_Stat " .";
CM_ SG_ 1086 EngMnfld_P_Actl " ";
CM_ SG_ 1086 ElLoadCtl_D_Rq " .";
CM_ SG_ 1071 CluPdl_PcRate_Actl " .";
CM_ SG_ 1071 CluPdlPosPcMeas_D_Qf " .";
CM_ SG_ 1071 CluPdlPos_Pc_Meas " .";
CM_ SG_ 1071 EngAoutIdl_N_Ntrl "  and diesel.";
CM_ SG_ 1069 SlMde_D_Stat "IPC and HUD_ADV Receve from HS3 FGW 0x42D, not HS3 0x38A, MSG DCR 506. Signal not transmitted on Gas & HEV variants";
CM_ SG_ 1069 SlMde_D_RqDsply "IPC and HUD_ADV Receve from HS3 FGW 0x42D, not HS3 0x38A, MSG DCR 506. Signal not transmitted on Gas & HEV variants";
CM_ SG_ 1069 IsaOffst_D_Stat "Signal not transmitted on Gas & HEV variants";
CM_ SG_ 1069 ObdWarmUp_B_Complt "Signal not transmitted on diesel variants.";
CM_ SG_ 1069 EngMsgTxt_D_Rq "Signal not transmitted on diesel variants.";
CM_ SG_ 1069 EngClnt_Te_ActlDiag "Signal not transmitted on gas variants.";
CM_ SG_ 1069 EngLoad_Pc_CalcDiag "Signal not transmitted on gas variants.";
CM_ SG_ 1069 ApedPos_Pc_ActlDiag "Signal not transmitted on gas variants.";
CM_ SG_ 1060 RearDiffOilTeWarn_B_Rq " ";
CM_ SG_ 1060 RearDiffOil_Te_Actl " ";
CM_ SG_ 1057 FohEng_D_Rq "Signal not transmitted on vehicles that do not have the fuel operated heater feature. Signal not transmitted on HEV programs";
CM_ SG_ 1057 EngIdlShutDown_D_Stat "Signal not transmitted on diesel variants.";
CM_ SG_ 1057 FUEL_ALCOHOL_PERCNT "signal not transmitted on diesel and HEV variants.";
CM_ SG_ 1057 TrnTotTq_Rt_Est "Signal not transmitted on gas and HEV variants.";
CM_ SG_ 1057 TrnTotLss_Tq_Est "Signal not transmitted on gas and HEV variants.";
CM_ SG_ 1057 VehVLimStat_D_Actl "Signal not transmitted on gas and HEV variants.";
CM_ SG_ 1057 VehVLimActv_B_Actl "Signal not transmitted on gas and HEV variants.";
CM_ SG_ 516 EngAoutNActl_D_QF "Signal not transmitted on Gas & HEV variants";
CM_ SG_ 516 EngAout3_N_Actl "Signal not transmitted on gas and diesel variants.";
CM_ SG_ 516 ApedPos_Pc_ActlArb "ABSGenSigTimeoutTime=1000";
CM_ SG_ 516 ApedPosPcActl_No_Cnt "Signal not transmitted on gas and diesel variants.";
CM_ SG_ 516 ApedPosPcActl_No_Cs "Signal not transmitted on gas and diesel variants.";
CM_ SG_ 514 VehVTrlrAid_B_Avail " .";
CM_ SG_ 514 GearRvrse_D_Actl "Do not implement GearRvrse_D_Actl  until eTracker 8804151 is approved, 11/24/09";
CM_ SG_ 512 PrplWhlTotTqRq_No_Cs "Signal not transmitted on gas & Diesel variants.";
CM_ SG_ 512 PrplWhlTotTqRq_No_Cnt "Signal not transmitted on gas & Diesel variants.";
CM_ SG_ 512 PtDrvMde_D_Stat "Signal not transmitted on Gas & HEV variants.";
CM_ SG_ 377 HvacAirFullOut_B_Rq "Signal not transmitted on diesel variant";
CM_ SG_ 377 FuelFlw_Vl_Dsply "Signal not transmitted on diesel variants.";
CM_ SG_ 377 FuelFillInlet_B_Dsply "Signal not transmitted on diesel variants.";
CM_ SG_ 377 OdoCount "Signal not transmitted on diesel variants.";
CM_ SG_ 377 EngOilLife_Pc_Actl "Signal not transmitted on diesel variants.";
CM_ SG_ 377 FuelFilterLamp_B_Dsply "Signal not transmitted on Gas & HEV variants";
CM_ SG_ 377 AirCondRec_B_Rq "Signal not transmitted on diesel variants.";
CM_ SG_ 377 AirCondClutch_B_Stats "Signal not transmitted on diesel variants.";
CM_ SG_ 376 GasPrtc_D_RqDsply "Signal not transmitted on HEV & Diesel variants.";
CM_ SG_ 376 EngAout_Aa_Actl " .";
CM_ SG_ 376 AslIconDsply_D_Rq " .";
CM_ SG_ 376 AslChime_B_Rq " .";
CM_ SG_ 376 HvacHtrCore2_Te_Actl "Signal not transmitted on Gas & Diesel variants";
CM_ SG_ 376 EcssLamp_D_RqDsply "Signal not transmitted on Gas & HEV variants";
CM_ SG_ 376 AirAmb_Te_Actl "Signal not transmitted on Gas variants";
CM_ SG_ 359 PrplWhlRgenMn_Tq_Actl "Signal not transmitted on Gas & Diesel variants";
CM_ SG_ 359 ElPw_D_StatStrtStop " .";
CM_ SG_ 359 TrnAin_Tq_Actl "Signal not transmitted on HEV variances.";
CM_ SG_ 359 PlgActvArb_B_Actl "Only supported on PHEV programs.  PlgActvArb_B_Actl HPCM will Tx on Powersplit PHEVs,  On MHT PHEVs the PCM_HEV will Tx and HPCM will Rx.";
CM_ SG_ 359 TrnAinTq_D_Qf "Signal not transmitted on HEV variances.";
CM_ SG_ 358 StopStrtStdby_D_Indic " .";
CM_ SG_ 358 StopStrtIODTxt_D_Rq " .";
CM_ SG_ 358 StopStrtDrvMde_D_Indic " .";
CM_ SG_ 358 StopStrtMsgTxt_D_Rq " .";
CM_ SG_ 358 HiElPwInhbt_B_Stat "Signal not transmitted on HEV programs";
CM_ SG_ 358 AutoStopPtDelta_I_Est " . ";
CM_ SG_ 357 BpedDrvAppl_D_Actl "CCMGenSigTimeoutTime=1000";
CM_ SG_ 357 CcStat_D_Actl "ABSGenSigTimeoutTime=1000";
CM_ SG_ 357 EngAout_N_MnAllw "Signal not transmitted on Gas & Diesel variants.";
CM_ SG_ 357 AccStopMde_D_Rq "ABSGenSigTimeoutTime=1000";
CM_ SG_ 342 EngOvrhtMitgActv_D_Ind "Signal not transmitted on diesel.";
CM_ SG_ 342 EngGoutLss_Tq_Est "Signal not transmitted on gas and diesel variants.";
CM_ SG_ 342 EngOil_Te_Actl "Signal not transmitted on Gas & HEV variants. ";
CM_ SG_ 1072 MetricActv_B_Actl "0 =Inactive(English), 1=Active(Metric)";
BA_DEF_ SG_  "ECGUsedRxSignal" ENUM  "No","Yes";
BA_DEF_ SG_  "ECGUsedTxSignal" ENUM  "No","Yes";
BA_DEF_ BO_  "VFrameFormat" ENUM  "StandardCAN","ExtendedCAN","reserved","reserved","reserved","reserved","reserved","reserved","reserved","reserved","reserved","reserved","reserved","reserved","StandardCAN_FD","ExtendedCAN_FD";
BA_DEF_ BO_  "FrameRouting" STRING ;
BA_DEF_ BO_  "FrameGatewayNetwork" STRING ;
BA_DEF_ BO_  "NetworkInitialization" ENUM  "No","Yes";
BA_DEF_ BO_  "FrameGatewayId" HEX 0 1407;
BA_DEF_ BO_  "EventRateOfChange" INT 10 10000;
BA_DEF_ BO_  "GenMsgNrOfRepetition" INT 0 100;
BA_DEF_ BO_  "GenMsgDelayTime" INT 0 1000;
BA_DEF_ BO_  "GenMsgCycleTime" INT 0 100000;
BA_DEF_ BO_  "GenMsgSendType" ENUM  "FixedPeriodic","Event","EnabledPeriodic","NotUsed","NotUsed","EventPeriodic","NotUsed","NotUsed","NoMsgSendType";
BA_DEF_ SG_  "U_T6_MCA_MY2020_Tx" ENUM  "No","Yes";
BA_DEF_ SG_  "U_P702_MY2021_Tx" ENUM  "No","Yes";
BA_DEF_ SG_  "U_CX727_MY2021_Tx" ENUM  "No","Yes";
BA_DEF_ SG_  "U_T6_MCA_MY2020_Rx" ENUM  "No","Yes";
BA_DEF_ SG_  "U_P702_MY2021_Rx" ENUM  "No","Yes";
BA_DEF_ SG_  "U_CX727_MY2021_Rx" ENUM  "No","Yes";
BA_DEF_ SG_  "GenSigStartValue" HEX 0 268435455;
BA_DEF_ SG_  "MetaData" ENUM  "No","Yes";
BA_DEF_ SG_  "ContentDependant" ENUM  "No","Yes";
BA_DEF_ SG_  "GenSigStartValueInteger" INT 0 1000000000;
BA_DEF_ SG_  "UsedOnPgmDBC" ENUM  "No","Yes";
BA_DEF_ SG_  " _InfoCAN" ENUM  "No","Yes";
BA_DEF_ SG_  "WakeupSignal" ENUM  "No","Yes";
BA_DEF_ SG_  "GenSigSendType" ENUM  "Cyclic","OnWrite","vector_leerstring","OnChange","vector_leerstring","IfActive","vector_leerstring","NoSigSendType";
BA_DEF_ BO_  "SCP_FreshnessValueLength" INT 0 512;
BA_DEF_ BO_  "AuthFreshnessCounterSyncAttempt" INT 0 512;
BA_DEF_ BO_  "SCP_FreshnessValueTxLength" INT 0 512;
BA_DEF_ BO_  "SCP_AuthInfoTxLength" INT 0 512;
BA_DEF_ BO_  "NmAsrMessage" ENUM  "No","Yes";
BA_DEF_ BO_  "DiagResponse" ENUM  "No","Yes";
BA_DEF_ BO_  "GenMsgILSupport" ENUM  "No","Yes";
BA_DEF_DEF_  "ECGUsedRxSignal" "No";
BA_DEF_DEF_  "ECGUsedTxSignal" "No";
BA_DEF_DEF_  "VFrameFormat" "ExtendedCAN_FD";
BA_DEF_DEF_  "FrameRouting" "NONE";
BA_DEF_DEF_  "FrameGatewayNetwork" "NONE";
BA_DEF_DEF_  "NetworkInitialization" "Yes";
BA_DEF_DEF_  "FrameGatewayId" 0;
BA_DEF_DEF_  "EventRateOfChange" 10000;
BA_DEF_DEF_  "GenMsgNrOfRepetition" 1;
BA_DEF_DEF_  "GenMsgDelayTime" 20;
BA_DEF_DEF_  "GenMsgCycleTime" 0;
BA_DEF_DEF_  "GenMsgSendType" "NoMsgSendType";
BA_DEF_DEF_  "U_T6_MCA_MY2020_Tx" "No";
BA_DEF_DEF_  "U_P702_MY2021_Tx" "No";
BA_DEF_DEF_  "U_CX727_MY2021_Tx" "No";
BA_DEF_DEF_  "U_T6_MCA_MY2020_Rx" "No";
BA_DEF_DEF_  "U_P702_MY2021_Rx" "No";
BA_DEF_DEF_  "U_CX727_MY2021_Rx" "No";
BA_DEF_DEF_  "GenSigStartValue" 0;
BA_DEF_DEF_  "MetaData" "No";
BA_DEF_DEF_  "ContentDependant" "No";
BA_DEF_DEF_  "GenSigStartValueInteger" 0;
BA_DEF_DEF_  "UsedOnPgmDBC" "Yes";
BA_DEF_DEF_  " _InfoCAN" "No";
BA_DEF_DEF_  "WakeupSignal" "No";
BA_DEF_DEF_  "GenSigSendType" "NoSigSendType";
BA_DEF_DEF_  "SCP_FreshnessValueLength" 64;
BA_DEF_DEF_  "AuthFreshnessCounterSyncAttempt" 2;
BA_DEF_DEF_  "SCP_FreshnessValueTxLength" 8;
BA_DEF_DEF_  "SCP_AuthInfoTxLength" 56;
BA_DEF_DEF_  "NmAsrMessage" "No";
BA_DEF_DEF_  "DiagResponse" "No";
BA_DEF_DEF_  "GenMsgILSupport" "Yes";
BA_ "FrameRouting" BO_ 1046 "";
BA_ "GenMsgSendType" BO_ 1046 0;
BA_ "GenMsgCycleTime" BO_ 1046 100;
BA_ "VFrameFormat" BO_ 1046 14;
BA_ " _InfoCAN" SG_ 1046 HsaMde_D_Mem 1;
BA_ "GenSigStartValueInteger" SG_ 1046 HsaMde_D_Mem 1;
BA_ "GenSigStartValue" SG_ 1046 HsaMde_D_Mem 1;
BA_ "U_CX727_MY2021_Tx" SG_ 1046 HsaMde_D_Mem 1;
BA_ "U_P702_MY2021_Tx" SG_ 1046 HsaMde_D_Mem 1;
BA_ " _InfoCAN" SG_ 1046 BrkBstrVac_B_Rq 1;
BA_ "U_P702_MY2021_Rx" SG_ 1046 BrkBstrVac_B_Rq 1;
BA_ "U_T6_MCA_MY2020_Rx" SG_ 1046 BrkBstrVac_B_Rq 1;
BA_ "U_CX727_MY2021_Tx" SG_ 1046 BrkBstrVac_B_Rq 1;
BA_ "U_P702_MY2021_Tx" SG_ 1046 BrkBstrVac_B_Rq 1;
BA_ " _InfoCAN" SG_ 1046 HdcMde_D_Actl 1;
BA_ "U_CX727_MY2021_Tx" SG_ 1046 HdcMde_D_Actl 1;
BA_ "U_P702_MY2021_Tx" SG_ 1046 HdcMde_D_Actl 1;
BA_ "GenSigStartValueInteger" SG_ 1046 RearDiffLck_Tq2_RqMx 4094;
BA_ "GenSigStartValue" SG_ 1046 RearDiffLck_Tq2_RqMx 4094;
BA_ "U_CX727_MY2021_Tx" SG_ 1046 RearDiffLck_Tq2_RqMx 1;
BA_ "U_P702_MY2021_Tx" SG_ 1046 RearDiffLck_Tq2_RqMx 1;
BA_ "U_CX727_MY2021_Tx" SG_ 1046 TRLR_SWAY_EVNT_IN_PROG 1;
BA_ "U_P702_MY2021_Tx" SG_ 1046 TRLR_SWAY_EVNT_IN_PROG 1;
BA_ "ECGUsedRxSignal" SG_ 1046 TRLR_SWAY_EVNT_IN_PROG 1;
BA_ "U_CX727_MY2021_Tx" SG_ 1046 TRLR_SWAY_CONFIG_STAT 1;
BA_ "U_P702_MY2021_Tx" SG_ 1046 TRLR_SWAY_CONFIG_STAT 1;
BA_ " _InfoCAN" SG_ 1046 TCMode 1;
BA_ "ContentDependant" SG_ 1046 TCMode 1;
BA_ "U_P702_MY2021_Rx" SG_ 1046 TCMode 1;
BA_ "U_T6_MCA_MY2020_Rx" SG_ 1046 TCMode 1;
BA_ "U_CX727_MY2021_Tx" SG_ 1046 TCMode 1;
BA_ "U_P702_MY2021_Tx" SG_ 1046 TCMode 1;
BA_ "ECGUsedRxSignal" SG_ 1046 TCMode 1;
BA_ " _InfoCAN" SG_ 1046 DrvSlipCtlLamp_D_Rq 1;
BA_ "U_P702_MY2021_Rx" SG_ 1046 DrvSlipCtlLamp_D_Rq 1;
BA_ "U_T6_MCA_MY2020_Rx" SG_ 1046 DrvSlipCtlLamp_D_Rq 1;
BA_ "U_CX727_MY2021_Tx" SG_ 1046 DrvSlipCtlLamp_D_Rq 1;
BA_ "U_P702_MY2021_Tx" SG_ 1046 DrvSlipCtlLamp_D_Rq 1;
BA_ " _InfoCAN" SG_ 1046 Abs_B_Falt 1;
BA_ "U_P702_MY2021_Rx" SG_ 1046 Abs_B_Falt 1;
BA_ "U_T6_MCA_MY2020_Rx" SG_ 1046 Abs_B_Falt 1;
BA_ "U_CX727_MY2021_Tx" SG_ 1046 Abs_B_Falt 1;
BA_ "U_P702_MY2021_Tx" SG_ 1046 Abs_B_Falt 1;
BA_ "ECGUsedRxSignal" SG_ 1046 Abs_B_Falt 1;
BA_ " _InfoCAN" SG_ 1046 DrvSlipCtlMde_D_Ind 1;
BA_ "U_P702_MY2021_Rx" SG_ 1046 DrvSlipCtlMde_D_Ind 1;
BA_ "U_T6_MCA_MY2020_Rx" SG_ 1046 DrvSlipCtlMde_D_Ind 1;
BA_ "U_CX727_MY2021_Tx" SG_ 1046 DrvSlipCtlMde_D_Ind 1;
BA_ "U_P702_MY2021_Tx" SG_ 1046 DrvSlipCtlMde_D_Ind 1;
BA_ "ECGUsedRxSignal" SG_ 1046 DrvSlipCtlMde_D_Ind 1;
BA_ " _InfoCAN" SG_ 1046 DrvAntiLckLamp_D_Rq 1;
BA_ "U_P702_MY2021_Rx" SG_ 1046 DrvAntiLckLamp_D_Rq 1;
BA_ "U_T6_MCA_MY2020_Rx" SG_ 1046 DrvAntiLckLamp_D_Rq 1;
BA_ "U_CX727_MY2021_Tx" SG_ 1046 DrvAntiLckLamp_D_Rq 1;
BA_ "U_P702_MY2021_Tx" SG_ 1046 DrvAntiLckLamp_D_Rq 1;
BA_ " _InfoCAN" SG_ 1046 BpedMove_No_Cnt 1;
BA_ "MetaData" SG_ 1046 BpedMove_No_Cnt 1;
BA_ "U_P702_MY2021_Rx" SG_ 1046 BpedMove_No_Cnt 1;
BA_ "U_CX727_MY2021_Tx" SG_ 1046 BpedMove_No_Cnt 1;
BA_ "U_P702_MY2021_Tx" SG_ 1046 BpedMove_No_Cnt 1;
BA_ " _InfoCAN" SG_ 1046 StabCtlBrk_B_Avail 1;
BA_ "GenSigStartValueInteger" SG_ 1046 StabCtlBrk_B_Avail 1;
BA_ "GenSigStartValue" SG_ 1046 StabCtlBrk_B_Avail 1;
BA_ "U_CX727_MY2021_Tx" SG_ 1046 StabCtlBrk_B_Avail 1;
BA_ "U_P702_MY2021_Tx" SG_ 1046 StabCtlBrk_B_Avail 1;
BA_ " _InfoCAN" SG_ 1046 DrvHdcWarnInfo_D_Rq 1;
BA_ "U_CX727_MY2021_Tx" SG_ 1046 DrvHdcWarnInfo_D_Rq 1;
BA_ "U_P702_MY2021_Tx" SG_ 1046 DrvHdcWarnInfo_D_Rq 1;
BA_ " _InfoCAN" SG_ 1046 DrvHdcMsg_D_Rq 1;
BA_ "U_CX727_MY2021_Tx" SG_ 1046 DrvHdcMsg_D_Rq 1;
BA_ "U_P702_MY2021_Tx" SG_ 1046 DrvHdcMsg_D_Rq 1;
BA_ " _InfoCAN" SG_ 1046 DrvHdcLampInfo_D_Rq 1;
BA_ "U_CX727_MY2021_Tx" SG_ 1046 DrvHdcLampInfo_D_Rq 1;
BA_ "U_P702_MY2021_Tx" SG_ 1046 DrvHdcLampInfo_D_Rq 1;
BA_ " _InfoCAN" SG_ 1046 BpedMove_D_Actl 1;
BA_ "GenSigStartValueInteger" SG_ 1046 BpedMove_D_Actl 3;
BA_ "GenSigStartValue" SG_ 1046 BpedMove_D_Actl 3;
BA_ "U_P702_MY2021_Rx" SG_ 1046 BpedMove_D_Actl 1;
BA_ "U_CX727_MY2021_Tx" SG_ 1046 BpedMove_D_Actl 1;
BA_ "U_P702_MY2021_Tx" SG_ 1046 BpedMove_D_Actl 1;
BA_ " _InfoCAN" SG_ 1046 ChimeBrk_B_Rq 1;
BA_ "U_CX727_MY2021_Tx" SG_ 1046 ChimeBrk_B_Rq 1;
BA_ "U_P702_MY2021_Tx" SG_ 1046 ChimeBrk_B_Rq 1;
BA_ " _InfoCAN" SG_ 1046 BrkLamp_B_Rq 1;
BA_ "U_CX727_MY2021_Tx" SG_ 1046 BrkLamp_B_Rq 1;
BA_ "U_P702_MY2021_Tx" SG_ 1046 BrkLamp_B_Rq 1;
BA_ " _InfoCAN" SG_ 1046 HILL_DESC_MC 1;
BA_ "U_CX727_MY2021_Tx" SG_ 1046 HILL_DESC_MC 1;
BA_ "U_P702_MY2021_Tx" SG_ 1046 HILL_DESC_MC 1;
BA_ "U_P702_MY2021_Tx" SG_ 1046 RearDiffElckrOpen_B_Rq 1;
BA_ "FrameRouting" BO_ 1045 "";
BA_ "GenMsgSendType" BO_ 1045 0;
BA_ "GenMsgCycleTime" BO_ 1045 20;
BA_ "GenMsgDelayTime" BO_ 1045 10;
BA_ "VFrameFormat" BO_ 1045 14;
BA_ "GenSigStartValueInteger" SG_ 1045 VehStab_D_Stat 14;
BA_ "GenSigStartValue" SG_ 1045 VehStab_D_Stat 14;
BA_ "U_P702_MY2021_Rx" SG_ 1045 VehStab_D_Stat 1;
BA_ "U_T6_MCA_MY2020_Rx" SG_ 1045 VehStab_D_Stat 1;
BA_ "U_CX727_MY2021_Tx" SG_ 1045 VehStab_D_Stat 1;
BA_ "U_P702_MY2021_Tx" SG_ 1045 VehStab_D_Stat 1;
BA_ "U_CX727_MY2021_Tx" SG_ 1045 BrkFluidLvl_D_Stat 1;
BA_ "U_P702_MY2021_Tx" SG_ 1045 BrkFluidLvl_D_Stat 1;
BA_ "U_P702_MY2021_Rx" SG_ 1045 LsmcBrkDecel_D_Stat 1;
BA_ "U_P702_MY2021_Tx" SG_ 1045 LsmcBrkDecel_D_Stat 1;
BA_ " _InfoCAN" SG_ 1045 VehYawNonLin_W_Rq 1;
BA_ "GenSigStartValueInteger" SG_ 1045 VehYawNonLin_W_Rq 4094;
BA_ "GenSigStartValue" SG_ 1045 VehYawNonLin_W_Rq 4094;
BA_ "U_P702_MY2021_Rx" SG_ 1045 VehYawNonLin_W_Rq 1;
BA_ "U_T6_MCA_MY2020_Rx" SG_ 1045 VehYawNonLin_W_Rq 1;
BA_ "U_CX727_MY2021_Tx" SG_ 1045 VehYawNonLin_W_Rq 1;
BA_ "U_P702_MY2021_Tx" SG_ 1045 VehYawNonLin_W_Rq 1;
BA_ " _InfoCAN" SG_ 1045 VehYawLin_W_Rq 1;
BA_ "GenSigStartValueInteger" SG_ 1045 VehYawLin_W_Rq 4094;
BA_ "GenSigStartValue" SG_ 1045 VehYawLin_W_Rq 4094;
BA_ "U_P702_MY2021_Rx" SG_ 1045 VehYawLin_W_Rq 1;
BA_ "U_T6_MCA_MY2020_Rx" SG_ 1045 VehYawLin_W_Rq 1;
BA_ "U_CX727_MY2021_Tx" SG_ 1045 VehYawLin_W_Rq 1;
BA_ "U_P702_MY2021_Tx" SG_ 1045 VehYawLin_W_Rq 1;
BA_ " _InfoCAN" SG_ 1045 VehVActlBrk_No_Cs 1;
BA_ "MetaData" SG_ 1045 VehVActlBrk_No_Cs 1;
BA_ "U_P702_MY2021_Rx" SG_ 1045 VehVActlBrk_No_Cs 1;
BA_ "U_T6_MCA_MY2020_Rx" SG_ 1045 VehVActlBrk_No_Cs 1;
BA_ "U_CX727_MY2021_Rx" SG_ 1045 VehVActlBrk_No_Cs 1;
BA_ "U_CX727_MY2021_Tx" SG_ 1045 VehVActlBrk_No_Cs 1;
BA_ "U_P702_MY2021_Tx" SG_ 1045 VehVActlBrk_No_Cs 1;
BA_ " _InfoCAN" SG_ 1045 Veh_V_ActlBrk 1;
BA_ "U_P702_MY2021_Rx" SG_ 1045 Veh_V_ActlBrk 1;
BA_ "U_T6_MCA_MY2020_Rx" SG_ 1045 Veh_V_ActlBrk 1;
BA_ "U_CX727_MY2021_Rx" SG_ 1045 Veh_V_ActlBrk 1;
BA_ "U_CX727_MY2021_Tx" SG_ 1045 Veh_V_ActlBrk 1;
BA_ "U_P702_MY2021_Tx" SG_ 1045 Veh_V_ActlBrk 1;
BA_ " _InfoCAN" SG_ 1045 VehVActlBrk_No_Cnt 1;
BA_ "MetaData" SG_ 1045 VehVActlBrk_No_Cnt 1;
BA_ "U_P702_MY2021_Rx" SG_ 1045 VehVActlBrk_No_Cnt 1;
BA_ "U_T6_MCA_MY2020_Rx" SG_ 1045 VehVActlBrk_No_Cnt 1;
BA_ "U_CX727_MY2021_Rx" SG_ 1045 VehVActlBrk_No_Cnt 1;
BA_ "U_CX727_MY2021_Tx" SG_ 1045 VehVActlBrk_No_Cnt 1;
BA_ "U_P702_MY2021_Tx" SG_ 1045 VehVActlBrk_No_Cnt 1;
BA_ " _InfoCAN" SG_ 1045 VehVActlBrk_D_Qf 1;
BA_ "MetaData" SG_ 1045 VehVActlBrk_D_Qf 1;
BA_ "U_P702_MY2021_Rx" SG_ 1045 VehVActlBrk_D_Qf 1;
BA_ "U_T6_MCA_MY2020_Rx" SG_ 1045 VehVActlBrk_D_Qf 1;
BA_ "U_CX727_MY2021_Rx" SG_ 1045 VehVActlBrk_D_Qf 1;
BA_ "U_CX727_MY2021_Tx" SG_ 1045 VehVActlBrk_D_Qf 1;
BA_ "U_P702_MY2021_Tx" SG_ 1045 VehVActlBrk_D_Qf 1;
BA_ "FrameRouting" BO_ 535 "";
BA_ "GenMsgSendType" BO_ 535 0;
BA_ "GenMsgCycleTime" BO_ 535 10;
BA_ "GenMsgDelayTime" BO_ 535 0;
BA_ "VFrameFormat" BO_ 535 14;
BA_ "U_P702_MY2021_Rx" SG_ 535 WhlRr_W_Meas 1;
BA_ "U_T6_MCA_MY2020_Rx" SG_ 535 WhlRr_W_Meas 1;
BA_ "U_CX727_MY2021_Rx" SG_ 535 WhlRr_W_Meas 1;
BA_ "U_CX727_MY2021_Tx" SG_ 535 WhlRr_W_Meas 1;
BA_ "U_P702_MY2021_Tx" SG_ 535 WhlRr_W_Meas 1;
BA_ "U_P702_MY2021_Rx" SG_ 535 WhlRl_W_Meas 1;
BA_ "U_T6_MCA_MY2020_Rx" SG_ 535 WhlRl_W_Meas 1;
BA_ "U_CX727_MY2021_Rx" SG_ 535 WhlRl_W_Meas 1;
BA_ "U_CX727_MY2021_Tx" SG_ 535 WhlRl_W_Meas 1;
BA_ "U_P702_MY2021_Tx" SG_ 535 WhlRl_W_Meas 1;
BA_ "U_P702_MY2021_Rx" SG_ 535 WhlFr_W_Meas 1;
BA_ "U_T6_MCA_MY2020_Rx" SG_ 535 WhlFr_W_Meas 1;
BA_ "U_CX727_MY2021_Rx" SG_ 535 WhlFr_W_Meas 1;
BA_ "U_CX727_MY2021_Tx" SG_ 535 WhlFr_W_Meas 1;
BA_ "U_P702_MY2021_Tx" SG_ 535 WhlFr_W_Meas 1;
BA_ "U_P702_MY2021_Rx" SG_ 535 WhlFl_W_Meas 1;
BA_ "U_T6_MCA_MY2020_Rx" SG_ 535 WhlFl_W_Meas 1;
BA_ "U_CX727_MY2021_Rx" SG_ 535 WhlFl_W_Meas 1;
BA_ "U_CX727_MY2021_Tx" SG_ 535 WhlFl_W_Meas 1;
BA_ "U_P702_MY2021_Tx" SG_ 535 WhlFl_W_Meas 1;
BA_ "FrameRouting" BO_ 534 "";
BA_ "GenMsgSendType" BO_ 534 0;
BA_ "GenMsgCycleTime" BO_ 534 20;
BA_ "GenMsgDelayTime" BO_ 534 10;
BA_ "VFrameFormat" BO_ 534 14;
BA_ "ContentDependant" SG_ 534 BrkObdData_No_Actl 1;
BA_ "U_CX727_MY2021_Tx" SG_ 534 BrkObdData_No_Actl 1;
BA_ "U_P702_MY2021_Tx" SG_ 534 BrkObdData_No_Actl 1;
BA_ "ContentDependant" SG_ 534 BrkObdIndex_No_Actl 1;
BA_ "U_CX727_MY2021_Tx" SG_ 534 BrkObdIndex_No_Actl 1;
BA_ "U_P702_MY2021_Tx" SG_ 534 BrkObdIndex_No_Actl 1;
BA_ " _InfoCAN" SG_ 534 WhlRotatRr_No_Cnt 1;
BA_ "U_P702_MY2021_Rx" SG_ 534 WhlRotatRr_No_Cnt 1;
BA_ "U_CX727_MY2021_Tx" SG_ 534 WhlRotatRr_No_Cnt 1;
BA_ "U_P702_MY2021_Tx" SG_ 534 WhlRotatRr_No_Cnt 1;
BA_ " _InfoCAN" SG_ 534 WhlDirRr_D_Actl 1;
BA_ "U_CX727_MY2021_Rx" SG_ 534 WhlDirRr_D_Actl 1;
BA_ "U_P702_MY2021_Rx" SG_ 534 WhlDirRr_D_Actl 1;
BA_ "U_T6_MCA_MY2020_Rx" SG_ 534 WhlDirRr_D_Actl 1;
BA_ "U_CX727_MY2021_Tx" SG_ 534 WhlDirRr_D_Actl 1;
BA_ "U_P702_MY2021_Tx" SG_ 534 WhlDirRr_D_Actl 1;
BA_ " _InfoCAN" SG_ 534 WhlDirRl_D_Actl 1;
BA_ "U_P702_MY2021_Rx" SG_ 534 WhlDirRl_D_Actl 1;
BA_ "U_T6_MCA_MY2020_Rx" SG_ 534 WhlDirRl_D_Actl 1;
BA_ "U_CX727_MY2021_Rx" SG_ 534 WhlDirRl_D_Actl 1;
BA_ "U_CX727_MY2021_Tx" SG_ 534 WhlDirRl_D_Actl 1;
BA_ "U_P702_MY2021_Tx" SG_ 534 WhlDirRl_D_Actl 1;
BA_ " _InfoCAN" SG_ 534 WhlDirFr_D_Actl 1;
BA_ "U_CX727_MY2021_Rx" SG_ 534 WhlDirFr_D_Actl 1;
BA_ "U_P702_MY2021_Rx" SG_ 534 WhlDirFr_D_Actl 1;
BA_ "U_T6_MCA_MY2020_Rx" SG_ 534 WhlDirFr_D_Actl 1;
BA_ "U_CX727_MY2021_Tx" SG_ 534 WhlDirFr_D_Actl 1;
BA_ "U_P702_MY2021_Tx" SG_ 534 WhlDirFr_D_Actl 1;
BA_ " _InfoCAN" SG_ 534 WhlDirFl_D_Actl 1;
BA_ "U_CX727_MY2021_Rx" SG_ 534 WhlDirFl_D_Actl 1;
BA_ "U_P702_MY2021_Rx" SG_ 534 WhlDirFl_D_Actl 1;
BA_ "U_T6_MCA_MY2020_Rx" SG_ 534 WhlDirFl_D_Actl 1;
BA_ "U_CX727_MY2021_Tx" SG_ 534 WhlDirFl_D_Actl 1;
BA_ "U_P702_MY2021_Tx" SG_ 534 WhlDirFl_D_Actl 1;
BA_ " _InfoCAN" SG_ 534 WhlRotatRl_No_Cnt 1;
BA_ "U_P702_MY2021_Rx" SG_ 534 WhlRotatRl_No_Cnt 1;
BA_ "U_CX727_MY2021_Tx" SG_ 534 WhlRotatRl_No_Cnt 1;
BA_ "U_P702_MY2021_Tx" SG_ 534 WhlRotatRl_No_Cnt 1;
BA_ " _InfoCAN" SG_ 534 WhlRotatFr_No_Cnt 1;
BA_ "U_P702_MY2021_Rx" SG_ 534 WhlRotatFr_No_Cnt 1;
BA_ "U_CX727_MY2021_Tx" SG_ 534 WhlRotatFr_No_Cnt 1;
BA_ "U_P702_MY2021_Tx" SG_ 534 WhlRotatFr_No_Cnt 1;
BA_ " _InfoCAN" SG_ 534 WhlRotatFl_No_Cnt 1;
BA_ "U_P702_MY2021_Rx" SG_ 534 WhlRotatFl_No_Cnt 1;
BA_ "U_CX727_MY2021_Tx" SG_ 534 WhlRotatFl_No_Cnt 1;
BA_ "U_P702_MY2021_Tx" SG_ 534 WhlRotatFl_No_Cnt 1;
BA_ "FrameRouting" BO_ 531 "";
BA_ "GenMsgSendType" BO_ 531 0;
BA_ "GenMsgCycleTime" BO_ 531 20;
BA_ "GenMsgDelayTime" BO_ 531 10;
BA_ "VFrameFormat" BO_ 531 14;
BA_ "GenSigStartValueInteger" SG_ 531 VehStop_D_Stat 2;
BA_ "GenSigStartValue" SG_ 531 VehStop_D_Stat 2;
BA_ "U_CX727_MY2021_Tx" SG_ 531 VehStop_D_Stat 1;
BA_ "U_P702_MY2021_Tx" SG_ 531 VehStop_D_Stat 1;
BA_ " _InfoCAN" SG_ 531 TracCtlPtActv_B_Actl 1;
BA_ "U_P702_MY2021_Rx" SG_ 531 TracCtlPtActv_B_Actl 1;
BA_ "U_T6_MCA_MY2020_Rx" SG_ 531 TracCtlPtActv_B_Actl 1;
BA_ "U_CX727_MY2021_Tx" SG_ 531 TracCtlPtActv_B_Actl 1;
BA_ "U_P702_MY2021_Tx" SG_ 531 TracCtlPtActv_B_Actl 1;
BA_ " _InfoCAN" SG_ 531 LscmbbMntr_B_Err 1;
BA_ "U_P702_MY2021_Tx" SG_ 531 LscmbbMntr_B_Err 1;
BA_ " _InfoCAN" SG_ 531 LscmbbBrkDis_B_Actl 1;
BA_ "U_P702_MY2021_Tx" SG_ 531 LscmbbBrkDis_B_Actl 1;
BA_ " _InfoCAN" SG_ 531 LscmbbDeny_B_ActlBrk 1;
BA_ "U_P702_MY2021_Tx" SG_ 531 LscmbbDeny_B_ActlBrk 1;
BA_ "WakeupSignal" SG_ 531 PrkBrkYwLamp_D_Rq 1;
BA_ " _InfoCAN" SG_ 531 PrkBrkYwLamp_D_Rq 1;
BA_ "U_CX727_MY2021_Tx" SG_ 531 PrkBrkYwLamp_D_Rq 1;
BA_ "U_P702_MY2021_Tx" SG_ 531 PrkBrkYwLamp_D_Rq 1;
BA_ "WakeupSignal" SG_ 531 PrkBrkRedLamp_D_Rq 1;
BA_ " _InfoCAN" SG_ 531 PrkBrkRedLamp_D_Rq 1;
BA_ "U_CX727_MY2021_Tx" SG_ 531 PrkBrkRedLamp_D_Rq 1;
BA_ "U_P702_MY2021_Tx" SG_ 531 PrkBrkRedLamp_D_Rq 1;
BA_ " _InfoCAN" SG_ 531 LscmbbBrkDecel_B_Actl 1;
BA_ "U_P702_MY2021_Tx" SG_ 531 LscmbbBrkDecel_B_Actl 1;
BA_ " _InfoCAN" SG_ 531 AbsActv_B_Actl 1;
BA_ "U_CX727_MY2021_Rx" SG_ 531 AbsActv_B_Actl 1;
BA_ "U_P702_MY2021_Rx" SG_ 531 AbsActv_B_Actl 1;
BA_ "U_T6_MCA_MY2020_Rx" SG_ 531 AbsActv_B_Actl 1;
BA_ "U_CX727_MY2021_Tx" SG_ 531 AbsActv_B_Actl 1;
BA_ "U_P702_MY2021_Tx" SG_ 531 AbsActv_B_Actl 1;
BA_ " _InfoCAN" SG_ 531 StabCtlBrkActv_B_Actl 1;
BA_ "U_P702_MY2021_Rx" SG_ 531 StabCtlBrkActv_B_Actl 1;
BA_ "U_T6_MCA_MY2020_Rx" SG_ 531 StabCtlBrkActv_B_Actl 1;
BA_ "U_CX727_MY2021_Rx" SG_ 531 StabCtlBrkActv_B_Actl 1;
BA_ "U_CX727_MY2021_Tx" SG_ 531 StabCtlBrkActv_B_Actl 1;
BA_ "U_P702_MY2021_Tx" SG_ 531 StabCtlBrkActv_B_Actl 1;
BA_ "ECGUsedRxSignal" SG_ 531 StabCtlBrkActv_B_Actl 1;
BA_ " _InfoCAN" SG_ 531 CmbbBrkPrchg_B_Actl 1;
BA_ "U_CX727_MY2021_Tx" SG_ 531 CmbbBrkPrchg_B_Actl 1;
BA_ "U_P702_MY2021_Tx" SG_ 531 CmbbBrkPrchg_B_Actl 1;
BA_ " _InfoCAN" SG_ 531 CmbbBrkDecel_B_Actl 1;
BA_ "U_CX727_MY2021_Tx" SG_ 531 CmbbBrkDecel_B_Actl 1;
BA_ "U_P702_MY2021_Tx" SG_ 531 CmbbBrkDecel_B_Actl 1;
BA_ " _InfoCAN" SG_ 531 CmbbBaSensInc_B_Actl 1;
BA_ "U_CX727_MY2021_Tx" SG_ 531 CmbbBaSensInc_B_Actl 1;
BA_ "U_P702_MY2021_Tx" SG_ 531 CmbbBaSensInc_B_Actl 1;
BA_ " _InfoCAN" SG_ 531 AccBrkWarm_B_Actl 1;
BA_ "U_CX727_MY2021_Tx" SG_ 531 AccBrkWarm_B_Actl 1;
BA_ "U_P702_MY2021_Tx" SG_ 531 AccBrkWarm_B_Actl 1;
BA_ " _InfoCAN" SG_ 531 AccBrkTotTqMn_B_Actl 1;
BA_ "U_CX727_MY2021_Tx" SG_ 531 AccBrkTotTqMn_B_Actl 1;
BA_ "U_P702_MY2021_Tx" SG_ 531 AccBrkTotTqMn_B_Actl 1;
BA_ " _InfoCAN" SG_ 531 AccBrkPrchgActv_B_Actl 1;
BA_ "U_CX727_MY2021_Tx" SG_ 531 AccBrkPrchgActv_B_Actl 1;
BA_ "U_P702_MY2021_Tx" SG_ 531 AccBrkPrchgActv_B_Actl 1;
BA_ " _InfoCAN" SG_ 531 AccBrkDis_B_Actl 1;
BA_ "U_CX727_MY2021_Tx" SG_ 531 AccBrkDis_B_Actl 1;
BA_ "U_P702_MY2021_Tx" SG_ 531 AccBrkDis_B_Actl 1;
BA_ " _InfoCAN" SG_ 531 AccBrkDeny_B_Actl 1;
BA_ "U_P702_MY2021_Rx" SG_ 531 AccBrkDeny_B_Actl 1;
BA_ "U_T6_MCA_MY2020_Rx" SG_ 531 AccBrkDeny_B_Actl 1;
BA_ "U_CX727_MY2021_Tx" SG_ 531 AccBrkDeny_B_Actl 1;
BA_ "U_P702_MY2021_Tx" SG_ 531 AccBrkDeny_B_Actl 1;
BA_ " _InfoCAN" SG_ 531 AccBrkActv_B_Actl 1;
BA_ "U_P702_MY2021_Rx" SG_ 531 AccBrkActv_B_Actl 1;
BA_ "U_T6_MCA_MY2020_Rx" SG_ 531 AccBrkActv_B_Actl 1;
BA_ "U_CX727_MY2021_Tx" SG_ 531 AccBrkActv_B_Actl 1;
BA_ "U_P702_MY2021_Tx" SG_ 531 AccBrkActv_B_Actl 1;
BA_ " _InfoCAN" SG_ 531 PrplDrgCtlActv_B_Actl 1;
BA_ "U_P702_MY2021_Rx" SG_ 531 PrplDrgCtlActv_B_Actl 1;
BA_ "U_T6_MCA_MY2020_Rx" SG_ 531 PrplDrgCtlActv_B_Actl 1;
BA_ "U_CX727_MY2021_Tx" SG_ 531 PrplDrgCtlActv_B_Actl 1;
BA_ "U_P702_MY2021_Tx" SG_ 531 PrplDrgCtlActv_B_Actl 1;
BA_ " _InfoCAN" SG_ 531 PrplWhlTot_Tq_RqMx 1;
BA_ "U_P702_MY2021_Rx" SG_ 531 PrplWhlTot_Tq_RqMx 1;
BA_ "U_T6_MCA_MY2020_Rx" SG_ 531 PrplWhlTot_Tq_RqMx 1;
BA_ "U_CX727_MY2021_Tx" SG_ 531 PrplWhlTot_Tq_RqMx 1;
BA_ "U_P702_MY2021_Tx" SG_ 531 PrplWhlTot_Tq_RqMx 1;
BA_ " _InfoCAN" SG_ 531 LscmbbBaSensInc_B_Actl 1;
BA_ "U_P702_MY2021_Tx" SG_ 531 LscmbbBaSensInc_B_Actl 1;
BA_ " _InfoCAN" SG_ 531 CmbbBrkDis_B_Actl 1;
BA_ "U_CX727_MY2021_Rx" SG_ 531 CmbbBrkDis_B_Actl 1;
BA_ "U_P702_MY2021_Rx" SG_ 531 CmbbBrkDis_B_Actl 1;
BA_ "U_CX727_MY2021_Tx" SG_ 531 CmbbBrkDis_B_Actl 1;
BA_ "U_P702_MY2021_Tx" SG_ 531 CmbbBrkDis_B_Actl 1;
BA_ " _InfoCAN" SG_ 531 CmbbDeny_B_ActlBrk 1;
BA_ "U_P702_MY2021_Rx" SG_ 531 CmbbDeny_B_ActlBrk 1;
BA_ "U_T6_MCA_MY2020_Rx" SG_ 531 CmbbDeny_B_ActlBrk 1;
BA_ "U_CX727_MY2021_Rx" SG_ 531 CmbbDeny_B_ActlBrk 1;
BA_ "U_CX727_MY2021_Tx" SG_ 531 CmbbDeny_B_ActlBrk 1;
BA_ "U_P702_MY2021_Tx" SG_ 531 CmbbDeny_B_ActlBrk 1;
BA_ " _InfoCAN" SG_ 531 CcDis_B_Cmd 1;
BA_ "U_P702_MY2021_Rx" SG_ 531 CcDis_B_Cmd 1;
BA_ "U_T6_MCA_MY2020_Rx" SG_ 531 CcDis_B_Cmd 1;
BA_ "U_CX727_MY2021_Tx" SG_ 531 CcDis_B_Cmd 1;
BA_ "U_P702_MY2021_Tx" SG_ 531 CcDis_B_Cmd 1;
BA_ " _InfoCAN" SG_ 531 VehLongOvrGnd_A_Est 1;
BA_ "GenSigStartValueInteger" SG_ 531 VehLongOvrGnd_A_Est 511;
BA_ "U_P702_MY2021_Rx" SG_ 531 VehLongOvrGnd_A_Est 1;
BA_ "U_CX727_MY2021_Tx" SG_ 531 VehLongOvrGnd_A_Est 1;
BA_ "U_P702_MY2021_Tx" SG_ 531 VehLongOvrGnd_A_Est 1;
BA_ " _InfoCAN" SG_ 531 LscmbBrkPrchg_B_Actl 1;
BA_ "U_P702_MY2021_Tx" SG_ 531 LscmbBrkPrchg_B_Actl 1;
BA_ " _InfoCAN" SG_ 531 AccStopActv_B_ActlBrk 1;
BA_ "U_P702_MY2021_Rx" SG_ 531 AccStopActv_B_ActlBrk 1;
BA_ "U_T6_MCA_MY2020_Rx" SG_ 531 AccStopActv_B_ActlBrk 1;
BA_ "U_CX727_MY2021_Tx" SG_ 531 AccStopActv_B_ActlBrk 1;
BA_ "U_P702_MY2021_Tx" SG_ 531 AccStopActv_B_ActlBrk 1;
BA_ " _InfoCAN" SG_ 531 AccDis_B_ActlEpb 1;
BA_ "U_CX727_MY2021_Tx" SG_ 531 AccDis_B_ActlEpb 1;
BA_ "U_P702_MY2021_Tx" SG_ 531 AccDis_B_ActlEpb 1;
BA_ "WakeupSignal" SG_ 531 PrkBrkMsgTxt_D_Rq 1;
BA_ " _InfoCAN" SG_ 531 PrkBrkMsgTxt_D_Rq 1;
BA_ "U_CX727_MY2021_Tx" SG_ 531 PrkBrkMsgTxt_D_Rq 1;
BA_ "U_P702_MY2021_Tx" SG_ 531 PrkBrkMsgTxt_D_Rq 1;
BA_ " _InfoCAN" SG_ 531 PrkBrkStatus 1;
BA_ "GenSigStartValueInteger" SG_ 531 PrkBrkStatus 7;
BA_ "GenSigStartValue" SG_ 531 PrkBrkStatus 7;
BA_ "U_P702_MY2021_Rx" SG_ 531 PrkBrkStatus 1;
BA_ "U_T6_MCA_MY2020_Rx" SG_ 531 PrkBrkStatus 1;
BA_ "U_CX727_MY2021_Tx" SG_ 531 PrkBrkStatus 1;
BA_ "U_P702_MY2021_Tx" SG_ 531 PrkBrkStatus 1;
BA_ "ECGUsedRxSignal" SG_ 531 PrkBrkStatus 1;
BA_ "FrameRouting" BO_ 125 "";
BA_ "GenMsgSendType" BO_ 125 0;
BA_ "GenMsgCycleTime" BO_ 125 20;
BA_ "GenMsgDelayTime" BO_ 125 10;
BA_ "VFrameFormat" BO_ 125 14;
BA_ "GenSigStartValueInteger" SG_ 125 VehRolComp_W_Actl 4094;
BA_ "GenSigStartValue" SG_ 125 VehRolComp_W_Actl 4094;
BA_ "U_CX727_MY2021_Tx" SG_ 125 VehRolComp_W_Actl 1;
BA_ "U_P702_MY2021_Tx" SG_ 125 VehRolComp_W_Actl 1;
BA_ "GenSigStartValueInteger" SG_ 125 VehVertComp_A_Actl 1022;
BA_ "GenSigStartValue" SG_ 125 VehVertComp_A_Actl 1022;
BA_ "U_P702_MY2021_Rx" SG_ 125 VehVertComp_A_Actl 1;
BA_ "U_CX727_MY2021_Tx" SG_ 125 VehVertComp_A_Actl 1;
BA_ "U_P702_MY2021_Tx" SG_ 125 VehVertComp_A_Actl 1;
BA_ "MetaData" SG_ 125 BrkTotTqRqArb_No_Cs 1;
BA_ "U_P702_MY2021_Rx" SG_ 125 BrkTotTqRqArb_No_Cs 1;
BA_ "U_T6_MCA_MY2020_Rx" SG_ 125 BrkTotTqRqArb_No_Cs 1;
BA_ "U_CX727_MY2021_Tx" SG_ 125 BrkTotTqRqArb_No_Cs 1;
BA_ "U_P702_MY2021_Tx" SG_ 125 BrkTotTqRqArb_No_Cs 1;
BA_ "MetaData" SG_ 125 BrkTotTqRqArb_No_Cnt 1;
BA_ "U_P702_MY2021_Rx" SG_ 125 BrkTotTqRqArb_No_Cnt 1;
BA_ "U_T6_MCA_MY2020_Rx" SG_ 125 BrkTotTqRqArb_No_Cnt 1;
BA_ "U_CX727_MY2021_Tx" SG_ 125 BrkTotTqRqArb_No_Cnt 1;
BA_ "U_P702_MY2021_Tx" SG_ 125 BrkTotTqRqArb_No_Cnt 1;
BA_ "U_P702_MY2021_Rx" SG_ 125 BrkTot_Tq_RqArb 1;
BA_ "U_T6_MCA_MY2020_Rx" SG_ 125 BrkTot_Tq_RqArb 1;
BA_ "U_CX727_MY2021_Tx" SG_ 125 BrkTot_Tq_RqArb 1;
BA_ "U_P702_MY2021_Tx" SG_ 125 BrkTot_Tq_RqArb 1;
BA_ "ECGUsedRxSignal" SG_ 125 BrkTot_Tq_RqArb 1;
BA_ "U_CX727_MY2021_Rx" SG_ 125 BrkTot_Tq_Actl 1;
BA_ "U_P702_MY2021_Rx" SG_ 125 BrkTot_Tq_Actl 1;
BA_ "U_T6_MCA_MY2020_Rx" SG_ 125 BrkTot_Tq_Actl 1;
BA_ "U_CX727_MY2021_Tx" SG_ 125 BrkTot_Tq_Actl 1;
BA_ "U_P702_MY2021_Tx" SG_ 125 BrkTot_Tq_Actl 1;
BA_ " _InfoCAN" SG_ 125 HsaStat_D_Actl 1;
BA_ "U_P702_MY2021_Rx" SG_ 125 HsaStat_D_Actl 1;
BA_ "U_T6_MCA_MY2020_Rx" SG_ 125 HsaStat_D_Actl 1;
BA_ "U_CX727_MY2021_Tx" SG_ 125 HsaStat_D_Actl 1;
BA_ "U_P702_MY2021_Tx" SG_ 125 HsaStat_D_Actl 1;
BA_ "FrameRouting" BO_ 119 "";
BA_ "GenMsgSendType" BO_ 119 0;
BA_ "GenMsgCycleTime" BO_ 119 20;
BA_ "GenMsgDelayTime" BO_ 119 10;
BA_ "VFrameFormat" BO_ 119 14;
BA_ "GenSigStartValueInteger" SG_ 119 VehTrvlDir_D_Stat 6;
BA_ "GenSigStartValue" SG_ 119 VehTrvlDir_D_Stat 6;
BA_ "U_P702_MY2021_Tx" SG_ 119 VehTrvlDir_D_Stat 1;
BA_ "U_CX727_MY2021_Rx" SG_ 119 VehOverGnd_V_Est 1;
BA_ "U_P702_MY2021_Rx" SG_ 119 VehOverGnd_V_Est 1;
BA_ "U_CX727_MY2021_Tx" SG_ 119 VehOverGnd_V_Est 1;
BA_ "U_P702_MY2021_Tx" SG_ 119 VehOverGnd_V_Est 1;
BA_ "GenSigStartValueInteger" SG_ 119 VehLongComp_A_Actl 1022;
BA_ "GenSigStartValue" SG_ 119 VehLongComp_A_Actl 1022;
BA_ "U_P702_MY2021_Rx" SG_ 119 VehLongComp_A_Actl 1;
BA_ "U_T6_MCA_MY2020_Rx" SG_ 119 VehLongComp_A_Actl 1;
BA_ "U_CX727_MY2021_Tx" SG_ 119 VehLongComp_A_Actl 1;
BA_ "U_P702_MY2021_Tx" SG_ 119 VehLongComp_A_Actl 1;
BA_ "ECGUsedRxSignal" SG_ 119 VehLongComp_A_Actl 1;
BA_ "GenSigStartValueInteger" SG_ 119 VehLatComp_A_Actl 1022;
BA_ "GenSigStartValue" SG_ 119 VehLatComp_A_Actl 1022;
BA_ "U_P702_MY2021_Rx" SG_ 119 VehLatComp_A_Actl 1;
BA_ "U_CX727_MY2021_Rx" SG_ 119 VehLatComp_A_Actl 1;
BA_ "U_T6_MCA_MY2020_Rx" SG_ 119 VehLatComp_A_Actl 1;
BA_ "U_CX727_MY2021_Tx" SG_ 119 VehLatComp_A_Actl 1;
BA_ "U_P702_MY2021_Tx" SG_ 119 VehLatComp_A_Actl 1;
BA_ "ECGUsedRxSignal" SG_ 119 VehLatComp_A_Actl 1;
BA_ " _InfoCAN" SG_ 119 VehYawComp_W_Actl 1;
BA_ "GenSigStartValueInteger" SG_ 119 VehYawComp_W_Actl 4094;
BA_ "GenSigStartValue" SG_ 119 VehYawComp_W_Actl 4094;
BA_ "U_CX727_MY2021_Rx" SG_ 119 VehYawComp_W_Actl 1;
BA_ "U_P702_MY2021_Rx" SG_ 119 VehYawComp_W_Actl 1;
BA_ "U_T6_MCA_MY2020_Rx" SG_ 119 VehYawComp_W_Actl 1;
BA_ "U_CX727_MY2021_Tx" SG_ 119 VehYawComp_W_Actl 1;
BA_ "U_P702_MY2021_Tx" SG_ 119 VehYawComp_W_Actl 1;
BA_ "ECGUsedRxSignal" SG_ 119 VehYawComp_W_Actl 1;
BA_ "FrameRouting" BO_ 118 "";
BA_ "GenMsgSendType" BO_ 118 5;
BA_ "GenMsgCycleTime" BO_ 118 500;
BA_ "VFrameFormat" BO_ 118 14;
BA_ "GenSigSendType" SG_ 118 BrkCtrFnd_B_Stat 3;
BA_ "U_P702_MY2021_Tx" SG_ 118 BrkCtrFnd_B_Stat 1;
BA_ "U_P702_MY2021_Rx" SG_ 118 AwdLck_Tq_RqMx 1;
BA_ "U_P702_MY2021_Tx" SG_ 118 AwdLck_Tq_RqMx 1;
BA_ "U_P702_MY2021_Rx" SG_ 118 AwdLck_Tq_RqMn 1;
BA_ "U_P702_MY2021_Tx" SG_ 118 AwdLck_Tq_RqMn 1;
BA_ "GenSigSendType" SG_ 118 DrvSte_D_Stat 3;
BA_ "U_CX727_MY2021_Rx" SG_ 118 DrvSte_D_Stat 1;
BA_ "U_P702_MY2021_Rx" SG_ 118 DrvSte_D_Stat 1;
BA_ "U_P702_MY2021_Tx" SG_ 118 DrvSte_D_Stat 1;
BA_ "GenSigStartValueInteger" SG_ 118 DrvSte_Tq_Rq 128;
BA_ "U_CX727_MY2021_Rx" SG_ 118 DrvSte_Tq_Rq 1;
BA_ "U_P702_MY2021_Rx" SG_ 118 DrvSte_Tq_Rq 1;
BA_ "U_P702_MY2021_Tx" SG_ 118 DrvSte_Tq_Rq 1;
BA_ "GenSigSendType" SG_ 118 EmgcyBrkLamp_D_Rq 3;
BA_ "U_CX727_MY2021_Tx" SG_ 118 EmgcyBrkLamp_D_Rq 1;
BA_ "U_P702_MY2021_Tx" SG_ 118 EmgcyBrkLamp_D_Rq 1;
BA_ "GenSigSendType" SG_ 118 StopLamp_B_RqBrk 3;
BA_ "U_CX727_MY2021_Tx" SG_ 118 StopLamp_B_RqBrk 1;
BA_ "U_P702_MY2021_Tx" SG_ 118 StopLamp_B_RqBrk 1;
BA_ "FrameRouting" BO_ 1034 "";
BA_ "FrameGatewayId" BO_ 1034 1034;
BA_ "FrameGatewayNetwork" BO_ 1034 "HS1_CAN";
BA_ "VFrameFormat" BO_ 1034 14;
BA_ " _InfoCAN" SG_ 1034 VehicleGGCCData 1;
BA_ "U_P702_MY2021_Rx" SG_ 1034 VehicleGGCCData 1;
BA_ "U_T6_MCA_MY2020_Rx" SG_ 1034 VehicleGGCCData 1;
BA_ "U_CX727_MY2021_Rx" SG_ 1034 VehicleGGCCData 1;
BA_ "FrameRouting" BO_ 560 "";
BA_ "GenMsgSendType" BO_ 560 0;
BA_ "GenMsgCycleTime" BO_ 560 20;
BA_ "GenMsgDelayTime" BO_ 560 10;
BA_ "VFrameFormat" BO_ 560 14;
BA_ "ContentDependant" SG_ 560 SelDrvMdeSwtch_D_Stat3 1;
BA_ "U_P702_MY2021_Rx" SG_ 560 SelDrvMdeSwtch_D_Stat3 1;
BA_ "U_P702_MY2021_Tx" SG_ 560 SelDrvMdeSwtch_D_Stat3 1;
BA_ "U_T6_MCA_MY2020_Tx" SG_ 560 SelDrvMdeSwtch_D_Stat3 1;
BA_ " _InfoCAN" SG_ 560 TrnSrvcRqd_B_Rq 1;
BA_ "ContentDependant" SG_ 560 TrnSrvcRqd_B_Rq 1;
BA_ "U_P702_MY2021_Tx" SG_ 560 TrnSrvcRqd_B_Rq 1;
BA_ "U_T6_MCA_MY2020_Tx" SG_ 560 TrnSrvcRqd_B_Rq 1;
BA_ "ECGUsedRxSignal" SG_ 560 TrnSrvcRqd_B_Rq 1;
BA_ "ContentDependant" SG_ 560 TrnShifActv_B_Actl 1;
BA_ "U_P702_MY2021_Rx" SG_ 560 TrnShifActv_B_Actl 1;
BA_ "U_T6_MCA_MY2020_Rx" SG_ 560 TrnShifActv_B_Actl 1;
BA_ "U_CX727_MY2021_Rx" SG_ 560 TrnShifActv_B_Actl 1;
BA_ "U_P702_MY2021_Tx" SG_ 560 TrnShifActv_B_Actl 1;
BA_ "U_T6_MCA_MY2020_Tx" SG_ 560 TrnShifActv_B_Actl 1;
BA_ " _InfoCAN" SG_ 560 GearLvrPos_D_Actl 1;
BA_ "GenSigStartValueInteger" SG_ 560 GearLvrPos_D_Actl 14;
BA_ "GenSigStartValue" SG_ 560 GearLvrPos_D_Actl 14;
BA_ "U_P702_MY2021_Rx" SG_ 560 GearLvrPos_D_Actl 1;
BA_ "U_T6_MCA_MY2020_Rx" SG_ 560 GearLvrPos_D_Actl 1;
BA_ "U_CX727_MY2021_Rx" SG_ 560 GearLvrPos_D_Actl 1;
BA_ "U_P702_MY2021_Tx" SG_ 560 GearLvrPos_D_Actl 1;
BA_ "U_T6_MCA_MY2020_Tx" SG_ 560 GearLvrPos_D_Actl 1;
BA_ "GenSigStartValueInteger" SG_ 560 GboxOil_Te_Actl 254;
BA_ "ContentDependant" SG_ 560 GboxOil_Te_Actl 1;
BA_ "GenSigStartValue" SG_ 560 GboxOil_Te_Actl 254;
BA_ "U_P702_MY2021_Rx" SG_ 560 GboxOil_Te_Actl 1;
BA_ "U_T6_MCA_MY2020_Rx" SG_ 560 GboxOil_Te_Actl 1;
BA_ "U_P702_MY2021_Tx" SG_ 560 GboxOil_Te_Actl 1;
BA_ "U_T6_MCA_MY2020_Tx" SG_ 560 GboxOil_Te_Actl 1;
BA_ "FrameRouting" BO_ 369 "";
BA_ "GenMsgSendType" BO_ 369 0;
BA_ "GenMsgCycleTime" BO_ 369 30;
BA_ "GenMsgDelayTime" BO_ 369 10;
BA_ "VFrameFormat" BO_ 369 14;
BA_ "GenSigStartValueInteger" SG_ 369 TrnIpcDsplyRng2_D_Actl 15;
BA_ "GenSigStartValue" SG_ 369 TrnIpcDsplyRng2_D_Actl 15;
BA_ "U_P702_MY2021_Tx" SG_ 369 TrnIpcDsplyRng2_D_Actl 1;
BA_ "U_T6_MCA_MY2020_Tx" SG_ 369 TrnIpcDsplyRng2_D_Actl 1;
BA_ "U_P702_MY2021_Tx" SG_ 369 TrnIpcDsplyRng_D_Stat 1;
BA_ "U_T6_MCA_MY2020_Tx" SG_ 369 TrnIpcDsplyRng_D_Stat 1;
BA_ " _InfoCAN" SG_ 369 TrnIpcDsplyGear_D_Actl 1;
BA_ "GenSigStartValueInteger" SG_ 369 TrnIpcDsplyGear_D_Actl 15;
BA_ "GenSigStartValue" SG_ 369 TrnIpcDsplyGear_D_Actl 15;
BA_ "U_P702_MY2021_Tx" SG_ 369 TrnIpcDsplyGear_D_Actl 1;
BA_ "U_T6_MCA_MY2020_Tx" SG_ 369 TrnIpcDsplyGear_D_Actl 1;
BA_ "WakeupSignal" SG_ 369 TrnIpcDsplyMde_D_Stat 1;
BA_ " _InfoCAN" SG_ 369 TrnIpcDsplyMde_D_Stat 1;
BA_ "U_P702_MY2021_Tx" SG_ 369 TrnIpcDsplyMde_D_Stat 1;
BA_ "U_T6_MCA_MY2020_Tx" SG_ 369 TrnIpcDsplyMde_D_Stat 1;
BA_ "WakeupSignal" SG_ 369 TrnIpcDsplyMde_D_Actl 1;
BA_ " _InfoCAN" SG_ 369 TrnIpcDsplyMde_D_Actl 1;
BA_ "U_P702_MY2021_Tx" SG_ 369 TrnIpcDsplyMde_D_Actl 1;
BA_ "U_T6_MCA_MY2020_Tx" SG_ 369 TrnIpcDsplyMde_D_Actl 1;
BA_ " _InfoCAN" SG_ 369 TrnIpcDsplyGear_D_Stat 1;
BA_ "U_P702_MY2021_Tx" SG_ 369 TrnIpcDsplyGear_D_Stat 1;
BA_ "U_T6_MCA_MY2020_Tx" SG_ 369 TrnIpcDsplyGear_D_Stat 1;
BA_ "FrameRouting" BO_ 1429 "";
BA_ "GenMsgILSupport" BO_ 1429 0;
BA_ "NmAsrMessage" BO_ 1429 1;
BA_ "GenMsgSendType" BO_ 1429 0;
BA_ "GenMsgCycleTime" BO_ 1429 1000;
BA_ "NetworkInitialization" BO_ 1429 0;
BA_ "VFrameFormat" BO_ 1429 14;
BA_ "GenSigStartValueInteger" SG_ 1429 PCM_GWOnBoardTester 255;
BA_ "ContentDependant" SG_ 1429 PCM_GWOnBoardTester 1;
BA_ "GenSigStartValue" SG_ 1429 PCM_GWOnBoardTester 255;
BA_ "U_P702_MY2021_Rx" SG_ 1429 PCM_GWOnBoardTester 1;
BA_ "U_T6_MCA_MY2020_Rx" SG_ 1429 PCM_GWOnBoardTester 1;
BA_ "U_P702_MY2021_Tx" SG_ 1429 PCM_GWOnBoardTester 1;
BA_ "U_T6_MCA_MY2020_Tx" SG_ 1429 PCM_GWOnBoardTester 1;
BA_ "GenSigStartValueInteger" SG_ 1429 PCM_GWNMProxy 255;
BA_ "ContentDependant" SG_ 1429 PCM_GWNMProxy 1;
BA_ "GenSigStartValue" SG_ 1429 PCM_GWNMProxy 255;
BA_ "U_P702_MY2021_Rx" SG_ 1429 PCM_GWNMProxy 1;
BA_ "U_T6_MCA_MY2020_Rx" SG_ 1429 PCM_GWNMProxy 1;
BA_ "U_P702_MY2021_Tx" SG_ 1429 PCM_GWNMProxy 1;
BA_ "U_T6_MCA_MY2020_Tx" SG_ 1429 PCM_GWNMProxy 1;
BA_ "GenSigStartValueInteger" SG_ 1429 PCM_AutoSarNMReserved4 255;
BA_ "ContentDependant" SG_ 1429 PCM_AutoSarNMReserved4 1;
BA_ "GenSigStartValue" SG_ 1429 PCM_AutoSarNMReserved4 255;
BA_ "U_P702_MY2021_Rx" SG_ 1429 PCM_AutoSarNMReserved4 1;
BA_ "U_T6_MCA_MY2020_Rx" SG_ 1429 PCM_AutoSarNMReserved4 1;
BA_ "U_P702_MY2021_Tx" SG_ 1429 PCM_AutoSarNMReserved4 1;
BA_ "U_T6_MCA_MY2020_Tx" SG_ 1429 PCM_AutoSarNMReserved4 1;
BA_ "GenSigStartValueInteger" SG_ 1429 PCM_AutoSarNMReserved3 255;
BA_ "ContentDependant" SG_ 1429 PCM_AutoSarNMReserved3 1;
BA_ "GenSigStartValue" SG_ 1429 PCM_AutoSarNMReserved3 255;
BA_ "U_P702_MY2021_Rx" SG_ 1429 PCM_AutoSarNMReserved3 1;
BA_ "U_T6_MCA_MY2020_Rx" SG_ 1429 PCM_AutoSarNMReserved3 1;
BA_ "U_P702_MY2021_Tx" SG_ 1429 PCM_AutoSarNMReserved3 1;
BA_ "U_T6_MCA_MY2020_Tx" SG_ 1429 PCM_AutoSarNMReserved3 1;
BA_ "GenSigStartValueInteger" SG_ 1429 PCM_AutoSarNMReserved2 255;
BA_ "ContentDependant" SG_ 1429 PCM_AutoSarNMReserved2 1;
BA_ "GenSigStartValue" SG_ 1429 PCM_AutoSarNMReserved2 255;
BA_ "U_P702_MY2021_Rx" SG_ 1429 PCM_AutoSarNMReserved2 1;
BA_ "U_T6_MCA_MY2020_Rx" SG_ 1429 PCM_AutoSarNMReserved2 1;
BA_ "U_P702_MY2021_Tx" SG_ 1429 PCM_AutoSarNMReserved2 1;
BA_ "U_T6_MCA_MY2020_Tx" SG_ 1429 PCM_AutoSarNMReserved2 1;
BA_ "GenSigStartValueInteger" SG_ 1429 PCM_AutoSarNMReserved1 255;
BA_ "ContentDependant" SG_ 1429 PCM_AutoSarNMReserved1 1;
BA_ "GenSigStartValue" SG_ 1429 PCM_AutoSarNMReserved1 255;
BA_ "U_P702_MY2021_Rx" SG_ 1429 PCM_AutoSarNMReserved1 1;
BA_ "U_T6_MCA_MY2020_Rx" SG_ 1429 PCM_AutoSarNMReserved1 1;
BA_ "U_P702_MY2021_Tx" SG_ 1429 PCM_AutoSarNMReserved1 1;
BA_ "U_T6_MCA_MY2020_Tx" SG_ 1429 PCM_AutoSarNMReserved1 1;
BA_ "GenSigStartValueInteger" SG_ 1429 PCM_AutoSarNMNodeId 149;
BA_ "ContentDependant" SG_ 1429 PCM_AutoSarNMNodeId 1;
BA_ "GenSigStartValue" SG_ 1429 PCM_AutoSarNMNodeId 149;
BA_ "U_P702_MY2021_Rx" SG_ 1429 PCM_AutoSarNMNodeId 1;
BA_ "U_T6_MCA_MY2020_Rx" SG_ 1429 PCM_AutoSarNMNodeId 1;
BA_ "U_P702_MY2021_Tx" SG_ 1429 PCM_AutoSarNMNodeId 1;
BA_ "U_T6_MCA_MY2020_Tx" SG_ 1429 PCM_AutoSarNMNodeId 1;
BA_ "ContentDependant" SG_ 1429 PCM_AutoSarNMControl 1;
BA_ "U_P702_MY2021_Rx" SG_ 1429 PCM_AutoSarNMControl 1;
BA_ "U_T6_MCA_MY2020_Rx" SG_ 1429 PCM_AutoSarNMControl 1;
BA_ "U_P702_MY2021_Tx" SG_ 1429 PCM_AutoSarNMControl 1;
BA_ "U_T6_MCA_MY2020_Tx" SG_ 1429 PCM_AutoSarNMControl 1;
BA_ "FrameRouting" BO_ 1086 "";
BA_ "GenMsgSendType" BO_ 1086 0;
BA_ "GenMsgCycleTime" BO_ 1086 100;
BA_ "VFrameFormat" BO_ 1086 14;
BA_ "GenSigStartValueInteger" SG_ 1086 EngMnfld_P_Actl 2068;
BA_ "U_P702_MY2021_Tx" SG_ 1086 EngMnfld_P_Actl 1;
BA_ "U_T6_MCA_MY2020_Tx" SG_ 1086 EngMnfld_P_Actl 1;
BA_ "U_P702_MY2021_Tx" SG_ 1086 FuelPumpPwr_B_Rq 1;
BA_ "U_T6_MCA_MY2020_Tx" SG_ 1086 FuelPumpPwr_B_Rq 1;
BA_ "U_P702_MY2021_Tx" SG_ 1086 BattULoChrg_U_Cmd 1;
BA_ "U_T6_MCA_MY2020_Tx" SG_ 1086 BattULoChrg_U_Cmd 1;
BA_ "ContentDependant" SG_ 1086 ElLoadCtl_D_Rq 1;
BA_ "U_P702_MY2021_Tx" SG_ 1086 ElLoadCtl_D_Rq 1;
BA_ "U_T6_MCA_MY2020_Tx" SG_ 1086 ElLoadCtl_D_Rq 1;
BA_ "FrameRouting" BO_ 1071 "";
BA_ "GenMsgSendType" BO_ 1071 0;
BA_ "GenMsgCycleTime" BO_ 1071 100;
BA_ "VFrameFormat" BO_ 1071 14;
BA_ "U_P702_MY2021_Tx" SG_ 1071 EngAout_N_Dsply 1;
BA_ "U_T6_MCA_MY2020_Tx" SG_ 1071 EngAout_N_Dsply 1;
BA_ " _InfoCAN" SG_ 1071 CluPdl_PcRate_Actl 1;
BA_ "ContentDependant" SG_ 1071 CluPdl_PcRate_Actl 1;
BA_ "U_P702_MY2021_Tx" SG_ 1071 CluPdl_PcRate_Actl 1;
BA_ "U_T6_MCA_MY2020_Tx" SG_ 1071 CluPdl_PcRate_Actl 1;
BA_ " _InfoCAN" SG_ 1071 CluPdlPosPcMeas_D_Qf 1;
BA_ "GenSigStartValueInteger" SG_ 1071 CluPdlPosPcMeas_D_Qf 1;
BA_ "ContentDependant" SG_ 1071 CluPdlPosPcMeas_D_Qf 1;
BA_ "MetaData" SG_ 1071 CluPdlPosPcMeas_D_Qf 1;
BA_ "GenSigStartValue" SG_ 1071 CluPdlPosPcMeas_D_Qf 1;
BA_ "U_P702_MY2021_Rx" SG_ 1071 CluPdlPosPcMeas_D_Qf 1;
BA_ "U_P702_MY2021_Tx" SG_ 1071 CluPdlPosPcMeas_D_Qf 1;
BA_ "U_T6_MCA_MY2020_Tx" SG_ 1071 CluPdlPosPcMeas_D_Qf 1;
BA_ " _InfoCAN" SG_ 1071 CluPdlPos_Pc_Meas 1;
BA_ "ContentDependant" SG_ 1071 CluPdlPos_Pc_Meas 1;
BA_ "U_P702_MY2021_Rx" SG_ 1071 CluPdlPos_Pc_Meas 1;
BA_ "U_P702_MY2021_Tx" SG_ 1071 CluPdlPos_Pc_Meas 1;
BA_ "U_T6_MCA_MY2020_Tx" SG_ 1071 CluPdlPos_Pc_Meas 1;
BA_ " _InfoCAN" SG_ 1071 EngAoutIdl_N_Ntrl 1;
BA_ "ContentDependant" SG_ 1071 EngAoutIdl_N_Ntrl 1;
BA_ "U_CX727_MY2021_Rx" SG_ 1071 EngAoutIdl_N_Ntrl 1;
BA_ "U_P702_MY2021_Rx" SG_ 1071 EngAoutIdl_N_Ntrl 1;
BA_ "U_P702_MY2021_Tx" SG_ 1071 EngAoutIdl_N_Ntrl 1;
BA_ "U_T6_MCA_MY2020_Tx" SG_ 1071 EngAoutIdl_N_Ntrl 1;
BA_ "FrameRouting" BO_ 1069 "";
BA_ "GenMsgSendType" BO_ 1069 0;
BA_ "GenMsgCycleTime" BO_ 1069 100;
BA_ "VFrameFormat" BO_ 1069 14;
BA_ "U_T6_MCA_MY2020_Tx" SG_ 1069 SlMde_D_Stat 1;
BA_ "U_P702_MY2021_Tx" SG_ 1069 SlMde_D_Stat 1;
BA_ "U_T6_MCA_MY2020_Tx" SG_ 1069 SlMde_D_RqDsply 1;
BA_ "U_P702_MY2021_Tx" SG_ 1069 SlMde_D_RqDsply 1;
BA_ "U_T6_MCA_MY2020_Tx" SG_ 1069 IsaOffst_D_Stat 1;
BA_ "U_P702_MY2021_Tx" SG_ 1069 IsaOffst_D_Stat 1;
BA_ " _InfoCAN" SG_ 1069 GrllShtrPos_D_Cmd 1;
BA_ "U_P702_MY2021_Tx" SG_ 1069 GrllShtrPos_D_Cmd 1;
BA_ "U_T6_MCA_MY2020_Tx" SG_ 1069 GrllShtrPos_D_Cmd 1;
BA_ " _InfoCAN" SG_ 1069 GrllShtrPos_B_Falt 1;
BA_ "U_P702_MY2021_Tx" SG_ 1069 GrllShtrPos_B_Falt 1;
BA_ "U_T6_MCA_MY2020_Tx" SG_ 1069 GrllShtrPos_B_Falt 1;
BA_ " _InfoCAN" SG_ 1069 ObdWarmUp_B_Complt 1;
BA_ "ContentDependant" SG_ 1069 ObdWarmUp_B_Complt 1;
BA_ "U_P702_MY2021_Tx" SG_ 1069 ObdWarmUp_B_Complt 1;
BA_ " _InfoCAN" SG_ 1069 EngMsgTxt_D_Rq 1;
BA_ "ContentDependant" SG_ 1069 EngMsgTxt_D_Rq 1;
BA_ "U_P702_MY2021_Tx" SG_ 1069 EngMsgTxt_D_Rq 1;
BA_ "U_T6_MCA_MY2020_Tx" SG_ 1069 EngMsgTxt_D_Rq 1;
BA_ " _InfoCAN" SG_ 1069 EngClnt_Te_ActlDiag 1;
BA_ "ContentDependant" SG_ 1069 EngClnt_Te_ActlDiag 1;
BA_ "U_P702_MY2021_Rx" SG_ 1069 EngClnt_Te_ActlDiag 1;
BA_ "U_T6_MCA_MY2020_Rx" SG_ 1069 EngClnt_Te_ActlDiag 1;
BA_ "U_P702_MY2021_Tx" SG_ 1069 EngClnt_Te_ActlDiag 1;
BA_ "U_T6_MCA_MY2020_Tx" SG_ 1069 EngClnt_Te_ActlDiag 1;
BA_ " _InfoCAN" SG_ 1069 EngLoad_Pc_CalcDiag 1;
BA_ "ContentDependant" SG_ 1069 EngLoad_Pc_CalcDiag 1;
BA_ "U_P702_MY2021_Rx" SG_ 1069 EngLoad_Pc_CalcDiag 1;
BA_ "U_T6_MCA_MY2020_Rx" SG_ 1069 EngLoad_Pc_CalcDiag 1;
BA_ "U_P702_MY2021_Tx" SG_ 1069 EngLoad_Pc_CalcDiag 1;
BA_ "U_T6_MCA_MY2020_Tx" SG_ 1069 EngLoad_Pc_CalcDiag 1;
BA_ " _InfoCAN" SG_ 1069 EngAirIn_Te_Actl 1;
BA_ "U_P702_MY2021_Rx" SG_ 1069 EngAirIn_Te_Actl 1;
BA_ "U_T6_MCA_MY2020_Rx" SG_ 1069 EngAirIn_Te_Actl 1;
BA_ "U_P702_MY2021_Tx" SG_ 1069 EngAirIn_Te_Actl 1;
BA_ "U_T6_MCA_MY2020_Tx" SG_ 1069 EngAirIn_Te_Actl 1;
BA_ " _InfoCAN" SG_ 1069 ApedPos_Pc_ActlDiag 1;
BA_ "ContentDependant" SG_ 1069 ApedPos_Pc_ActlDiag 1;
BA_ "U_P702_MY2021_Rx" SG_ 1069 ApedPos_Pc_ActlDiag 1;
BA_ "U_T6_MCA_MY2020_Rx" SG_ 1069 ApedPos_Pc_ActlDiag 1;
BA_ "U_P702_MY2021_Tx" SG_ 1069 ApedPos_Pc_ActlDiag 1;
BA_ "U_T6_MCA_MY2020_Tx" SG_ 1069 ApedPos_Pc_ActlDiag 1;
BA_ "FrameRouting" BO_ 1060 "";
BA_ "GenMsgSendType" BO_ 1060 0;
BA_ "GenMsgCycleTime" BO_ 1060 100;
BA_ "VFrameFormat" BO_ 1060 14;
BA_ "U_P702_MY2021_Tx" SG_ 1060 RearDiffOilTeWarn_B_Rq 1;
BA_ "U_T6_MCA_MY2020_Tx" SG_ 1060 RearDiffOilTeWarn_B_Rq 1;
BA_ "GenSigStartValueInteger" SG_ 1060 RearDiffOil_Te_Actl 77;
BA_ "GenSigStartValue" SG_ 1060 RearDiffOil_Te_Actl 77;
BA_ "U_P702_MY2021_Tx" SG_ 1060 RearDiffOil_Te_Actl 1;
BA_ "U_T6_MCA_MY2020_Tx" SG_ 1060 RearDiffOil_Te_Actl 1;
BA_ "U_P702_MY2021_Tx" SG_ 1060 BpedDrvMsgTxt_B_Dsply 1;
BA_ "U_T6_MCA_MY2020_Tx" SG_ 1060 BpedDrvMsgTxt_B_Dsply 1;
BA_ "GenSigStartValueInteger" SG_ 1060 FuelLvl_Pc_DsplyEng 48;
BA_ "U_P702_MY2021_Tx" SG_ 1060 FuelLvl_Pc_DsplyEng 1;
BA_ "U_T6_MCA_MY2020_Tx" SG_ 1060 FuelLvl_Pc_DsplyEng 1;
BA_ "U_P702_MY2021_Tx" SG_ 1060 FuelLvlWarn_D_ActlEng 1;
BA_ "U_T6_MCA_MY2020_Tx" SG_ 1060 FuelLvlWarn_D_ActlEng 1;
BA_ "U_P702_MY2021_Tx" SG_ 1060 FuelRange_L_DsplyEng 1;
BA_ "U_T6_MCA_MY2020_Tx" SG_ 1060 FuelRange_L_DsplyEng 1;
BA_ "U_P702_MY2021_Rx" SG_ 1060 SelDrvMdePt_D_Stat 1;
BA_ "U_P702_MY2021_Tx" SG_ 1060 SelDrvMdePt_D_Stat 1;
BA_ "U_T6_MCA_MY2020_Tx" SG_ 1060 SelDrvMdePt_D_Stat 1;
BA_ "FrameRouting" BO_ 1057 "";
BA_ "GenMsgSendType" BO_ 1057 0;
BA_ "GenMsgCycleTime" BO_ 1057 100;
BA_ "VFrameFormat" BO_ 1057 14;
BA_ " _InfoCAN" SG_ 1057 FohEng_D_Rq 1;
BA_ "GenSigStartValueInteger" SG_ 1057 FohEng_D_Rq 2;
BA_ "ContentDependant" SG_ 1057 FohEng_D_Rq 1;
BA_ "GenSigStartValue" SG_ 1057 FohEng_D_Rq 2;
BA_ "U_P702_MY2021_Tx" SG_ 1057 FohEng_D_Rq 1;
BA_ "U_T6_MCA_MY2020_Tx" SG_ 1057 FohEng_D_Rq 1;
BA_ "U_P702_MY2021_Tx" SG_ 1057 EngIdlShutDwnTxt_D_Rq 1;
BA_ "U_T6_MCA_MY2020_Tx" SG_ 1057 EngIdlShutDwnTxt_D_Rq 1;
BA_ " _InfoCAN" SG_ 1057 EngIdlShutDown_D_Stat 1;
BA_ "ContentDependant" SG_ 1057 EngIdlShutDown_D_Stat 1;
BA_ "U_P702_MY2021_Tx" SG_ 1057 EngIdlShutDown_D_Stat 1;
BA_ "U_T6_MCA_MY2020_Tx" SG_ 1057 EngIdlShutDown_D_Stat 1;
BA_ "ECGUsedRxSignal" SG_ 1057 EngIdlShutDown_D_Stat 1;
BA_ " _InfoCAN" SG_ 1057 FUEL_ALCOHOL_PERCNT 1;
BA_ "GenSigStartValueInteger" SG_ 1057 FUEL_ALCOHOL_PERCNT 255;
BA_ "ContentDependant" SG_ 1057 FUEL_ALCOHOL_PERCNT 1;
BA_ "GenSigStartValue" SG_ 1057 FUEL_ALCOHOL_PERCNT 255;
BA_ "U_P702_MY2021_Tx" SG_ 1057 FUEL_ALCOHOL_PERCNT 1;
BA_ "U_T6_MCA_MY2020_Tx" SG_ 1057 FUEL_ALCOHOL_PERCNT 1;
BA_ " _InfoCAN" SG_ 1057 TrnTotTq_Rt_Est 1;
BA_ "ContentDependant" SG_ 1057 TrnTotTq_Rt_Est 1;
BA_ "U_P702_MY2021_Tx" SG_ 1057 TrnTotTq_Rt_Est 1;
BA_ "U_T6_MCA_MY2020_Tx" SG_ 1057 TrnTotTq_Rt_Est 1;
BA_ " _InfoCAN" SG_ 1057 TrnTotLss_Tq_Est 1;
BA_ "ContentDependant" SG_ 1057 TrnTotLss_Tq_Est 1;
BA_ "U_P702_MY2021_Tx" SG_ 1057 TrnTotLss_Tq_Est 1;
BA_ "U_T6_MCA_MY2020_Tx" SG_ 1057 TrnTotLss_Tq_Est 1;
BA_ " _InfoCAN" SG_ 1057 ECMMILRequest 1;
BA_ "U_P702_MY2021_Tx" SG_ 1057 ECMMILRequest 1;
BA_ "U_T6_MCA_MY2020_Tx" SG_ 1057 ECMMILRequest 1;
BA_ " _InfoCAN" SG_ 1057 AirCondFluidHi_P_Actl 1;
BA_ "U_P702_MY2021_Tx" SG_ 1057 AirCondFluidHi_P_Actl 1;
BA_ "U_T6_MCA_MY2020_Tx" SG_ 1057 AirCondFluidHi_P_Actl 1;
BA_ " _InfoCAN" SG_ 1057 OilPressureWarning 1;
BA_ "U_P702_MY2021_Tx" SG_ 1057 OilPressureWarning 1;
BA_ "U_T6_MCA_MY2020_Tx" SG_ 1057 OilPressureWarning 1;
BA_ " _InfoCAN" SG_ 1057 VehVLimStat_D_Actl 1;
BA_ "ContentDependant" SG_ 1057 VehVLimStat_D_Actl 1;
BA_ "U_P702_MY2021_Rx" SG_ 1057 VehVLimStat_D_Actl 1;
BA_ "U_T6_MCA_MY2020_Rx" SG_ 1057 VehVLimStat_D_Actl 1;
BA_ "U_P702_MY2021_Tx" SG_ 1057 VehVLimStat_D_Actl 1;
BA_ "U_T6_MCA_MY2020_Tx" SG_ 1057 VehVLimStat_D_Actl 1;
BA_ " _InfoCAN" SG_ 1057 VehVLimActv_B_Actl 1;
BA_ "ContentDependant" SG_ 1057 VehVLimActv_B_Actl 1;
BA_ "U_P702_MY2021_Rx" SG_ 1057 VehVLimActv_B_Actl 1;
BA_ "U_T6_MCA_MY2020_Rx" SG_ 1057 VehVLimActv_B_Actl 1;
BA_ "U_P702_MY2021_Tx" SG_ 1057 VehVLimActv_B_Actl 1;
BA_ "U_T6_MCA_MY2020_Tx" SG_ 1057 VehVLimActv_B_Actl 1;
BA_ " _InfoCAN" SG_ 1057 CoolantFanStepAct 1;
BA_ "U_P702_MY2021_Tx" SG_ 1057 CoolantFanStepAct 1;
BA_ "U_T6_MCA_MY2020_Tx" SG_ 1057 CoolantFanStepAct 1;
BA_ "FrameRouting" BO_ 516 "";
BA_ "GenMsgSendType" BO_ 516 0;
BA_ "GenMsgCycleTime" BO_ 516 10;
BA_ "GenMsgDelayTime" BO_ 516 0;
BA_ "VFrameFormat" BO_ 516 14;
BA_ " _InfoCAN" SG_ 516 EngAoutNActl_D_QF 1;
BA_ "GenSigStartValueInteger" SG_ 516 EngAoutNActl_D_QF 1;
BA_ "MetaData" SG_ 516 EngAoutNActl_D_QF 1;
BA_ "GenSigStartValue" SG_ 516 EngAoutNActl_D_QF 1;
BA_ "U_P702_MY2021_Rx" SG_ 516 EngAoutNActl_D_QF 1;
BA_ "U_T6_MCA_MY2020_Rx" SG_ 516 EngAoutNActl_D_QF 1;
BA_ "U_P702_MY2021_Tx" SG_ 516 EngAoutNActl_D_QF 1;
BA_ "U_T6_MCA_MY2020_Tx" SG_ 516 EngAoutNActl_D_QF 1;
BA_ " _InfoCAN" SG_ 516 EngAout3_N_Actl 1;
BA_ "ContentDependant" SG_ 516 EngAout3_N_Actl 1;
BA_ "U_P702_MY2021_Tx" SG_ 516 EngAout3_N_Actl 1;
BA_ " _InfoCAN" SG_ 516 ApedPos_PcRate_ActlArb 1;
BA_ "U_P702_MY2021_Rx" SG_ 516 ApedPos_PcRate_ActlArb 1;
BA_ "U_T6_MCA_MY2020_Rx" SG_ 516 ApedPos_PcRate_ActlArb 1;
BA_ "U_P702_MY2021_Tx" SG_ 516 ApedPos_PcRate_ActlArb 1;
BA_ "U_T6_MCA_MY2020_Tx" SG_ 516 ApedPos_PcRate_ActlArb 1;
BA_ " _InfoCAN" SG_ 516 ApedPos_Pc_ActlArb 1;
BA_ "U_P702_MY2021_Rx" SG_ 516 ApedPos_Pc_ActlArb 1;
BA_ "U_T6_MCA_MY2020_Rx" SG_ 516 ApedPos_Pc_ActlArb 1;
BA_ "U_CX727_MY2021_Rx" SG_ 516 ApedPos_Pc_ActlArb 1;
BA_ "U_P702_MY2021_Tx" SG_ 516 ApedPos_Pc_ActlArb 1;
BA_ "U_T6_MCA_MY2020_Tx" SG_ 516 ApedPos_Pc_ActlArb 1;
BA_ "ECGUsedRxSignal" SG_ 516 ApedPos_Pc_ActlArb 1;
BA_ " _InfoCAN" SG_ 516 ApedPosPcActl_D_Qf 1;
BA_ "GenSigStartValueInteger" SG_ 516 ApedPosPcActl_D_Qf 1;
BA_ "MetaData" SG_ 516 ApedPosPcActl_D_Qf 1;
BA_ "GenSigStartValue" SG_ 516 ApedPosPcActl_D_Qf 1;
BA_ "U_P702_MY2021_Rx" SG_ 516 ApedPosPcActl_D_Qf 1;
BA_ "U_T6_MCA_MY2020_Rx" SG_ 516 ApedPosPcActl_D_Qf 1;
BA_ "U_CX727_MY2021_Rx" SG_ 516 ApedPosPcActl_D_Qf 1;
BA_ "U_P702_MY2021_Tx" SG_ 516 ApedPosPcActl_D_Qf 1;
BA_ "U_T6_MCA_MY2020_Tx" SG_ 516 ApedPosPcActl_D_Qf 1;
BA_ " _InfoCAN" SG_ 516 EngAout_N_Actl 1;
BA_ "U_P702_MY2021_Rx" SG_ 516 EngAout_N_Actl 1;
BA_ "U_T6_MCA_MY2020_Rx" SG_ 516 EngAout_N_Actl 1;
BA_ "U_CX727_MY2021_Rx" SG_ 516 EngAout_N_Actl 1;
BA_ "U_P702_MY2021_Tx" SG_ 516 EngAout_N_Actl 1;
BA_ "U_T6_MCA_MY2020_Tx" SG_ 516 EngAout_N_Actl 1;
BA_ "ECGUsedRxSignal" SG_ 516 EngAout_N_Actl 1;
BA_ " _InfoCAN" SG_ 516 ApedPosPcActl_No_Cnt 1;
BA_ "ContentDependant" SG_ 516 ApedPosPcActl_No_Cnt 1;
BA_ "MetaData" SG_ 516 ApedPosPcActl_No_Cnt 1;
BA_ "U_P702_MY2021_Tx" SG_ 516 ApedPosPcActl_No_Cnt 1;
BA_ "U_T6_MCA_MY2020_Tx" SG_ 516 ApedPosPcActl_No_Cnt 1;
BA_ " _InfoCAN" SG_ 516 ApedPosPcActl_No_Cs 1;
BA_ "ContentDependant" SG_ 516 ApedPosPcActl_No_Cs 1;
BA_ "MetaData" SG_ 516 ApedPosPcActl_No_Cs 1;
BA_ "U_P702_MY2021_Tx" SG_ 516 ApedPosPcActl_No_Cs 1;
BA_ "U_T6_MCA_MY2020_Tx" SG_ 516 ApedPosPcActl_No_Cs 1;
BA_ "FrameRouting" BO_ 514 "";
BA_ "GenMsgSendType" BO_ 514 0;
BA_ "GenMsgCycleTime" BO_ 514 20;
BA_ "GenMsgDelayTime" BO_ 514 10;
BA_ "VFrameFormat" BO_ 514 14;
BA_ "U_P702_MY2021_Tx" SG_ 514 StrtrMtrDlyStrt_B_Stat 1;
BA_ "U_T6_MCA_MY2020_Tx" SG_ 514 StrtrMtrDlyStrt_B_Stat 1;
BA_ "U_P702_MY2021_Rx" SG_ 514 VehVTrlrAid_B_Avail 1;
BA_ "U_P702_MY2021_Tx" SG_ 514 VehVTrlrAid_B_Avail 1;
BA_ "U_T6_MCA_MY2020_Tx" SG_ 514 VehVTrlrAid_B_Avail 1;
BA_ " _InfoCAN" SG_ 514 StrtrMtrCtlMsgTxt_D_Rq 1;
BA_ "U_P702_MY2021_Tx" SG_ 514 StrtrMtrCtlMsgTxt_D_Rq 1;
BA_ "U_T6_MCA_MY2020_Tx" SG_ 514 StrtrMtrCtlMsgTxt_D_Rq 1;
BA_ " _InfoCAN" SG_ 514 VehVActlEng_No_Cs 1;
BA_ "MetaData" SG_ 514 VehVActlEng_No_Cs 1;
BA_ "U_CX727_MY2021_Rx" SG_ 514 VehVActlEng_No_Cs 1;
BA_ "U_P702_MY2021_Rx" SG_ 514 VehVActlEng_No_Cs 1;
BA_ "U_P702_MY2021_Tx" SG_ 514 VehVActlEng_No_Cs 1;
BA_ "U_T6_MCA_MY2020_Tx" SG_ 514 VehVActlEng_No_Cs 1;
BA_ " _InfoCAN" SG_ 514 VehVActlEng_No_Cnt 1;
BA_ "MetaData" SG_ 514 VehVActlEng_No_Cnt 1;
BA_ "U_CX727_MY2021_Rx" SG_ 514 VehVActlEng_No_Cnt 1;
BA_ "U_P702_MY2021_Rx" SG_ 514 VehVActlEng_No_Cnt 1;
BA_ "U_P702_MY2021_Tx" SG_ 514 VehVActlEng_No_Cnt 1;
BA_ "U_T6_MCA_MY2020_Tx" SG_ 514 VehVActlEng_No_Cnt 1;
BA_ " _InfoCAN" SG_ 514 Veh_V_RqCcSet 1;
BA_ "U_P702_MY2021_Rx" SG_ 514 Veh_V_RqCcSet 1;
BA_ "U_T6_MCA_MY2020_Rx" SG_ 514 Veh_V_RqCcSet 1;
BA_ "U_CX727_MY2021_Rx" SG_ 514 Veh_V_RqCcSet 1;
BA_ "U_P702_MY2021_Tx" SG_ 514 Veh_V_RqCcSet 1;
BA_ "U_T6_MCA_MY2020_Tx" SG_ 514 Veh_V_RqCcSet 1;
BA_ " _InfoCAN" SG_ 514 VehVActlEng_D_Qf 1;
BA_ "MetaData" SG_ 514 VehVActlEng_D_Qf 1;
BA_ "U_P702_MY2021_Rx" SG_ 514 VehVActlEng_D_Qf 1;
BA_ "U_T6_MCA_MY2020_Rx" SG_ 514 VehVActlEng_D_Qf 1;
BA_ "U_CX727_MY2021_Rx" SG_ 514 VehVActlEng_D_Qf 1;
BA_ "U_P702_MY2021_Tx" SG_ 514 VehVActlEng_D_Qf 1;
BA_ "U_T6_MCA_MY2020_Tx" SG_ 514 VehVActlEng_D_Qf 1;
BA_ " _InfoCAN" SG_ 514 Veh_V_ActlEng 1;
BA_ "U_P702_MY2021_Rx" SG_ 514 Veh_V_ActlEng 1;
BA_ "U_T6_MCA_MY2020_Rx" SG_ 514 Veh_V_ActlEng 1;
BA_ "U_CX727_MY2021_Rx" SG_ 514 Veh_V_ActlEng 1;
BA_ "U_P702_MY2021_Tx" SG_ 514 Veh_V_ActlEng 1;
BA_ "U_T6_MCA_MY2020_Tx" SG_ 514 Veh_V_ActlEng 1;
BA_ "ECGUsedRxSignal" SG_ 514 Veh_V_ActlEng 1;
BA_ " _InfoCAN" SG_ 514 GearRvrse_D_Actl 1;
BA_ "GenSigStartValueInteger" SG_ 514 GearRvrse_D_Actl 7;
BA_ "GenSigStartValue" SG_ 514 GearRvrse_D_Actl 7;
BA_ "U_CX727_MY2021_Rx" SG_ 514 GearRvrse_D_Actl 1;
BA_ "U_P702_MY2021_Rx" SG_ 514 GearRvrse_D_Actl 1;
BA_ "U_P702_MY2021_Tx" SG_ 514 GearRvrse_D_Actl 1;
BA_ "U_T6_MCA_MY2020_Tx" SG_ 514 GearRvrse_D_Actl 1;
BA_ "ECGUsedRxSignal" SG_ 514 GearRvrse_D_Actl 1;
BA_ "U_P702_MY2021_Tx" SG_ 514 StrtrMtrCtlMsgTxt_D2_Rq 1;
BA_ "U_T6_MCA_MY2020_Tx" SG_ 514 StrtrMtrCtlMsgTxt_D2_Rq 1;
BA_ "FrameRouting" BO_ 512 "";
BA_ "GenMsgSendType" BO_ 512 0;
BA_ "GenMsgCycleTime" BO_ 512 20;
BA_ "GenMsgDelayTime" BO_ 512 10;
BA_ "VFrameFormat" BO_ 512 14;
BA_ "ContentDependant" SG_ 512 PrplWhlTotTqRq_No_Cs 1;
BA_ "MetaData" SG_ 512 PrplWhlTotTqRq_No_Cs 1;
BA_ "U_P702_MY2021_Rx" SG_ 512 PrplWhlTotTqRq_No_Cs 1;
BA_ "U_P702_MY2021_Tx" SG_ 512 PrplWhlTotTqRq_No_Cs 1;
BA_ "ContentDependant" SG_ 512 PrplWhlTotTqRq_No_Cnt 1;
BA_ "MetaData" SG_ 512 PrplWhlTotTqRq_No_Cnt 1;
BA_ "U_P702_MY2021_Rx" SG_ 512 PrplWhlTotTqRq_No_Cnt 1;
BA_ "U_P702_MY2021_Tx" SG_ 512 PrplWhlTotTqRq_No_Cnt 1;
BA_ "U_CX727_MY2021_Rx" SG_ 512 PrplWhlTot_Tq_Rq 1;
BA_ "U_P702_MY2021_Rx" SG_ 512 PrplWhlTot_Tq_Rq 1;
BA_ "U_P702_MY2021_Tx" SG_ 512 PrplWhlTot_Tq_Rq 1;
BA_ "U_T6_MCA_MY2020_Tx" SG_ 512 PrplWhlTot_Tq_Rq 1;
BA_ "U_CX727_MY2021_Rx" SG_ 512 PrplWhlTot_Tq_LimMn 1;
BA_ "U_P702_MY2021_Rx" SG_ 512 PrplWhlTot_Tq_LimMn 1;
BA_ "U_P702_MY2021_Tx" SG_ 512 PrplWhlTot_Tq_LimMn 1;
BA_ "U_T6_MCA_MY2020_Tx" SG_ 512 PrplWhlTot_Tq_LimMn 1;
BA_ "U_T6_MCA_MY2020_Tx" SG_ 512 PtDrvMde_D_Stat 1;
BA_ "U_P702_MY2021_Tx" SG_ 512 PtDrvMde_D_Stat 1;
BA_ "FrameRouting" BO_ 377 "";
BA_ "GenMsgSendType" BO_ 377 0;
BA_ "GenMsgCycleTime" BO_ 377 100;
BA_ "VFrameFormat" BO_ 377 14;
BA_ "U_P702_MY2021_Tx" SG_ 377 HvacAirFullOut_B_Rq 1;
BA_ " _InfoCAN" SG_ 377 FuelFlw_Vl_Dsply 1;
BA_ "ContentDependant" SG_ 377 FuelFlw_Vl_Dsply 1;
BA_ "U_P702_MY2021_Tx" SG_ 377 FuelFlw_Vl_Dsply 1;
BA_ "U_T6_MCA_MY2020_Tx" SG_ 377 FuelFlw_Vl_Dsply 1;
BA_ "ECGUsedRxSignal" SG_ 377 FuelFlw_Vl_Dsply 1;
BA_ " _InfoCAN" SG_ 377 FuelFillInlet_B_Dsply 1;
BA_ "ContentDependant" SG_ 377 FuelFillInlet_B_Dsply 1;
BA_ "U_P702_MY2021_Tx" SG_ 377 FuelFillInlet_B_Dsply 1;
BA_ "U_T6_MCA_MY2020_Tx" SG_ 377 FuelFillInlet_B_Dsply 1;
BA_ " _InfoCAN" SG_ 377 EngSrvcRqd_B_Rq 1;
BA_ "U_P702_MY2021_Tx" SG_ 377 EngSrvcRqd_B_Rq 1;
BA_ "U_T6_MCA_MY2020_Tx" SG_ 377 EngSrvcRqd_B_Rq 1;
BA_ "ECGUsedRxSignal" SG_ 377 EngSrvcRqd_B_Rq 1;
BA_ " _InfoCAN" SG_ 377 OdoCount 1;
BA_ "ContentDependant" SG_ 377 OdoCount 1;
BA_ "U_P702_MY2021_Tx" SG_ 377 OdoCount 1;
BA_ "U_T6_MCA_MY2020_Tx" SG_ 377 OdoCount 1;
BA_ " _InfoCAN" SG_ 377 EngOilLife_Pc_Actl 1;
BA_ "ContentDependant" SG_ 377 EngOilLife_Pc_Actl 1;
BA_ "U_P702_MY2021_Tx" SG_ 377 EngOilLife_Pc_Actl 1;
BA_ "U_T6_MCA_MY2020_Tx" SG_ 377 EngOilLife_Pc_Actl 1;
BA_ "ECGUsedRxSignal" SG_ 377 EngOilLife_Pc_Actl 1;
BA_ " _InfoCAN" SG_ 377 FuelFilterLamp_B_Dsply 1;
BA_ "U_P702_MY2021_Tx" SG_ 377 FuelFilterLamp_B_Dsply 1;
BA_ "U_T6_MCA_MY2020_Tx" SG_ 377 FuelFilterLamp_B_Dsply 1;
BA_ "ECGUsedRxSignal" SG_ 377 FuelFilterLamp_B_Dsply 1;
BA_ " _InfoCAN" SG_ 377 AirCondRec_B_Rq 1;
BA_ "ContentDependant" SG_ 377 AirCondRec_B_Rq 1;
BA_ "U_P702_MY2021_Tx" SG_ 377 AirCondRec_B_Rq 1;
BA_ "U_T6_MCA_MY2020_Tx" SG_ 377 AirCondRec_B_Rq 1;
BA_ " _InfoCAN" SG_ 377 AirCondClutch_B_Stats 1;
BA_ "ContentDependant" SG_ 377 AirCondClutch_B_Stats 1;
BA_ "U_P702_MY2021_Tx" SG_ 377 AirCondClutch_B_Stats 1;
BA_ "U_T6_MCA_MY2020_Tx" SG_ 377 AirCondClutch_B_Stats 1;
BA_ "FrameRouting" BO_ 376 "";
BA_ "GenMsgSendType" BO_ 376 0;
BA_ "GenMsgCycleTime" BO_ 376 100;
BA_ "VFrameFormat" BO_ 376 14;
BA_ "U_P702_MY2021_Tx" SG_ 376 GasPrtc_D_RqDsply 1;
BA_ "U_T6_MCA_MY2020_Tx" SG_ 376 GasPrtc_D_RqDsply 1;
BA_ " _InfoCAN" SG_ 376 EngAout_Aa_Actl 1;
BA_ "ContentDependant" SG_ 376 EngAout_Aa_Actl 1;
BA_ "U_CX727_MY2021_Rx" SG_ 376 EngAout_Aa_Actl 1;
BA_ "U_P702_MY2021_Rx" SG_ 376 EngAout_Aa_Actl 1;
BA_ "U_P702_MY2021_Tx" SG_ 376 EngAout_Aa_Actl 1;
BA_ "U_T6_MCA_MY2020_Tx" SG_ 376 EngAout_Aa_Actl 1;
BA_ "U_CX727_MY2021_Rx" SG_ 376 DynoMde_B_Cmd 1;
BA_ "U_P702_MY2021_Rx" SG_ 376 DynoMde_B_Cmd 1;
BA_ "U_T6_MCA_MY2020_Rx" SG_ 376 DynoMde_B_Cmd 1;
BA_ "U_P702_MY2021_Tx" SG_ 376 DynoMde_B_Cmd 1;
BA_ "U_T6_MCA_MY2020_Tx" SG_ 376 DynoMde_B_Cmd 1;
BA_ "U_P702_MY2021_Tx" SG_ 376 AslIconDsply_D_Rq 1;
BA_ "U_T6_MCA_MY2020_Tx" SG_ 376 AslIconDsply_D_Rq 1;
BA_ "U_P702_MY2021_Tx" SG_ 376 AslChime_B_Rq 1;
BA_ "U_T6_MCA_MY2020_Tx" SG_ 376 AslChime_B_Rq 1;
BA_ "GenSigStartValueInteger" SG_ 376 HvacHtrCore2_Te_Actl 200;
BA_ "U_P702_MY2021_Tx" SG_ 376 HvacHtrCore2_Te_Actl 1;
BA_ "U_P702_MY2021_Tx" SG_ 376 EcssLamp_D_RqDsply 1;
BA_ "U_T6_MCA_MY2020_Tx" SG_ 376 EcssLamp_D_RqDsply 1;
BA_ " _InfoCAN" SG_ 376 AirAmbTe_D_Qf 1;
BA_ "GenSigStartValueInteger" SG_ 376 AirAmbTe_D_Qf 1;
BA_ "MetaData" SG_ 376 AirAmbTe_D_Qf 1;
BA_ "GenSigStartValue" SG_ 376 AirAmbTe_D_Qf 1;
BA_ "U_P702_MY2021_Rx" SG_ 376 AirAmbTe_D_Qf 1;
BA_ "U_CX727_MY2021_Rx" SG_ 376 AirAmbTe_D_Qf 1;
BA_ "U_P702_MY2021_Tx" SG_ 376 AirAmbTe_D_Qf 1;
BA_ "U_T6_MCA_MY2020_Tx" SG_ 376 AirAmbTe_D_Qf 1;
BA_ " _InfoCAN" SG_ 376 AirAmb_Te_ActlFilt 1;
BA_ "GenSigStartValueInteger" SG_ 376 AirAmb_Te_ActlFilt 512;
BA_ "U_P702_MY2021_Tx" SG_ 376 AirAmb_Te_ActlFilt 1;
BA_ "U_T6_MCA_MY2020_Tx" SG_ 376 AirAmb_Te_ActlFilt 1;
BA_ "ECGUsedRxSignal" SG_ 376 AirAmb_Te_ActlFilt 1;
BA_ " _InfoCAN" SG_ 376 AirAmb_Te_Actl 1;
BA_ "GenSigStartValueInteger" SG_ 376 AirAmb_Te_Actl 512;
BA_ "U_P702_MY2021_Rx" SG_ 376 AirAmb_Te_Actl 1;
BA_ "U_CX727_MY2021_Rx" SG_ 376 AirAmb_Te_Actl 1;
BA_ "U_P702_MY2021_Tx" SG_ 376 AirAmb_Te_Actl 1;
BA_ "U_T6_MCA_MY2020_Tx" SG_ 376 AirAmb_Te_Actl 1;
BA_ " _InfoCAN" SG_ 376 AirAmb_P_Actl 1;
BA_ "U_P702_MY2021_Rx" SG_ 376 AirAmb_P_Actl 1;
BA_ "U_T6_MCA_MY2020_Rx" SG_ 376 AirAmb_P_Actl 1;
BA_ "U_P702_MY2021_Tx" SG_ 376 AirAmb_P_Actl 1;
BA_ "U_T6_MCA_MY2020_Tx" SG_ 376 AirAmb_P_Actl 1;
BA_ "FrameRouting" BO_ 359 "";
BA_ "GenMsgSendType" BO_ 359 0;
BA_ "GenMsgCycleTime" BO_ 359 10;
BA_ "GenMsgDelayTime" BO_ 359 0;
BA_ "VFrameFormat" BO_ 359 14;
BA_ "GenSigStartValueInteger" SG_ 359 PrplWhlRgenMn_Tq_Actl 4095;
BA_ "U_CX727_MY2021_Rx" SG_ 359 PrplWhlRgenMn_Tq_Actl 1;
BA_ "U_P702_MY2021_Rx" SG_ 359 PrplWhlRgenMn_Tq_Actl 1;
BA_ "U_P702_MY2021_Tx" SG_ 359 PrplWhlRgenMn_Tq_Actl 1;
BA_ " _InfoCAN" SG_ 359 ElPw_D_StatStrtStop 1;
BA_ "U_P702_MY2021_Rx" SG_ 359 ElPw_D_StatStrtStop 1;
BA_ "U_P702_MY2021_Tx" SG_ 359 ElPw_D_StatStrtStop 1;
BA_ "U_T6_MCA_MY2020_Tx" SG_ 359 ElPw_D_StatStrtStop 1;
BA_ " _InfoCAN" SG_ 359 TrnAin_Tq_Actl 1;
BA_ "ContentDependant" SG_ 359 TrnAin_Tq_Actl 1;
BA_ "U_CX727_MY2021_Rx" SG_ 359 TrnAin_Tq_Actl 1;
BA_ "U_P702_MY2021_Rx" SG_ 359 TrnAin_Tq_Actl 1;
BA_ "U_P702_MY2021_Tx" SG_ 359 TrnAin_Tq_Actl 1;
BA_ "U_T6_MCA_MY2020_Tx" SG_ 359 TrnAin_Tq_Actl 1;
BA_ " _InfoCAN" SG_ 359 PrplWhlTot2_Tq_Actl 1;
BA_ "U_P702_MY2021_Rx" SG_ 359 PrplWhlTot2_Tq_Actl 1;
BA_ "U_CX727_MY2021_Rx" SG_ 359 PrplWhlTot2_Tq_Actl 1;
BA_ "U_P702_MY2021_Tx" SG_ 359 PrplWhlTot2_Tq_Actl 1;
BA_ "U_T6_MCA_MY2020_Tx" SG_ 359 PrplWhlTot2_Tq_Actl 1;
BA_ "ECGUsedRxSignal" SG_ 359 PrplWhlTot2_Tq_Actl 1;
BA_ " _InfoCAN" SG_ 359 PwPckTq_D_Stat 1;
BA_ "U_P702_MY2021_Rx" SG_ 359 PwPckTq_D_Stat 1;
BA_ "U_T6_MCA_MY2020_Rx" SG_ 359 PwPckTq_D_Stat 1;
BA_ "U_CX727_MY2021_Rx" SG_ 359 PwPckTq_D_Stat 1;
BA_ "U_P702_MY2021_Tx" SG_ 359 PwPckTq_D_Stat 1;
BA_ "U_T6_MCA_MY2020_Tx" SG_ 359 PwPckTq_D_Stat 1;
BA_ "ECGUsedRxSignal" SG_ 359 PwPckTq_D_Stat 1;
BA_ " _InfoCAN" SG_ 359 Eng_D_Stat 1;
BA_ "U_CX727_MY2021_Rx" SG_ 359 Eng_D_Stat 1;
BA_ "U_P702_MY2021_Rx" SG_ 359 Eng_D_Stat 1;
BA_ "U_P702_MY2021_Tx" SG_ 359 Eng_D_Stat 1;
BA_ "U_T6_MCA_MY2020_Tx" SG_ 359 Eng_D_Stat 1;
BA_ "ECGUsedRxSignal" SG_ 359 Eng_D_Stat 1;
BA_ " _InfoCAN" SG_ 359 PlgActvArb_B_Actl 1;
BA_ "GenSigStartValueInteger" SG_ 359 PlgActvArb_B_Actl 1;
BA_ "ContentDependant" SG_ 359 PlgActvArb_B_Actl 1;
BA_ "GenSigStartValue" SG_ 359 PlgActvArb_B_Actl 1;
BA_ "ECGUsedRxSignal" SG_ 359 PlgActvArb_B_Actl 1;
BA_ " _InfoCAN" SG_ 359 ElPw_D_Stat 1;
BA_ "U_P702_MY2021_Rx" SG_ 359 ElPw_D_Stat 1;
BA_ "U_T6_MCA_MY2020_Rx" SG_ 359 ElPw_D_Stat 1;
BA_ "U_CX727_MY2021_Rx" SG_ 359 ElPw_D_Stat 1;
BA_ "U_P702_MY2021_Tx" SG_ 359 ElPw_D_Stat 1;
BA_ "U_T6_MCA_MY2020_Tx" SG_ 359 ElPw_D_Stat 1;
BA_ " _InfoCAN" SG_ 359 TrnAinTq_D_Qf 1;
BA_ "ContentDependant" SG_ 359 TrnAinTq_D_Qf 1;
BA_ "MetaData" SG_ 359 TrnAinTq_D_Qf 1;
BA_ "U_CX727_MY2021_Rx" SG_ 359 TrnAinTq_D_Qf 1;
BA_ "U_P702_MY2021_Rx" SG_ 359 TrnAinTq_D_Qf 1;
BA_ "U_P702_MY2021_Tx" SG_ 359 TrnAinTq_D_Qf 1;
BA_ "U_T6_MCA_MY2020_Tx" SG_ 359 TrnAinTq_D_Qf 1;
BA_ "FrameRouting" BO_ 358 "";
BA_ "GenMsgSendType" BO_ 358 0;
BA_ "GenMsgCycleTime" BO_ 358 100;
BA_ "VFrameFormat" BO_ 358 14;
BA_ " _InfoCAN" SG_ 358 StopStrtStdby_D_Indic 1;
BA_ "U_P702_MY2021_Tx" SG_ 358 StopStrtStdby_D_Indic 1;
BA_ "U_T6_MCA_MY2020_Tx" SG_ 358 StopStrtStdby_D_Indic 1;
BA_ " _InfoCAN" SG_ 358 StopStrtIODTxt_D_Rq 1;
BA_ "U_P702_MY2021_Tx" SG_ 358 StopStrtIODTxt_D_Rq 1;
BA_ "U_T6_MCA_MY2020_Tx" SG_ 358 StopStrtIODTxt_D_Rq 1;
BA_ " _InfoCAN" SG_ 358 StopStrtDrvMde_D_Indic 1;
BA_ "U_P702_MY2021_Tx" SG_ 358 StopStrtDrvMde_D_Indic 1;
BA_ "U_T6_MCA_MY2020_Tx" SG_ 358 StopStrtDrvMde_D_Indic 1;
BA_ " _InfoCAN" SG_ 358 StopStrtMsgTxt_D_Rq 1;
BA_ "U_P702_MY2021_Tx" SG_ 358 StopStrtMsgTxt_D_Rq 1;
BA_ "U_T6_MCA_MY2020_Tx" SG_ 358 StopStrtMsgTxt_D_Rq 1;
BA_ " _InfoCAN" SG_ 358 OdoTripVerify_L_Actl 1;
BA_ "U_P702_MY2021_Tx" SG_ 358 OdoTripVerify_L_Actl 1;
BA_ "U_T6_MCA_MY2020_Tx" SG_ 358 OdoTripVerify_L_Actl 1;
BA_ " _InfoCAN" SG_ 358 HiElPwInhbt_B_Stat 1;
BA_ "ContentDependant" SG_ 358 HiElPwInhbt_B_Stat 1;
BA_ "U_P702_MY2021_Tx" SG_ 358 HiElPwInhbt_B_Stat 1;
BA_ "U_T6_MCA_MY2020_Tx" SG_ 358 HiElPwInhbt_B_Stat 1;
BA_ " _InfoCAN" SG_ 358 AutoStopPtDelta_I_Est 1;
BA_ "GenSigStartValueInteger" SG_ 358 AutoStopPtDelta_I_Est 127;
BA_ "ContentDependant" SG_ 358 AutoStopPtDelta_I_Est 1;
BA_ "U_P702_MY2021_Tx" SG_ 358 AutoStopPtDelta_I_Est 1;
BA_ "U_T6_MCA_MY2020_Tx" SG_ 358 AutoStopPtDelta_I_Est 1;
BA_ "FrameRouting" BO_ 357 "";
BA_ "GenMsgSendType" BO_ 357 0;
BA_ "GenMsgCycleTime" BO_ 357 20;
BA_ "GenMsgDelayTime" BO_ 357 10;
BA_ "VFrameFormat" BO_ 357 14;
BA_ "GenSigStartValueInteger" SG_ 357 BPedDrvAppl_D_QF 1;
BA_ "MetaData" SG_ 357 BPedDrvAppl_D_QF 1;
BA_ "GenSigStartValue" SG_ 357 BPedDrvAppl_D_QF 1;
BA_ "U_P702_MY2021_Rx" SG_ 357 BPedDrvAppl_D_QF 1;
BA_ "U_T6_MCA_MY2020_Rx" SG_ 357 BPedDrvAppl_D_QF 1;
BA_ "U_CX727_MY2021_Rx" SG_ 357 BPedDrvAppl_D_QF 1;
BA_ "U_P702_MY2021_Tx" SG_ 357 BPedDrvAppl_D_QF 1;
BA_ "U_T6_MCA_MY2020_Tx" SG_ 357 BPedDrvAppl_D_QF 1;
BA_ "U_P702_MY2021_Tx" SG_ 357 CmbbDeny_B_ActlPrpl 1;
BA_ "U_T6_MCA_MY2020_Tx" SG_ 357 CmbbDeny_B_ActlPrpl 1;
BA_ "U_P702_MY2021_Tx" SG_ 357 PrplTqMnSat_B_Actl 1;
BA_ "U_T6_MCA_MY2020_Tx" SG_ 357 PrplTqMnSat_B_Actl 1;
BA_ " _InfoCAN" SG_ 357 BpedDrvAppl_D_Actl 1;
BA_ "GenSigStartValueInteger" SG_ 357 BpedDrvAppl_D_Actl 1;
BA_ "GenSigStartValue" SG_ 357 BpedDrvAppl_D_Actl 1;
BA_ "U_P702_MY2021_Rx" SG_ 357 BpedDrvAppl_D_Actl 1;
BA_ "U_T6_MCA_MY2020_Rx" SG_ 357 BpedDrvAppl_D_Actl 1;
BA_ "U_CX727_MY2021_Rx" SG_ 357 BpedDrvAppl_D_Actl 1;
BA_ "U_P702_MY2021_Tx" SG_ 357 BpedDrvAppl_D_Actl 1;
BA_ "U_T6_MCA_MY2020_Tx" SG_ 357 BpedDrvAppl_D_Actl 1;
BA_ "ECGUsedRxSignal" SG_ 357 BpedDrvAppl_D_Actl 1;
BA_ "U_P702_MY2021_Tx" SG_ 357 CmbbEngTqMn_B_Actl 1;
BA_ "U_T6_MCA_MY2020_Tx" SG_ 357 CmbbEngTqMn_B_Actl 1;
BA_ " _InfoCAN" SG_ 357 Veh_V_DsplyCcSet 1;
BA_ "U_P702_MY2021_Tx" SG_ 357 Veh_V_DsplyCcSet 1;
BA_ "U_T6_MCA_MY2020_Tx" SG_ 357 Veh_V_DsplyCcSet 1;
BA_ "U_P702_MY2021_Tx" SG_ 357 AccEngStat_D_Actl 1;
BA_ "U_T6_MCA_MY2020_Tx" SG_ 357 AccEngStat_D_Actl 1;
BA_ "U_CX727_MY2021_Rx" SG_ 357 CcMde_D_Actl 1;
BA_ "U_P702_MY2021_Rx" SG_ 357 CcMde_D_Actl 1;
BA_ "U_T6_MCA_MY2020_Rx" SG_ 357 CcMde_D_Actl 1;
BA_ "U_P702_MY2021_Tx" SG_ 357 CcMde_D_Actl 1;
BA_ "U_T6_MCA_MY2020_Tx" SG_ 357 CcMde_D_Actl 1;
BA_ " _InfoCAN" SG_ 357 CcStat_D_Actl 1;
BA_ "U_P702_MY2021_Rx" SG_ 357 CcStat_D_Actl 1;
BA_ "U_T6_MCA_MY2020_Rx" SG_ 357 CcStat_D_Actl 1;
BA_ "U_CX727_MY2021_Rx" SG_ 357 CcStat_D_Actl 1;
BA_ "U_P702_MY2021_Tx" SG_ 357 CcStat_D_Actl 1;
BA_ "U_T6_MCA_MY2020_Tx" SG_ 357 CcStat_D_Actl 1;
BA_ "U_P702_MY2021_Tx" SG_ 357 EngAout_N_MnAllw 1;
BA_ " _InfoCAN" SG_ 357 CcOvrrdActv_B_Actl 1;
BA_ "U_P702_MY2021_Rx" SG_ 357 CcOvrrdActv_B_Actl 1;
BA_ "U_T6_MCA_MY2020_Rx" SG_ 357 CcOvrrdActv_B_Actl 1;
BA_ "U_CX727_MY2021_Rx" SG_ 357 CcOvrrdActv_B_Actl 1;
BA_ "U_P702_MY2021_Tx" SG_ 357 CcOvrrdActv_B_Actl 1;
BA_ "U_T6_MCA_MY2020_Tx" SG_ 357 CcOvrrdActv_B_Actl 1;
BA_ "U_CX727_MY2021_Rx" SG_ 357 AccStopMde_D_Rq 1;
BA_ "U_P702_MY2021_Rx" SG_ 357 AccStopMde_D_Rq 1;
BA_ "U_P702_MY2021_Tx" SG_ 357 AccStopMde_D_Rq 1;
BA_ "U_T6_MCA_MY2020_Tx" SG_ 357 AccStopMde_D_Rq 1;
BA_ "FrameRouting" BO_ 342 "";
BA_ "GenMsgSendType" BO_ 342 0;
BA_ "GenMsgCycleTime" BO_ 342 100;
BA_ "VFrameFormat" BO_ 342 14;
BA_ " _InfoCAN" SG_ 342 EngOvrhtMitgActv_D_Ind 1;
BA_ "ContentDependant" SG_ 342 EngOvrhtMitgActv_D_Ind 1;
BA_ "U_P702_MY2021_Tx" SG_ 342 EngOvrhtMitgActv_D_Ind 1;
BA_ "U_T6_MCA_MY2020_Tx" SG_ 342 EngOvrhtMitgActv_D_Ind 1;
BA_ " _InfoCAN" SG_ 342 EngClntTe_D_Qf 1;
BA_ "MetaData" SG_ 342 EngClntTe_D_Qf 1;
BA_ "U_P702_MY2021_Rx" SG_ 342 EngClntTe_D_Qf 1;
BA_ "U_T6_MCA_MY2020_Rx" SG_ 342 EngClntTe_D_Qf 1;
BA_ "U_P702_MY2021_Tx" SG_ 342 EngClntTe_D_Qf 1;
BA_ "U_T6_MCA_MY2020_Tx" SG_ 342 EngClntTe_D_Qf 1;
BA_ " _InfoCAN" SG_ 342 EngGoutLss_Tq_Est 1;
BA_ "ContentDependant" SG_ 342 EngGoutLss_Tq_Est 1;
BA_ "U_P702_MY2021_Tx" SG_ 342 EngGoutLss_Tq_Est 1;
BA_ " _InfoCAN" SG_ 342 EngOil_Te_Actl 1;
BA_ "U_P702_MY2021_Tx" SG_ 342 EngOil_Te_Actl 1;
BA_ "U_T6_MCA_MY2020_Tx" SG_ 342 EngOil_Te_Actl 1;
BA_ " _InfoCAN" SG_ 342 EngClnt_Te_Actl 1;
BA_ "U_P702_MY2021_Rx" SG_ 342 EngClnt_Te_Actl 1;
BA_ "U_T6_MCA_MY2020_Rx" SG_ 342 EngClnt_Te_Actl 1;
BA_ "U_P702_MY2021_Tx" SG_ 342 EngClnt_Te_Actl 1;
BA_ "U_T6_MCA_MY2020_Tx" SG_ 342 EngClnt_Te_Actl 1;
BA_ "ECGUsedRxSignal" SG_ 342 EngClnt_Te_Actl 1;
BA_ "FrameRouting" BO_ 71 "";
BA_ "GenMsgSendType" BO_ 71 0;
BA_ "GenMsgCycleTime" BO_ 71 20;
BA_ "GenMsgDelayTime" BO_ 71 10;
BA_ "VFrameFormat" BO_ 71 14;
BA_ "U_P702_MY2021_Rx" SG_ 71 immoTarget1Status 1;
BA_ "U_T6_MCA_MY2020_Rx" SG_ 71 immoTarget1Status 1;
BA_ "U_CX727_MY2021_Rx" SG_ 71 immoTarget1Status 1;
BA_ "U_P702_MY2021_Tx" SG_ 71 immoTarget1Status 1;
BA_ "U_T6_MCA_MY2020_Tx" SG_ 71 immoTarget1Status 1;
BA_ "U_CX727_MY2021_Rx" SG_ 71 immoTarget1Data 1;
BA_ "U_P702_MY2021_Rx" SG_ 71 immoTarget1Data 1;
BA_ "U_P702_MY2021_Tx" SG_ 71 immoTarget1Data 1;
BA_ "U_T6_MCA_MY2020_Tx" SG_ 71 immoTarget1Data 1;
BA_ "U_CX727_MY2021_Rx" SG_ 71 immoTarget1Cmd 1;
BA_ "U_P702_MY2021_Rx" SG_ 71 immoTarget1Cmd 1;
BA_ "U_P702_MY2021_Tx" SG_ 71 immoTarget1Cmd 1;
BA_ "U_T6_MCA_MY2020_Tx" SG_ 71 immoTarget1Cmd 1;
BA_ "FrameRouting" BO_ 1438 "";
BA_ "GenMsgILSupport" BO_ 1438 0;
BA_ "NmAsrMessage" BO_ 1438 1;
BA_ "GenMsgSendType" BO_ 1438 0;
BA_ "GenMsgCycleTime" BO_ 1438 1000;
BA_ "NetworkInitialization" BO_ 1438 0;
BA_ "VFrameFormat" BO_ 1438 14;
BA_ "GenSigStartValueInteger" SG_ 1438 GWM_GWOnBoardTester 255;
BA_ "ContentDependant" SG_ 1438 GWM_GWOnBoardTester 1;
BA_ "GenSigStartValue" SG_ 1438 GWM_GWOnBoardTester 255;
BA_ "ECGUsedTxSignal" SG_ 1438 GWM_GWOnBoardTester 1;
BA_ "GenSigStartValueInteger" SG_ 1438 GWM_GWNMProxy 255;
BA_ "ContentDependant" SG_ 1438 GWM_GWNMProxy 1;
BA_ "GenSigStartValue" SG_ 1438 GWM_GWNMProxy 255;
BA_ "ECGUsedTxSignal" SG_ 1438 GWM_GWNMProxy 1;
BA_ "GenSigStartValueInteger" SG_ 1438 GWM_AutoSarNMReserved4 255;
BA_ "ContentDependant" SG_ 1438 GWM_AutoSarNMReserved4 1;
BA_ "GenSigStartValue" SG_ 1438 GWM_AutoSarNMReserved4 255;
BA_ "ECGUsedTxSignal" SG_ 1438 GWM_AutoSarNMReserved4 1;
BA_ "GenSigStartValueInteger" SG_ 1438 GWM_AutoSarNMReserved3 255;
BA_ "ContentDependant" SG_ 1438 GWM_AutoSarNMReserved3 1;
BA_ "GenSigStartValue" SG_ 1438 GWM_AutoSarNMReserved3 255;
BA_ "ECGUsedTxSignal" SG_ 1438 GWM_AutoSarNMReserved3 1;
BA_ "GenSigStartValueInteger" SG_ 1438 GWM_AutoSarNMReserved2 255;
BA_ "ContentDependant" SG_ 1438 GWM_AutoSarNMReserved2 1;
BA_ "GenSigStartValue" SG_ 1438 GWM_AutoSarNMReserved2 255;
BA_ "ECGUsedTxSignal" SG_ 1438 GWM_AutoSarNMReserved2 1;
BA_ "GenSigStartValueInteger" SG_ 1438 GWM_AutoSarNMReserved1 255;
BA_ "ContentDependant" SG_ 1438 GWM_AutoSarNMReserved1 1;
BA_ "GenSigStartValue" SG_ 1438 GWM_AutoSarNMReserved1 255;
BA_ "ECGUsedTxSignal" SG_ 1438 GWM_AutoSarNMReserved1 1;
BA_ "GenSigStartValueInteger" SG_ 1438 GWM_AutoSarNMNodeId 158;
BA_ "ContentDependant" SG_ 1438 GWM_AutoSarNMNodeId 1;
BA_ "GenSigStartValue" SG_ 1438 GWM_AutoSarNMNodeId 158;
BA_ "ECGUsedTxSignal" SG_ 1438 GWM_AutoSarNMNodeId 1;
BA_ "ContentDependant" SG_ 1438 GWM_AutoSarNMControl 1;
BA_ "ECGUsedTxSignal" SG_ 1438 GWM_AutoSarNMControl 1;
BA_ "FrameRouting" BO_ 131 "";
BA_ "FrameGatewayId" BO_ 131 131;
BA_ "FrameGatewayNetwork" BO_ 131 "HS2_CAN";
BA_ "VFrameFormat" BO_ 131 14;
BA_ "WakeupSignal" SG_ 131 HeadLghtHiFlash_D_Stat 1;
BA_ "WakeupSignal" SG_ 131 TurnLghtSwtch_D_Stat 1;
BA_ " _InfoCAN" SG_ 131 TurnLghtSwtch_D_Stat 1;
BA_ "U_CX727_MY2021_Rx" SG_ 131 TurnLghtSwtch_D_Stat 1;
BA_ "U_P702_MY2021_Rx" SG_ 131 TurnLghtSwtch_D_Stat 1;
BA_ "GenSigStartValueInteger" SG_ 131 WiprFront_D_Stat 15;
BA_ "GenSigStartValue" SG_ 131 WiprFront_D_Stat 15;
BA_ "U_P702_MY2021_Rx" SG_ 131 WiprFront_D_Stat 1;
BA_ "U_T6_MCA_MY2020_Rx" SG_ 131 WiprFront_D_Stat 1;
BA_ "U_CX727_MY2021_Rx" SG_ 131 WiprFront_D_Stat 1;
BA_ "GenSigStartValueInteger" SG_ 131 LghtAmb_D_Sns 7;
BA_ "GenSigStartValue" SG_ 131 LghtAmb_D_Sns 7;
BA_ "U_P702_MY2021_Rx" SG_ 131 LghtAmb_D_Sns 1;
BA_ "U_P702_MY2021_Rx" SG_ 131 AslButtnOnOffCnclPress 1;
BA_ "U_T6_MCA_MY2020_Rx" SG_ 131 AslButtnOnOffCnclPress 1;
BA_ "U_P702_MY2021_Rx" SG_ 131 AslButtnOnOffPress 1;
BA_ "U_T6_MCA_MY2020_Rx" SG_ 131 AslButtnOnOffPress 1;
BA_ "U_P702_MY2021_Rx" SG_ 131 CcAslButtnCnclPress 1;
BA_ "U_T6_MCA_MY2020_Rx" SG_ 131 CcAslButtnCnclPress 1;
BA_ "U_P702_MY2021_Rx" SG_ 131 CcAslButtnCnclResPress 1;
BA_ "U_T6_MCA_MY2020_Rx" SG_ 131 CcAslButtnCnclResPress 1;
BA_ "U_P702_MY2021_Rx" SG_ 131 CcAslButtnDeny_B_Actl 1;
BA_ "U_T6_MCA_MY2020_Rx" SG_ 131 CcAslButtnDeny_B_Actl 1;
BA_ "U_P702_MY2021_Rx" SG_ 131 CcAslButtnIndxDecPress 1;
BA_ "U_T6_MCA_MY2020_Rx" SG_ 131 CcAslButtnIndxDecPress 1;
BA_ "U_P702_MY2021_Rx" SG_ 131 CcAslButtnIndxIncPress 1;
BA_ "U_T6_MCA_MY2020_Rx" SG_ 131 CcAslButtnIndxIncPress 1;
BA_ "U_P702_MY2021_Rx" SG_ 131 CcAslButtnOnPress 1;
BA_ "U_T6_MCA_MY2020_Rx" SG_ 131 CcAslButtnOnPress 1;
BA_ "U_P702_MY2021_Rx" SG_ 131 CcAslButtnResIncPress 1;
BA_ "U_T6_MCA_MY2020_Rx" SG_ 131 CcAslButtnResIncPress 1;
BA_ "U_P702_MY2021_Rx" SG_ 131 CcAslButtnSetDecPress 1;
BA_ "U_T6_MCA_MY2020_Rx" SG_ 131 CcAslButtnSetDecPress 1;
BA_ "U_P702_MY2021_Rx" SG_ 131 CcAslButtnSetIncPress 1;
BA_ "U_T6_MCA_MY2020_Rx" SG_ 131 CcAslButtnSetIncPress 1;
BA_ "U_P702_MY2021_Rx" SG_ 131 CcAsllButtnResPress 1;
BA_ "U_T6_MCA_MY2020_Rx" SG_ 131 CcAsllButtnResPress 1;
BA_ "U_P702_MY2021_Rx" SG_ 131 CcButtnOffPress 1;
BA_ "U_T6_MCA_MY2020_Rx" SG_ 131 CcButtnOffPress 1;
BA_ "U_P702_MY2021_Rx" SG_ 131 CcButtnOnOffCnclPress 1;
BA_ "U_T6_MCA_MY2020_Rx" SG_ 131 CcButtnOnOffCnclPress 1;
BA_ "U_P702_MY2021_Rx" SG_ 131 CcButtnOnOffPress 1;
BA_ "U_T6_MCA_MY2020_Rx" SG_ 131 CcButtnOnOffPress 1;
BA_ "U_P702_MY2021_Rx" SG_ 131 CcButtnOnPress 1;
BA_ "U_T6_MCA_MY2020_Rx" SG_ 131 CcButtnOnPress 1;
BA_ "WakeupSignal" SG_ 131 HeadLghtHiOn_B_StatAhb 1;
BA_ " _InfoCAN" SG_ 131 HeadLghtHiOn_B_StatAhb 1;
BA_ "GenSigStartValueInteger" SG_ 131 WiprFrontSwtch_D_Stat 9;
BA_ "GenSigStartValue" SG_ 131 WiprFrontSwtch_D_Stat 9;
BA_ "WakeupSignal" SG_ 131 HeadLghtHiCtrl_D_RqAhb 1;
BA_ "U_P702_MY2021_Rx" SG_ 131 HeadLghtHiCtrl_D_RqAhb 1;
BA_ "FrameRouting" BO_ 968 "";
BA_ "FrameGatewayId" BO_ 968 968;
BA_ "FrameGatewayNetwork" BO_ 968 "HS3_CAN";
BA_ "VFrameFormat" BO_ 968 14;
BA_ "GenSigStartValueInteger" SG_ 968 SlMde_D_Rq 2;
BA_ "GenSigStartValue" SG_ 968 SlMde_D_Rq 2;
BA_ "U_P702_MY2021_Rx" SG_ 968 SlMde_D_Rq 1;
BA_ "U_T6_MCA_MY2020_Rx" SG_ 968 SlMde_D_Rq 1;
BA_ "GenSigStartValueInteger" SG_ 968 IsaOffst_D_Rq 14;
BA_ "GenSigStartValue" SG_ 968 IsaOffst_D_Rq 14;
BA_ "U_P702_MY2021_Rx" SG_ 968 IsaOffst_D_Rq 1;
BA_ "U_T6_MCA_MY2020_Rx" SG_ 968 IsaOffst_D_Rq 1;
BA_ "FrameRouting" BO_ 806 "";
BA_ "FrameGatewayId" BO_ 806 806;
BA_ "FrameGatewayNetwork" BO_ 806 "MS1_CAN";
BA_ "VFrameFormat" BO_ 806 14;
BA_ "U_P702_MY2021_Rx" SG_ 806 StopStrtDrvMde_B_RqBtn 1;
BA_ "U_T6_MCA_MY2020_Rx" SG_ 806 StopStrtDrvMde_B_RqBtn 1;
BA_ "U_P702_MY2021_Rx" SG_ 806 HvacHtrCore_Te_Rq 1;
BA_ "U_T6_MCA_MY2020_Rx" SG_ 806 HvacHtrCore_Te_Rq 1;
BA_ "U_P702_MY2021_Rx" SG_ 806 ClimtHeat_D_Rq 1;
BA_ "U_T6_MCA_MY2020_Rx" SG_ 806 ClimtHeat_D_Rq 1;
BA_ "U_P702_MY2021_Rx" SG_ 806 ClimtCool_D_Rq 1;
BA_ "U_T6_MCA_MY2020_Rx" SG_ 806 ClimtCool_D_Rq 1;
BA_ "GenSigStartValueInteger" SG_ 806 HvacEvap_Te_Rq 400;
BA_ "U_P702_MY2021_Rx" SG_ 806 HvacEvap_Te_Rq 1;
BA_ "U_T6_MCA_MY2020_Rx" SG_ 806 HvacEvap_Te_Rq 1;
BA_ "GenSigStartValueInteger" SG_ 806 HvacEvap_Te_Actl 400;
BA_ "U_P702_MY2021_Rx" SG_ 806 HvacEvap_Te_Actl 1;
BA_ "U_T6_MCA_MY2020_Rx" SG_ 806 HvacEvap_Te_Actl 1;
BA_ "U_P702_MY2021_Rx" SG_ 806 HvacAirCond_B_Rq 1;
BA_ "U_T6_MCA_MY2020_Rx" SG_ 806 HvacAirCond_B_Rq 1;
BA_ "GenSigStartValueInteger" SG_ 806 HvacEvap_Te_Offst 400;
BA_ "U_P702_MY2021_Rx" SG_ 806 HvacEvap_Te_Offst 1;
BA_ "U_T6_MCA_MY2020_Rx" SG_ 806 HvacEvap_Te_Offst 1;
BA_ "U_P702_MY2021_Rx" SG_ 806 ClimtPw_B_Rq 1;
BA_ "U_T6_MCA_MY2020_Rx" SG_ 806 ClimtPw_B_Rq 1;
BA_ "FrameRouting" BO_ 1072 "";
BA_ "FrameGatewayId" BO_ 1072 1072;
BA_ "FrameGatewayNetwork" BO_ 1072 "HS3_CAN";
BA_ "VFrameFormat" BO_ 1072 14;
BA_ " _InfoCAN" SG_ 1072 DrvSlipCtlMde_D_Rq 1;
BA_ "U_P702_MY2021_Rx" SG_ 1072 DrvSlipCtlMde_D_Rq 1;
BA_ "U_P702_MY2021_Rx" SG_ 1072 EngIdlShutDown_B_RqDrv 1;
BA_ "U_T6_MCA_MY2020_Rx" SG_ 1072 EngIdlShutDown_B_RqDrv 1;
BA_ " _InfoCAN" SG_ 1072 HsaMde_D_Rq 1;
BA_ "GenSigStartValueInteger" SG_ 1072 HsaMde_D_Rq 1;
BA_ "GenSigStartValue" SG_ 1072 HsaMde_D_Rq 1;
BA_ " _InfoCAN" SG_ 1072 NtrlTowMdeEnbl_B_RqDrv 1;
BA_ "U_P702_MY2021_Rx" SG_ 1072 NtrlTowMdeEnbl_B_RqDrv 1;
BA_ "U_T6_MCA_MY2020_Rx" SG_ 1072 NtrlTowMdeEnbl_B_RqDrv 1;
BA_ " _InfoCAN" SG_ 1072 BulbChkActv_B_Stat 1;
BA_ " _InfoCAN" SG_ 1072 ParkDetect_Stat 1;
BA_ " _InfoCAN" SG_ 1072 ReducedGuard_D_Rq 1;
BA_ "U_P702_MY2021_Rx" SG_ 1072 TRLR_SWAY_CONFIG_CMD 1;
BA_ "WakeupSignal" SG_ 1072 Power_Liftgate_Mode_Cmd 1;
BA_ " _InfoCAN" SG_ 1072 Power_Liftgate_Mode_Cmd 1;
BA_ " _InfoCAN" SG_ 1072 AccEnbl_B_RqDrv 1;
BA_ "GenSigStartValueInteger" SG_ 1072 AccEnbl_B_RqDrv 1;
BA_ "GenSigStartValue" SG_ 1072 AccEnbl_B_RqDrv 1;
BA_ " _InfoCAN" SG_ 1072 OdometerMasterValue 1;
BA_ "U_P702_MY2021_Rx" SG_ 1072 OdometerMasterValue 1;
BA_ "U_T6_MCA_MY2020_Rx" SG_ 1072 OdometerMasterValue 1;
BA_ "U_CX727_MY2021_Rx" SG_ 1072 OdometerMasterValue 1;
BA_ " _InfoCAN" SG_ 1072 EngOilLife_B_RqReset 1;
BA_ "U_P702_MY2021_Rx" SG_ 1072 EngOilLife_B_RqReset 1;
BA_ "U_T6_MCA_MY2020_Rx" SG_ 1072 EngOilLife_B_RqReset 1;
BA_ "WakeupSignal" SG_ 1072 ePRNDL_MODE 1;
BA_ " _InfoCAN" SG_ 1072 ePRNDL_MODE 1;
BA_ "U_P702_MY2021_Rx" SG_ 1072 ePRNDL_MODE 1;
BA_ "U_T6_MCA_MY2020_Rx" SG_ 1072 ePRNDL_MODE 1;
BA_ " _InfoCAN" SG_ 1072 DrvSlipCtlMde_B_Rq2 1;
BA_ "U_P702_MY2021_Rx" SG_ 1072 DrvSlipCtlMde_B_Rq2 1;
BA_ " _InfoCAN" SG_ 1072 MetricActv_B_Actl 1;
BA_ "U_P702_MY2021_Rx" SG_ 1072 MetricActv_B_Actl 1;
BA_ "U_T6_MCA_MY2020_Rx" SG_ 1072 MetricActv_B_Actl 1;
BA_ " _InfoCAN" SG_ 1072 KeyTypeChngMykey_D_Rq 1;
BA_ " _InfoCAN" SG_ 1072 ManRgen_D_Rq 1;
BA_ "U_P702_MY2021_Rx" SG_ 1072 ManRgen_D_Rq 1;
BA_ "U_T6_MCA_MY2020_Rx" SG_ 1072 ManRgen_D_Rq 1;
BA_ "FrameRouting" BO_ 963 "";
BA_ "FrameGatewayId" BO_ 963 963;
BA_ "FrameGatewayNetwork" BO_ 963 "HS1_CAN";
BA_ "VFrameFormat" BO_ 963 14;
BA_ "WakeupSignal" SG_ 963 ImpactEvntFdbck_D_Stat 1;
BA_ " _InfoCAN" SG_ 963 ImpactEvntFdbck_D_Stat 1;
BA_ " _InfoCAN" SG_ 963 HeadLampLoOut_B_Stat 1;
BA_ " _InfoCAN" SG_ 963 CrnrLghtRight_Pc_Rq 1;
BA_ "U_P702_MY2021_Rx" SG_ 963 CrnrLghtRight_Pc_Rq 1;
BA_ " _InfoCAN" SG_ 963 CrnrLghtLeft_Pc_Rq 1;
BA_ "U_P702_MY2021_Rx" SG_ 963 CrnrLghtLeft_Pc_Rq 1;
BA_ " _InfoCAN" SG_ 963 HeadLghtHiFdbck_D_Stat 1;
BA_ " _InfoCAN" SG_ 963 TrnNotInPrkChime_B_Rq 1;
BA_ " _InfoCAN" SG_ 963 PrkLightChime_B_Rq 1;
BA_ "WakeupSignal" SG_ 963 KeyInIgnWarn_B_Cmd 1;
BA_ " _InfoCAN" SG_ 963 KeyInIgnWarn_B_Cmd 1;
BA_ "WakeupSignal" SG_ 963 HomeSafeLtChime_B_Rq 1;
BA_ " _InfoCAN" SG_ 963 HomeSafeLtChime_B_Rq 1;
BA_ "WakeupSignal" SG_ 963 StopLghtOn_B_Stat 1;
BA_ " _InfoCAN" SG_ 963 StopLghtOn_B_Stat 1;
BA_ "U_P702_MY2021_Rx" SG_ 963 StopLghtOn_B_Stat 1;
BA_ " _InfoCAN" SG_ 963 RvrseLghtOn_B_Stat 1;
BA_ "WakeupSignal" SG_ 963 PrkLght_D_Stat 1;
BA_ " _InfoCAN" SG_ 963 PrkLght_D_Stat 1;
BA_ "WakeupSignal" SG_ 963 HeadLghtSwtch_D_Stat 1;
BA_ " _InfoCAN" SG_ 963 HeadLghtSwtch_D_Stat 1;
BA_ "GenSigStartValueInteger" SG_ 963 HeadLghtSwtch_D_Stat 2;
BA_ "GenSigStartValue" SG_ 963 HeadLghtSwtch_D_Stat 2;
BA_ "U_P702_MY2021_Rx" SG_ 963 HeadLghtSwtch_D_Stat 1;
BA_ " _InfoCAN" SG_ 963 HeadLampLoFrOn_B_Stat 1;
BA_ "GenSigStartValueInteger" SG_ 963 HeadLampLoFrOn_B_Stat 1;
BA_ "GenSigStartValue" SG_ 963 HeadLampLoFrOn_B_Stat 1;
BA_ "U_P702_MY2021_Rx" SG_ 963 HeadLampLoFrOn_B_Stat 1;
BA_ " _InfoCAN" SG_ 963 HeadLampLoFlOn_B_Stat 1;
BA_ "GenSigStartValueInteger" SG_ 963 HeadLampLoFlOn_B_Stat 1;
BA_ "GenSigStartValue" SG_ 963 HeadLampLoFlOn_B_Stat 1;
BA_ "U_P702_MY2021_Rx" SG_ 963 HeadLampLoFlOn_B_Stat 1;
BA_ " _InfoCAN" SG_ 963 HeadLampLoActv_B_Stat 1;
BA_ "GenSigStartValueInteger" SG_ 963 HeadLampLoActv_B_Stat 1;
BA_ "GenSigStartValue" SG_ 963 HeadLampLoActv_B_Stat 1;
BA_ "U_P702_MY2021_Rx" SG_ 963 HeadLampLoActv_B_Stat 1;
BA_ "U_T6_MCA_MY2020_Rx" SG_ 963 HeadLampLoActv_B_Stat 1;
BA_ "WakeupSignal" SG_ 963 Headlamp_On_Wrning_Cmd 1;
BA_ " _InfoCAN" SG_ 963 Headlamp_On_Wrning_Cmd 1;
BA_ " _InfoCAN" SG_ 963 Park_Brake_Chime_Rqst 1;
BA_ "WakeupSignal" SG_ 963 HeadLghtHiOn_B_Stat 1;
BA_ " _InfoCAN" SG_ 963 HeadLghtHiOn_B_Stat 1;
BA_ "U_P702_MY2021_Rx" SG_ 963 HeadLghtHiOn_B_Stat 1;
BA_ "U_T6_MCA_MY2020_Rx" SG_ 963 HeadLghtHiOn_B_Stat 1;
BA_ " _InfoCAN" SG_ 963 BrkWarnInd_B_Rq 1;
BA_ " _InfoCAN" SG_ 963 Brk_Fluid_Lvl_Low 1;
BA_ " _InfoCAN" SG_ 963 ReducedGuard_D_Stat 1;
BA_ "WakeupSignal" SG_ 963 Perimeter_Alarm_Status 1;
BA_ " _InfoCAN" SG_ 963 Perimeter_Alarm_Status 1;
BA_ "WakeupSignal" SG_ 963 Courtesy_BSave_Stat 1;
BA_ " _InfoCAN" SG_ 963 Courtesy_BSave_Stat 1;
BA_ "GenSigStartValueInteger" SG_ 963 Courtesy_BSave_Stat 1;
BA_ "GenSigStartValue" SG_ 963 Courtesy_BSave_Stat 1;
BA_ "WakeupSignal" SG_ 963 WndwGlbl_D_Cmd 1;
BA_ " _InfoCAN" SG_ 963 WndwGlbl_D_Cmd 1;
BA_ "WakeupSignal" SG_ 963 PudLamp_D_Rq 1;
BA_ " _InfoCAN" SG_ 963 PudLamp_D_Rq 1;
BA_ " _InfoCAN" SG_ 963 DayRnngLampOn_B_Stat 1;
BA_ "U_P702_MY2021_Rx" SG_ 963 DayRnngLampOn_B_Stat 1;
BA_ "WakeupSignal" SG_ 963 PerimeterAlarmChimeRq 1;
BA_ " _InfoCAN" SG_ 963 PerimeterAlarmChimeRq 1;
BA_ "FrameRouting" BO_ 76 "";
BA_ "FrameGatewayId" BO_ 76 76;
BA_ "FrameGatewayNetwork" BO_ 76 "HS2_CAN";
BA_ "VFrameFormat" BO_ 76 14;
BA_ " _InfoCAN" SG_ 76 FirstRowBuckleMid 1;
BA_ "GenSigStartValueInteger" SG_ 76 FirstRowBuckleMid 3;
BA_ "GenSigStartValue" SG_ 76 FirstRowBuckleMid 3;
BA_ " _InfoCAN" SG_ 76 SecondRowBucklePsngr 1;
BA_ "GenSigStartValueInteger" SG_ 76 SecondRowBucklePsngr 3;
BA_ "GenSigStartValue" SG_ 76 SecondRowBucklePsngr 3;
BA_ " _InfoCAN" SG_ 76 SecondRowBuckleMid 1;
BA_ "GenSigStartValueInteger" SG_ 76 SecondRowBuckleMid 3;
BA_ "GenSigStartValue" SG_ 76 SecondRowBuckleMid 3;
BA_ " _InfoCAN" SG_ 76 SecondRowBuckleDriver 1;
BA_ "GenSigStartValueInteger" SG_ 76 SecondRowBuckleDriver 3;
BA_ "GenSigStartValue" SG_ 76 SecondRowBuckleDriver 3;
BA_ " _InfoCAN" SG_ 76 FirstRowBuckleDriver 1;
BA_ "GenSigStartValueInteger" SG_ 76 FirstRowBuckleDriver 3;
BA_ "GenSigStartValue" SG_ 76 FirstRowBuckleDriver 3;
BA_ "U_P702_MY2021_Rx" SG_ 76 FirstRowBuckleDriver 1;
BA_ "U_T6_MCA_MY2020_Rx" SG_ 76 FirstRowBuckleDriver 1;
BA_ "U_CX727_MY2021_Rx" SG_ 76 FirstRowBuckleDriver 1;
BA_ " _InfoCAN" SG_ 76 RILReq 1;
BA_ " _InfoCAN" SG_ 76 FirstRowBucklePsngr 1;
BA_ "GenSigStartValueInteger" SG_ 76 FirstRowBucklePsngr 3;
BA_ "GenSigStartValue" SG_ 76 FirstRowBucklePsngr 3;
BA_ "WakeupSignal" SG_ 76 RstrnImpactEvntStatus 1;
BA_ " _InfoCAN" SG_ 76 RstrnImpactEvntStatus 1;
BA_ "U_P702_MY2021_Rx" SG_ 76 RstrnImpactEvntStatus 1;
BA_ "U_T6_MCA_MY2020_Rx" SG_ 76 RstrnImpactEvntStatus 1;
BA_ "U_CX727_MY2021_Rx" SG_ 76 RstrnImpactEvntStatus 1;
BA_ " _InfoCAN" SG_ 76 PsngrFrntDetct_D_Actl 1;
BA_ "GenSigStartValueInteger" SG_ 76 PsngrFrntDetct_D_Actl 3;
BA_ "GenSigStartValue" SG_ 76 PsngrFrntDetct_D_Actl 3;
BA_ " _InfoCAN" SG_ 76 EDRTriggerEvntSync 1;
BA_ " _InfoCAN" SG_ 76 PassRstrnInd_Req 1;
BA_ "GenSigStartValueInteger" SG_ 76 PassRstrnInd_Req 3;
BA_ "GenSigStartValue" SG_ 76 PassRstrnInd_Req 3;
BA_ "FrameRouting" BO_ 65 "";
BA_ "FrameGatewayId" BO_ 65 65;
BA_ "FrameGatewayNetwork" BO_ 65 "HS1_CAN";
BA_ "VFrameFormat" BO_ 65 14;
BA_ "U_P702_MY2021_Rx" SG_ 65 immoControlData_T1 1;
BA_ "U_T6_MCA_MY2020_Rx" SG_ 65 immoControlData_T1 1;
BA_ "U_P702_MY2021_Rx" SG_ 65 immoControlCmd_T1 1;
BA_ "U_T6_MCA_MY2020_Rx" SG_ 65 immoControlCmd_T1 1;
BA_ "FrameRouting" BO_ 1076 "";
BA_ "FrameGatewayId" BO_ 1076 1076;
BA_ "FrameGatewayNetwork" BO_ 1076 "HS3_CAN";
BA_ "VFrameFormat" BO_ 1076 14;
BA_ " _InfoCAN" SG_ 1076 HILL_DESC_SW 1;
BA_ "U_P702_MY2021_Rx" SG_ 1076 HILL_DESC_SW 1;
BA_ "U_T6_MCA_MY2020_Rx" SG_ 1076 HILL_DESC_SW 1;
BA_ "U_P702_MY2021_Rx" SG_ 1076 AutoRgen_D_Rq 1;
BA_ "U_T6_MCA_MY2020_Rx" SG_ 1076 AutoRgen_D_Rq 1;
BA_ "GenSigStartValueInteger" SG_ 1076 W2S_LAMP_OK 1;
BA_ "GenSigStartValue" SG_ 1076 W2S_LAMP_OK 1;
BA_ " _InfoCAN" SG_ 1076 OdoTripRx_B_Actl 1;
BA_ "U_P702_MY2021_Rx" SG_ 1076 OdoTripRx_B_Actl 1;
BA_ "U_T6_MCA_MY2020_Rx" SG_ 1076 OdoTripRx_B_Actl 1;
BA_ " _InfoCAN" SG_ 1076 Veh_V_CompLimMx 1;
BA_ "GenSigStartValueInteger" SG_ 1076 Veh_V_CompLimMx 4095;
BA_ "GenSigStartValue" SG_ 1076 Veh_V_CompLimMx 4093;
BA_ "U_P702_MY2021_Rx" SG_ 1076 Veh_V_CompLimMx 1;
BA_ "U_T6_MCA_MY2020_Rx" SG_ 1076 Veh_V_CompLimMx 1;
BA_ " _InfoCAN" SG_ 1076 DrvSlipCtlMde_B_RqMyKey 1;
BA_ " _InfoCAN" SG_ 1076 FuelLvlWarn_D_Actl 1;
BA_ " _InfoCAN" SG_ 1076 FuelSecndActv_B_Actl 1;
BA_ " _InfoCAN" SG_ 1076 FuelLvlPssvSide_No_Raw 1;
BA_ "U_P702_MY2021_Rx" SG_ 1076 FuelLvlPssvSide_No_Raw 1;
BA_ "U_T6_MCA_MY2020_Rx" SG_ 1076 FuelLvlPssvSide_No_Raw 1;
BA_ " _InfoCAN" SG_ 1076 FUEL_SENSOR_NUM 1;
BA_ "U_P702_MY2021_Rx" SG_ 1076 FUEL_SENSOR_NUM 1;
BA_ "U_T6_MCA_MY2020_Rx" SG_ 1076 FUEL_SENSOR_NUM 1;
BA_ " _InfoCAN" SG_ 1076 FuelLvlActvSide_No_Raw 1;
BA_ "U_P702_MY2021_Rx" SG_ 1076 FuelLvlActvSide_No_Raw 1;
BA_ "U_T6_MCA_MY2020_Rx" SG_ 1076 FuelLvlActvSide_No_Raw 1;
BA_ " _InfoCAN" SG_ 1076 FuelLvl_Pc_Dsply 1;
BA_ "U_P702_MY2021_Rx" SG_ 1076 FuelLvl_Pc_Dsply 1;
BA_ "U_T6_MCA_MY2020_Rx" SG_ 1076 FuelLvl_Pc_Dsply 1;
BA_ " _InfoCAN" SG_ 1076 DISPLAY_SPEED_SCALING 1;
BA_ "U_P702_MY2021_Rx" SG_ 1076 DISPLAY_SPEED_SCALING 1;
BA_ "U_T6_MCA_MY2020_Rx" SG_ 1076 DISPLAY_SPEED_SCALING 1;
BA_ " _InfoCAN" SG_ 1076 DISPLAY_SPEED_OFFSET 1;
BA_ "U_P702_MY2021_Rx" SG_ 1076 DISPLAY_SPEED_OFFSET 1;
BA_ "U_T6_MCA_MY2020_Rx" SG_ 1076 DISPLAY_SPEED_OFFSET 1;
BA_ "FrameRouting" BO_ 862 "";
BA_ "FrameGatewayId" BO_ 862 862;
BA_ "FrameGatewayNetwork" BO_ 862 "MS1_CAN";
BA_ "VFrameFormat" BO_ 862 14;
BA_ "GenSigStartValueInteger" SG_ 862 AutoStpHvacDelta_I_Est 192;
BA_ "U_P702_MY2021_Rx" SG_ 862 HvacBlwrFront_D_Stat 1;
BA_ "U_T6_MCA_MY2020_Rx" SG_ 862 HvacBlwrFront_D_Stat 1;
BA_ "GenSigStartValueInteger" SG_ 862 CabnAmb_Te_Actl 114;
BA_ "U_P702_MY2021_Rx" SG_ 862 CabnAmb_Te_Actl 1;
BA_ "U_P702_MY2021_Rx" SG_ 862 HvacRemoteStrt_N_Rq 1;
BA_ "U_T6_MCA_MY2020_Rx" SG_ 862 HvacRemoteStrt_N_Rq 1;
BA_ "GenSigStartValueInteger" SG_ 862 ClimtThrmlLoad_No_Actl 255;
BA_ "GenSigStartValue" SG_ 862 ClimtThrmlLoad_No_Actl 255;
BA_ "U_P702_MY2021_Rx" SG_ 862 ClimtThrmlLoad_No_Actl 1;
BA_ "FrameRouting" BO_ 578 "";
BA_ "FrameGatewayId" BO_ 578 578;
BA_ "FrameGatewayNetwork" BO_ 578 "HS1_CAN";
BA_ "VFrameFormat" BO_ 578 14;
BA_ "U_P702_MY2021_Rx" SG_ 578 PtLatchActv_B_RqBcm 1;
BA_ "U_T6_MCA_MY2020_Rx" SG_ 578 PtLatchActv_B_RqBcm 1;
BA_ "U_P702_MY2021_Rx" SG_ 578 immoSecureIdleMode 1;
BA_ "U_T6_MCA_MY2020_Rx" SG_ 578 immoSecureIdleMode 1;
BA_ "WakeupSignal" SG_ 578 ReFuelSwtchStat_D_Actl 1;
BA_ "U_P702_MY2021_Rx" SG_ 578 FuelPumpPwr_D_Stat 1;
BA_ "U_T6_MCA_MY2020_Rx" SG_ 578 FuelPumpPwr_D_Stat 1;
BA_ "GenSigStartValueInteger" SG_ 578 BattULo_U_Actl 255;
BA_ "GenSigStartValue" SG_ 578 BattULo_U_Actl 255;
BA_ "U_P702_MY2021_Rx" SG_ 578 BattULo_U_Actl 1;
BA_ "U_T6_MCA_MY2020_Rx" SG_ 578 BattULo_U_Actl 1;
BA_ "U_CX727_MY2021_Rx" SG_ 578 BattULo_U_Actl 1;
BA_ " _InfoCAN" SG_ 578 PrkLckCtl_B_Enbl 1;
BA_ "WakeupSignal" SG_ 578 PrkLckCtlMsgTxt_D_Rq 1;
BA_ " _InfoCAN" SG_ 578 PrkLckCtlMsgTxt_D_Rq 1;
BA_ "WakeupSignal" SG_ 578 PrkLckCtlAvail_T_Stat 1;
BA_ " _InfoCAN" SG_ 578 PrkLckCtlAvail_T_Stat 1;
BA_ "U_P702_MY2021_Rx" SG_ 578 BrkTrnShifLck_B_Stat 1;
BA_ "U_T6_MCA_MY2020_Rx" SG_ 578 BrkTrnShifLck_B_Stat 1;
BA_ "U_P702_MY2021_Rx" SG_ 578 DriverCrankingReq 1;
BA_ "U_T6_MCA_MY2020_Rx" SG_ 578 DriverCrankingReq 1;
BA_ "U_P702_MY2021_Rx" SG_ 578 EngOff_T_Actl 1;
BA_ "U_T6_MCA_MY2020_Rx" SG_ 578 EngOff_T_Actl 1;
BA_ "U_CX727_MY2021_Rx" SG_ 578 EngOff_T_Actl 1;
BA_ "U_P702_MY2021_Rx" SG_ 578 DcacElPw_D_Rq 1;
BA_ "U_T6_MCA_MY2020_Rx" SG_ 578 DcacElPw_D_Rq 1;
BA_ "GenSigStartValueInteger" SG_ 578 BattULo_I_Actl 16383;
BA_ "GenSigStartValue" SG_ 578 BattULo_I_Actl 16383;
BA_ "U_P702_MY2021_Rx" SG_ 578 BattULo_I_Actl 1;
BA_ "U_T6_MCA_MY2020_Rx" SG_ 578 BattULo_I_Actl 1;
BA_ "FrameRouting" BO_ 1084 "";
BA_ "FrameGatewayId" BO_ 1084 1084;
BA_ "FrameGatewayNetwork" BO_ 1084 "HS1_CAN";
BA_ "VFrameFormat" BO_ 1084 14;
BA_ "GenSigStartValueInteger" SG_ 1084 BattULoChrg_URate_RqMx 5;
BA_ "GenSigStartValue" SG_ 1084 BattULoChrg_URate_RqMx 5;
BA_ "U_P702_MY2021_Rx" SG_ 1084 BattULoChrg_URate_RqMx 1;
BA_ "U_T6_MCA_MY2020_Rx" SG_ 1084 BattULoChrg_URate_RqMx 1;
BA_ "GenSigStartValueInteger" SG_ 1084 BattULoChrg_U_RqMx 34;
BA_ "GenSigStartValue" SG_ 1084 BattULoChrg_U_RqMx 34;
BA_ "U_P702_MY2021_Rx" SG_ 1084 BattULoChrg_U_RqMx 1;
BA_ "U_T6_MCA_MY2020_Rx" SG_ 1084 BattULoChrg_U_RqMx 1;
BA_ "U_P702_MY2021_Rx" SG_ 1084 BattULoChrg_U_RqMn 1;
BA_ "U_T6_MCA_MY2020_Rx" SG_ 1084 BattULoChrg_U_RqMn 1;
BA_ "U_P702_MY2021_Rx" SG_ 1084 BattULoState_D_Qlty 1;
BA_ "U_T6_MCA_MY2020_Rx" SG_ 1084 BattULoState_D_Qlty 1;
BA_ "U_P702_MY2021_Rx" SG_ 1084 BSFault 1;
BA_ "U_T6_MCA_MY2020_Rx" SG_ 1084 BSFault 1;
BA_ "GenSigStartValueInteger" SG_ 1084 BattULo2_Te_Actl 127;
BA_ "GenSigStartValue" SG_ 1084 BattULo2_Te_Actl 127;
BA_ "U_P702_MY2021_Rx" SG_ 1084 BattULo2_Te_Actl 1;
BA_ "U_T6_MCA_MY2020_Rx" SG_ 1084 BattULo2_Te_Actl 1;
BA_ "U_P702_MY2021_Rx" SG_ 1084 BSBattSOC 1;
BA_ "U_T6_MCA_MY2020_Rx" SG_ 1084 BSBattSOC 1;
BA_ "GenSigStartValueInteger" SG_ 1084 BSBattQDeltaRideAh 12800;
BA_ "U_P702_MY2021_Rx" SG_ 1084 BSBattQDeltaRideAh 1;
BA_ "U_T6_MCA_MY2020_Rx" SG_ 1084 BSBattQDeltaRideAh 1;
BA_ "U_P702_MY2021_Rx" SG_ 1084 BSBattQCapAh 1;
BA_ "U_T6_MCA_MY2020_Rx" SG_ 1084 BSBattQCapAh 1;
BA_ "FrameRouting" BO_ 1068 "";
BA_ "FrameGatewayId" BO_ 1068 1068;
BA_ "FrameGatewayNetwork" BO_ 1068 "HS1_CAN";
BA_ "VFrameFormat" BO_ 1068 14;
BA_ "U_P702_MY2021_Rx" SG_ 1068 EngStrtInhbt_B_RqBatt 1;
BA_ "U_T6_MCA_MY2020_Rx" SG_ 1068 EngStrtInhbt_B_RqBatt 1;
BA_ "U_P702_MY2021_Rx" SG_ 1068 BattULoChrg_D_Rq 1;
BA_ "U_T6_MCA_MY2020_Rx" SG_ 1068 BattULoChrg_D_Rq 1;
BA_ "WakeupSignal" SG_ 1068 PwSysULoFalt_D_Stat 1;
BA_ " _InfoCAN" SG_ 1068 PwSysULoFalt_D_Stat 1;
BA_ " _InfoCAN" SG_ 1068 Shed_T_Eng_Off_B 1;
BA_ "WakeupSignal" SG_ 1068 Shed_Feature_Group_ID 1;
BA_ "U_P702_MY2021_Rx" SG_ 1068 Shed_Feature_Group_ID 1;
BA_ "U_T6_MCA_MY2020_Rx" SG_ 1068 Shed_Feature_Group_ID 1;
BA_ " _InfoCAN" SG_ 1068 Shed_Drain_Eng_Off_B 1;
BA_ "WakeupSignal" SG_ 1068 Shed_Level_Req 1;
BA_ " _InfoCAN" SG_ 1068 Shed_Level_Req 1;
BA_ "U_P702_MY2021_Rx" SG_ 1068 Shed_Level_Req 1;
BA_ "U_T6_MCA_MY2020_Rx" SG_ 1068 Shed_Level_Req 1;
BA_ "U_P702_MY2021_Rx" SG_ 1068 ULoRgenTestMde_B_Rq 1;
BA_ "U_T6_MCA_MY2020_Rx" SG_ 1068 ULoRgenTestMde_B_Rq 1;
BA_ "U_P702_MY2021_Rx" SG_ 1068 ChargeMode 1;
BA_ "U_T6_MCA_MY2020_Rx" SG_ 1068 ChargeMode 1;
BA_ " _InfoCAN" SG_ 1068 Batt_Lo_SoC_B 1;
BA_ "U_P702_MY2021_Rx" SG_ 1068 PeriodicElLoad_B_Stat 1;
BA_ "U_T6_MCA_MY2020_Rx" SG_ 1068 PeriodicElLoad_B_Stat 1;
BA_ " _InfoCAN" SG_ 1068 Batt_Crit_SoC_B 1;
BA_ "FrameRouting" BO_ 146 "";
BA_ "FrameGatewayId" BO_ 146 146;
BA_ "FrameGatewayNetwork" BO_ 146 "HS2_CAN";
BA_ "VFrameFormat" BO_ 146 14;
BA_ "GenSigStartValueInteger" SG_ 146 VehVert2_A_Actl 8190;
BA_ "GenSigStartValue" SG_ 146 VehVert2_A_Actl 8190;
BA_ "U_P702_MY2021_Rx" SG_ 146 VehVert2_A_Actl 1;
BA_ "U_T6_MCA_MY2020_Rx" SG_ 146 VehVert2_A_Actl 1;
BA_ "U_CX727_MY2021_Rx" SG_ 146 VehVert2_A_Actl 1;
BA_ "MetaData" SG_ 146 VehLatLongVertA_No_Cs 1;
BA_ "U_CX727_MY2021_Rx" SG_ 146 VehLatLongVertA_No_Cs 1;
BA_ "U_P702_MY2021_Rx" SG_ 146 VehLatLongVertA_No_Cs 1;
BA_ "MetaData" SG_ 146 VehLatLongVert_No_Cnt 1;
BA_ "U_CX727_MY2021_Rx" SG_ 146 VehLatLongVert_No_Cnt 1;
BA_ "U_P702_MY2021_Rx" SG_ 146 VehLatLongVert_No_Cnt 1;
BA_ "GenSigStartValueInteger" SG_ 146 VehLong2_A_Actl 8190;
BA_ "GenSigStartValue" SG_ 146 VehLong2_A_Actl 8190;
BA_ "U_P702_MY2021_Rx" SG_ 146 VehLong2_A_Actl 1;
BA_ "U_T6_MCA_MY2020_Rx" SG_ 146 VehLong2_A_Actl 1;
BA_ "U_CX727_MY2021_Rx" SG_ 146 VehLong2_A_Actl 1;
BA_ "GenSigStartValueInteger" SG_ 146 VehLat2_A_Actl 8190;
BA_ "GenSigStartValue" SG_ 146 VehLat2_A_Actl 8190;
BA_ "U_P702_MY2021_Rx" SG_ 146 VehLat2_A_Actl 1;
BA_ "U_T6_MCA_MY2020_Rx" SG_ 146 VehLat2_A_Actl 1;
BA_ "U_CX727_MY2021_Rx" SG_ 146 VehLat2_A_Actl 1;
BA_ "GenSigStartValueInteger" SG_ 146 VehVertAActl_D_Qf 1;
BA_ "MetaData" SG_ 146 VehVertAActl_D_Qf 1;
BA_ "GenSigStartValue" SG_ 146 VehVertAActl_D_Qf 1;
BA_ "U_CX727_MY2021_Rx" SG_ 146 VehVertAActl_D_Qf 1;
BA_ "U_P702_MY2021_Rx" SG_ 146 VehVertAActl_D_Qf 1;
BA_ "GenSigStartValueInteger" SG_ 146 VehLongAActl_D_Qf 1;
BA_ "MetaData" SG_ 146 VehLongAActl_D_Qf 1;
BA_ "GenSigStartValue" SG_ 146 VehLongAActl_D_Qf 1;
BA_ "U_P702_MY2021_Rx" SG_ 146 VehLongAActl_D_Qf 1;
BA_ "U_T6_MCA_MY2020_Rx" SG_ 146 VehLongAActl_D_Qf 1;
BA_ "U_CX727_MY2021_Rx" SG_ 146 VehLongAActl_D_Qf 1;
BA_ "GenSigStartValueInteger" SG_ 146 VehLatAActl_D_Qf 1;
BA_ "MetaData" SG_ 146 VehLatAActl_D_Qf 1;
BA_ "GenSigStartValue" SG_ 146 VehLatAActl_D_Qf 1;
BA_ "U_CX727_MY2021_Rx" SG_ 146 VehLatAActl_D_Qf 1;
BA_ "U_P702_MY2021_Rx" SG_ 146 VehLatAActl_D_Qf 1;
BA_ "FrameRouting" BO_ 997 "";
BA_ "GenMsgSendType" BO_ 997 5;
BA_ "GenMsgCycleTime" BO_ 997 1000;
BA_ "VFrameFormat" BO_ 997 14;
BA_ " _InfoCAN" SG_ 997 PersIndexCcm_D_Actl 1;
BA_ "GenSigStartValueInteger" SG_ 997 PersIndexCcm_D_Actl 4;
BA_ "GenSigStartValue" SG_ 997 PersIndexCcm_D_Actl 4;
BA_ "GenSigSendType" SG_ 997 PersIndexCcm_D_Actl 3;
BA_ " _InfoCAN" SG_ 997 FeatNoCcmActl 1;
BA_ "GenSigSendType" SG_ 997 FeatNoCcmActl 3;
BA_ " _InfoCAN" SG_ 997 FeatConfigCcmActl 1;
BA_ "GenSigSendType" SG_ 997 FeatConfigCcmActl 3;
VAL_ 1046 HsaMde_D_Mem 3 "Undefined" 2 "Manual" 1 "Automatic" 0 "Off" ;
VAL_ 1046 BrkBstrVac_B_Rq 1 "Yes" 0 "No" ;
VAL_ 1046 HdcMde_D_Actl 7 "Fault" 6 "Temporarily_Unavailable" 5 "NotEnabled_WrongGearSel" 4 "NotEnabled_SpdLimitExceed" 3 "Active_Braking" 2 "Not_Active_Braking" 1 "Off" 0 "Undefined" ;
VAL_ 1046 RearDiffLck_Tq2_RqMx 4095 "Faulty" ;
VAL_ 1046 TRLR_SWAY_EVNT_IN_PROG 1 "Yes" 0 "No" ;
VAL_ 1046 TRLR_SWAY_CONFIG_STAT 1 "On" 0 "Off" ;
VAL_ 1046 TCMode 1 "Active" 0 "Inactive" ;
VAL_ 1046 DrvSlipCtlLamp_D_Rq 3 "Fast_Flash" 2 "Slow_Flash" 1 "On" 0 "Off" ;
VAL_ 1046 Abs_B_Falt 1 "Yes" 0 "No" ;
VAL_ 1046 DrvSlipCtlMde_D_Ind 3 "App_Specific_Off_Mode_3" 2 "App_Specific_Off_Mode_2" 1 "App_Specific_Off_Mode_1" 0 "Default_Mode" ;
VAL_ 1046 DrvAntiLckLamp_D_Rq 3 "Fast_Flash" 2 "Slow_Flash" 1 "On" 0 "Off" ;
VAL_ 1046 StabCtlBrk_B_Avail 1 "Yes" 0 "No" ;
VAL_ 1046 DrvHdcWarnInfo_D_Rq 3 "Undefined" 2 "Lamp_On_Continuously" 1 "Lamp_Flashing" 0 "Lamp_Off_Continuously" ;
VAL_ 1046 DrvHdcMsg_D_Rq 7 "Undefined" 6 "Speed_too_High" 5 "Temporarily_Unavailable" 4 "System_Fault" 3 "Select_Gear" 2 "Off" 1 "On" 0 "No_Message" ;
VAL_ 1046 DrvHdcLampInfo_D_Rq 3 "Fast_Flash" 2 "Slow_Flash" 1 "On" 0 "Off" ;
VAL_ 1046 BpedMove_D_Actl 3 "Unknown" 2 "DriverApplyingBrakePedal" 1 "NoAutonomousBrkPdlMovement" 0 "AutonomousBrkPedalMove" ;
VAL_ 1046 ChimeBrk_B_Rq 1 "Yes" 0 "No" ;
VAL_ 1046 BrkLamp_B_Rq 1 "Yes" 0 "No" ;
VAL_ 1046 HILL_DESC_MC 7 "Fault_Detected" 6 "Cooling_Down" 5 "Abort_Apply_Brakes" 4 "Active" 3 "Disabled" 2 "Enabled" 1 "Off_Road" 0 "Normal" ;
VAL_ 1046 RearDiffElckrOpen_B_Rq 1 "Yes" 0 "No" ;
VAL_ 1045 VehStab_D_Stat 15 "Faulty" 14 "No_Data_Exists" 13 "NotUsed6" 12 "NotUsed5" 11 "NotUsed4" 10 "NotUsed3" 9 "NotUsed2" 8 "NotUsed1" 7 "High_SSRA_no_OS" 6 "Straight" 5 "Post_Oversteer" 4 "Post_Transition" 3 "Countersteer" 2 "Understeer" 1 "Oversteer" 0 "Linear" ;
VAL_ 1045 BrkFluidLvl_D_Stat 3 "Invalid" 2 "Unknown" 1 "Low" 0 "OK" ;
VAL_ 1045 LsmcBrkDecel_D_Stat 7 "NotUsed_3" 6 "NotUsed_2" 5 "NotUsed_1" 4 "Denied" 3 "FaultDegraded" 2 "FaultExt" 1 "On" 0 "Off" ;
VAL_ 1045 VehYawNonLin_W_Rq 4095 "Fault" 4094 "Unknown" ;
VAL_ 1045 VehYawLin_W_Rq 4095 "Fault" 4094 "Unknown" ;
VAL_ 1045 VehVActlBrk_D_Qf 3 "OK" 2 "Not_Within_Specifications" 1 "No_Data_Exists" 0 "Faulty" ;
VAL_ 535 WhlRr_W_Meas 32767 "Fault" 32766 "Unknown" ;
VAL_ 535 WhlRl_W_Meas 32767 "Fault" 32766 "Unknown" ;
VAL_ 535 WhlFr_W_Meas 32767 "Fault" 32766 "Unknown" ;
VAL_ 535 WhlFl_W_Meas 32767 "Fault" 32766 "Unknown" ;
VAL_ 534 WhlDirRr_D_Actl 3 "Faulty" 2 "NoDataExists" 1 "Backward" 0 "Forward" ;
VAL_ 534 WhlDirRl_D_Actl 3 "Faulty" 2 "NoDataExists" 1 "Backward" 0 "Forward" ;
VAL_ 534 WhlDirFr_D_Actl 3 "Faulty" 2 "NoDataExists" 1 "Backward" 0 "Forward" ;
VAL_ 534 WhlDirFl_D_Actl 3 "Faulty" 2 "NoDataExists" 1 "Backward" 0 "Forward" ;
VAL_ 531 VehStop_D_Stat 3 "Faulty" 2 "NoDataExists" 1 "Yes" 0 "No" ;
VAL_ 531 TracCtlPtActv_B_Actl 1 "Active" 0 "Inactive" ;
VAL_ 531 LscmbbMntr_B_Err 1 "DisplayMessage" 0 "NoMessage" ;
VAL_ 531 LscmbbBrkDis_B_Actl 1 "Yes" 0 "No" ;
VAL_ 531 LscmbbDeny_B_ActlBrk 1 "Yes" 0 "No" ;
VAL_ 531 PrkBrkYwLamp_D_Rq 3 "Fast_Flash" 2 "Slow_Flash" 1 "On" 0 "Off" ;
VAL_ 531 PrkBrkRedLamp_D_Rq 3 "Fast_Flash" 2 "Slow_Flash" 1 "On" 0 "Off" ;
VAL_ 531 LscmbbBrkDecel_B_Actl 1 "Yes" 0 "No" ;
VAL_ 531 AbsActv_B_Actl 1 "Yes" 0 "No" ;
VAL_ 531 StabCtlBrkActv_B_Actl 1 "Yes" 0 "No" ;
VAL_ 531 CmbbBrkPrchg_B_Actl 1 "Yes" 0 "No" ;
VAL_ 531 CmbbBrkDecel_B_Actl 1 "Yes" 0 "No" ;
VAL_ 531 CmbbBaSensInc_B_Actl 1 "Yes" 0 "No" ;
VAL_ 531 AccBrkWarm_B_Actl 1 "Yes" 0 "No" ;
VAL_ 531 AccBrkTotTqMn_B_Actl 1 "Yes" 0 "No" ;
VAL_ 531 AccBrkPrchgActv_B_Actl 1 "Yes" 0 "No" ;
VAL_ 531 AccBrkDis_B_Actl 1 "Yes" 0 "No" ;
VAL_ 531 AccBrkDeny_B_Actl 1 "Yes" 0 "No" ;
VAL_ 531 AccBrkActv_B_Actl 1 "Yes" 0 "No" ;
VAL_ 531 PrplDrgCtlActv_B_Actl 1 "Active" 0 "Inactive" ;
VAL_ 531 LscmbbBaSensInc_B_Actl 1 "Yes" 0 "No" ;
VAL_ 531 CmbbBrkDis_B_Actl 1 "Yes" 0 "No" ;
VAL_ 531 CmbbDeny_B_ActlBrk 1 "Yes" 0 "No" ;
VAL_ 531 CcDis_B_Cmd 1 "Yes" 0 "No" ;
VAL_ 531 VehLongOvrGnd_A_Est 1023 "Fault" 1022 "Unknown" ;
VAL_ 531 LscmbBrkPrchg_B_Actl 1 "Active" 0 "Inactive" ;
VAL_ 531 AccStopActv_B_ActlBrk 1 "Yes" 0 "No" ;
VAL_ 531 AccDis_B_ActlEpb 1 "Yes" 0 "No" ;
VAL_ 531 PrkBrkMsgTxt_D_Rq 15 "Message15" 14 "Message14" 13 "Message13" 12 "Message12" 11 "Message11" 10 "Message10" 9 "Message9" 8 "Message8" 7 "Message7" 6 "Message6" 5 "Message5" 4 "Message4" 3 "Message3" 2 "Message2" 1 "Message1" 0 "No_Message" ;
VAL_ 531 PrkBrkStatus 7 "GeneralFault_MaintenceMode" 6 "ECD_by_Brake_ECU_Active" 5 "EPB_Limphome_Active" 4 "Rear_Caliper_Open" 3 "RWU_By_EPB_Active" 2 "Rear_Caliper_Transition" 1 "Rear_Caliper_Closed" 0 "Not_Supported" ;
VAL_ 125 VehRolComp_W_Actl 4094 "NoDataExists" 4095 "Fault" ;
VAL_ 125 VehVertComp_A_Actl 1022 "NoDataExists" 1023 "Fault" ;
VAL_ 125 BrkTot_Tq_RqArb 8191 "Fault" 8190 "Unknown" ;
VAL_ 125 BrkTot_Tq_Actl 8191 "Fault" 8190 "Unknown" ;
VAL_ 125 HsaStat_D_Actl 7 "Faulty" 6 "FaultyWithDriverIndication" 5 "SlowRelease" 4 "FastRelease" 3 "ActiveBrakePedalReleased" 2 "ActiveBrakePedalPressed" 1 "FindingGradient" 0 "Inactive" ;
VAL_ 119 VehTrvlDir_D_Stat 7 "Faulty" 6 "NoDataExists" 5 "NotUsed2" 4 "NotUsed1" 3 "Reverse" 2 "LikelyReverse" 1 "Forward" 0 "LikelyForward" ;
VAL_ 119 VehOverGnd_V_Est 65535 "Invalid" 65534 "Unknown" ;
VAL_ 119 VehLongComp_A_Actl 1023 "Fault" 1022 "NoDataExists" ;
VAL_ 119 VehLatComp_A_Actl 1023 "Fault" 1022 "NoDataExists" ;
VAL_ 119 VehYawComp_W_Actl 4095 "Fault" 4094 "NoDataExists" ;
VAL_ 118 BrkCtrFnd_B_Stat 1 "Yes" 0 "No" ;
VAL_ 118 DrvSte_D_Stat 15 "NotUsed10" 14 "NotUsed9" 13 "NotUsed8" 12 "NotUsed7" 11 "NotUsed6" 10 "NotUsed5" 9 "NotUsed4" 8 "NotUsed3" 7 "NotUsed2" 6 "NotUsed1" 5 "Request_Active" 4 "Ignition_Off" 3 "DSR_in_Normal_Idle_Mode" 2 "EPAS_Comm_Disturbed" 1 "DSR_Request_Not_Applicable" 0 "DSR_Deactivated" ;
VAL_ 118 DrvSte_Tq_Rq 255 "Invalid" 254 "Unknown" ;
VAL_ 118 EmgcyBrkLamp_D_Rq 3 "NotUsed" 2 "Active_at_standstill" 1 "Active_at_speed" 0 "Inactive" ;
VAL_ 118 StopLamp_B_RqBrk 1 "Active" 0 "Inactive" ;
VAL_ 560 SelDrvMdeSwtch_D_Stat3 3 "Faulty" 2 "SwitchState2" 1 "SwitchState1" 0 "NotPressed" ;
VAL_ 560 TrnSrvcRqd_B_Rq 1 "On" 0 "Off" ;
VAL_ 560 TrnShifActv_B_Actl 1 "Active" 0 "Inactive" ;
VAL_ 560 GearLvrPos_D_Actl 15 "Fault" 14 "Unknown_Position" 13 "Undefined_Treat_as__Fault" 12 "Undefined_Treat_as_Fault" 11 "sixth" 10 "fifth" 9 "fourth" 8 "third" 7 "second" 6 "first" 5 "Low" 4 "Sport_DriveSport" 3 "Drive" 2 "Neutral" 1 "Reverse" 0 "Park" ;
VAL_ 560 GboxOil_Te_Actl 255 "Faulty" 254 "NoDataExists" ;
VAL_ 369 SeatWorkSrfc_B_Falt 1 "Active" 0 "Inactive" ;
VAL_ 369 TrnIpcDsplyRng2_D_Actl 15 "No_Range_Selected" 14 "Range_14" 13 "Range_13" 12 "Range_12" 11 "Range_11" 10 "Range_10" 9 "Range_9" 8 "Range_8" 7 "Range_7" 6 "Range_6" 5 "Range_5" 4 "Range_4" 3 "Range_3" 2 "Range_2" 1 "Range_1" 0 "NotUsed" ;
VAL_ 369 TrnIpcDsplyRng_D_Stat 3 "NotUsed" 2 "Flash" 1 "On" 0 "Blank_No_Display" ;
VAL_ 369 TrnIpcDsplyGear_D_Actl 15 "No_Gear_Selected" 14 "_14th_Gear" 13 "_13th_Gear" 12 "_12th_Gear" 11 "_11th_Gear" 10 "_10th_Gear" 9 "_9th_Gear" 8 "_8th_Gear" 7 "_7th_Gear" 6 "_6th_Gear" 5 "_5th_Gear" 4 "_4th_Gear" 3 "_3rd_Gear" 2 "_2nd_Gear" 1 "_1st_Gear" 0 "Neutral" ;
VAL_ 369 TrnIpcDsplyMde_D_Stat 3 "Reserved_Blank_No_Display" 2 "Flash" 1 "On" 0 "Blank_No_Display" ;
VAL_ 369 TrnIpcDsplyMde_D_Actl 7 "Manual_3" 6 "Manual_2" 5 "Manual_1_Low" 4 "Sport" 3 "Drive" 2 "Neutral" 1 "Reverse" 0 "Park" ;
VAL_ 369 TrnIpcDsplyGear_D_Stat 3 "Reserved_Blank_No_Display" 2 "Flash" 1 "On" 0 "Blank_No_Display" ;
VAL_ 1086 FuelPumpPwr_B_Rq 1 "On" 0 "Off" ;
VAL_ 1086 ElLoadCtl_D_Rq 7 "Unused3" 6 "Unused2" 5 "Unused1" 4 "HoldAllDrvrInvisibleLoads" 3 "StdDriverInvisibleLoadsOn" 2 "AllDriverInvisibleLoadsOn" 1 "All_Possible_Loads_Off" 0 "No_Request" ;
VAL_ 1071 CluPdlPosPcMeas_D_Qf 3 "OK" 2 "Not_Within_Specifications" 1 "No_Data_Exists" 0 "Faulty" ;
VAL_ 1069 SlMde_D_Stat 3 "IsaNotConfigured" 2 "Manual_Mode" 1 "Auto_Mode" 0 "Null" ;
VAL_ 1069 SlMde_D_RqDsply 3 "NotUsed" 2 "ManualSpeed_LimiterSymbol" 1 "AutoSpeed_LimiterSymbol" 0 "NoSpeed_LimiterSymbol" ;
VAL_ 1069 IsaOffst_D_Stat 15 "Faulty" 14 "Null" 13 "Thirteen" 12 "Twelve" 11 "Eleven" 10 "Ten" 9 "Nine" 8 "Eight" 7 "Seven" 6 "Six" 5 "Five" 4 "Four" 3 "Three" 2 "Two" 1 "One" 0 "Zero" ;
VAL_ 1069 GrllShtrPos_D_Cmd 15 "Fully_Open" 14 "Position14" 13 "Position13" 12 "Position12" 11 "Position11" 10 "Position10" 9 "Position9" 8 "Position8" 7 "Position7" 6 "Position6" 5 "Position5" 4 "Position4" 3 "Position3" 2 "Position2" 1 "Position1" 0 "Fully_Closed" ;
VAL_ 1069 GrllShtrPos_B_Falt 1 "Fault" 0 "No_Fault" ;
VAL_ 1069 ObdWarmUp_B_Complt 1 "Yes" 0 "No" ;
VAL_ 1069 EngMsgTxt_D_Rq 3 "Undefined_2" 2 "Undefined_1" 1 "Power_Reduced_to_LowerTemp" 0 "No_Message" ;
VAL_ 1069 EngAirIn_Te_Actl 1023 "Fault" 1022 "Unknown" ;
VAL_ 1060 RearDiffOilTeWarn_B_Rq 1 "On" 0 "Off" ;
VAL_ 1060 RearDiffOil_Te_Actl 511 "Faulty" ;
VAL_ 1060 BpedDrvMsgTxt_B_Dsply 1 "On" 0 "Off" ;
VAL_ 1060 FuelLvlWarn_D_ActlEng 7 "DteLevel5Lowest" 6 "DteLevel4" 5 "DteLevel3" 4 "DteLevel2NonMyKey" 3 "DteLevel1MyKey" 2 "VeryLow" 1 "Low" 0 "OK" ;
VAL_ 1060 SelDrvMdePt_D_Stat 0 "NotAvailable" 1 "Available" 2 "TemporarilyNotAvailable" 3 "Faulty" ;
VAL_ 1057 FohEng_D_Rq 3 "AutoEnable_ParkEnable" 2 "AutoDisable_ParkEnable" 1 "AutoEnable_ParkDisable" 0 "Disable_Stop" ;
VAL_ 1057 EngIdlShutDwnTxt_D_Rq 3 "NotUsed" 2 "EngineShutdownOnPrevDrive" 1 "FeatureDisabledDueToFault" 0 "NoMessage" ;
VAL_ 1057 EngIdlShutDown_D_Stat 3 "Not_used" 2 "Engine_Shutdown" 1 "Initiated_Countdown" 0 "Normal_Operation" ;
VAL_ 1057 FUEL_ALCOHOL_PERCNT 255 "Invalid" ;
VAL_ 1057 TrnTotTq_Rt_Est 65535 "Fault" 65534 "Unknown" ;
VAL_ 1057 TrnTotLss_Tq_Est 255 "Fault" 254 "Unknown" ;
VAL_ 1057 ECMMILRequest 3 "Not_Used" 2 "Flash" 1 "On" 0 "Off" ;
VAL_ 1057 AirCondFluidHi_P_Actl 255 "Fault" 254 "Unknown" ;
VAL_ 1057 OilPressureWarning 1 "Low_Pressure_Lamp_On" 0 "Normal_Pressure_Lamp_Off" ;
VAL_ 1057 VehVLimStat_D_Actl 7 "Undefined_3" 6 "Undefined_2" 5 "Undefined_1" 4 "ASL_Fault_Condition" 3 "Active_and_Limiting" 2 "Active_but_Not_Limiting" 1 "Standby" 0 "Off" ;
VAL_ 1057 VehVLimActv_B_Actl 1 "Active" 0 "Inactive" ;
VAL_ 1057 CoolantFanStepAct 31 "Unused7" 30 "Unused6" 29 "Unused5" 28 "Unused4" 27 "Unused3" 26 "Unused2" 25 "Unused1" 23 "Step23" 22 "Step22" 21 "Step21" 20 "Step20" 19 "Step19" 18 "Step18" 17 "Step17" 16 "Step16" 15 "Step15" 14 "Step14" 13 "Step13" 12 "Step12" 11 "Step11" 10 "Step10" 9 "Step9" 8 "Step8" 7 "Step7" 6 "Step6" 5 "Step5" 4 "Step4" 3 "Step3" 2 "Step2" 1 "Step1" 24 "Max_Fan_Speed_Req" 0 "Fan_Cmd_Off" ;
VAL_ 516 EngAoutNActl_D_QF 3 "OK" 2 "Not_Within_Specifications" 1 "No_Data_Exists" 0 "Faulty" ;
VAL_ 516 EngAout3_N_Actl 65535 "Invalid" ;
VAL_ 516 ApedPos_PcRate_ActlArb 255 "Fault" 254 "Unknown" ;
VAL_ 516 ApedPosPcActl_D_Qf 3 "OK" 2 "Not_Within_Specifications" 1 "No_Data_Exists" 0 "Faulty" ;
VAL_ 514 StrtrMtrDlyStrt_B_Stat 1 "Yes" 0 "No" ;
VAL_ 514 VehVTrlrAid_B_Avail 1 "Yes" 0 "No" ;
VAL_ 514 StrtrMtrCtlMsgTxt_D_Rq 7 "Start_In_Gear_Allowed" 6 "Pending_Start_Cancelled" 5 "Start_Pending_Please_Wait" 4 "Cranking_Limit_Exceeded" 3 "Press_Brk_and_Shift_to_P_N" 2 "Press_Clutch_and_Brake" 1 "Press_Clutch_To_Start" 0 "No_Display" ;
VAL_ 514 VehVActlEng_D_Qf 3 "OK" 2 "Not_Within_Specifications" 1 "No_Data_Exists" 0 "Faulty" ;
VAL_ 514 GearRvrse_D_Actl 7 "Fault" 6 "NotUsed_3" 5 "NotUsed_2" 4 "NotUsed_1" 3 "Active_confirmed" 2 "Active_not_confirmed" 1 "Inactive_confirmed" 0 "Inactive_not_confirmed" ;
VAL_ 514 StrtrMtrCtlMsgTxt_D2_Rq 3 "NoRequestPcmStartingMsgCtl" 2 "ShiftToNeutralToStart" 1 "ShiftToParkToStart" 0 "NoRequestBcmStartingMsgCtl" ;
VAL_ 512 PtDrvMde_D_Stat 15 "Faulty" 14 "NotUsed11" 13 "NotUsed10" 12 "NotUsed9" 11 "NotUsed8" 10 "NotUsed7" 9 "NotUsed6" 8 "NotUsed5" 7 "Drag" 6 "Rock" 5 "Baja" 4 "Sand" 3 "TowHaulGradeAssist" 2 "SnowWet" 1 "Sport" 0 "Normal" ;
VAL_ 377 HvacAirFullOut_B_Rq 1 "Yes" 0 "No" ;
VAL_ 377 FuelFillInlet_B_Dsply 1 "Yes" 0 "No" ;
VAL_ 377 EngSrvcRqd_B_Rq 1 "Engine_Service_Required" 0 "No_engine_service_required" ;
VAL_ 377 OdoCount 255 "Invalid" ;
VAL_ 377 FuelFilterLamp_B_Dsply 1 "On" 0 "Off" ;
VAL_ 377 AirCondRec_B_Rq 1 "Yes" 0 "No" ;
VAL_ 377 AirCondClutch_B_Stats 1 "Yes" 0 "No" ;
VAL_ 376 GasPrtc_D_RqDsply 7 "NotUsed_5" 6 "NotUsed_4" 5 "NotUsed_3" 4 "NotUsed_2" 3 "NotUsed_1" 2 "GpfOverLimit" 1 "GpfAtLimit" 0 "NormalOperation" ;
VAL_ 376 DynoMde_B_Cmd 1 "Two_Wheel_Dyno" 0 "Normal_Operation" ;
VAL_ 376 AslIconDsply_D_Rq 3 "On_Passive_Overridden" 2 "On_Active" 1 "On_Passive" 0 "Off" ;
VAL_ 376 AslChime_B_Rq 1 "Yes" 0 "No" ;
VAL_ 376 HvacHtrCore2_Te_Actl 1023 "Faulty" ;
VAL_ 376 EcssLamp_D_RqDsply 3 "Not_Used" 2 "Flash" 1 "On" 0 "Off" ;
VAL_ 376 AirAmbTe_D_Qf 3 "OK" 2 "Not_Within_Specifications" 1 "No_Data_Exists" 0 "Faulty" ;
VAL_ 376 AirAmb_P_Actl 63 "Fault" 62 "NoDataExists" ;
VAL_ 359 PrplWhlRgenMn_Tq_Actl 8191 "Faulty" ;
VAL_ 359 ElPw_D_StatStrtStop 15 "NotUsed6" 14 "NotUsed5" 13 "NotUsed4" 12 "NotUsed3" 11 "NotUsed2" 10 "NotUsed1" 9 "Supported_Level_4" 8 "Supported_Level_3" 7 "Supported_Level_2" 6 "Supported_Level_1" 5 "Limited_Support" 4 "Fault_Limited" 3 "LV_Event_in_Progress" 2 "Not_Supported_Imminent" 1 "Supported_All" 0 "Not_Supported" ;
VAL_ 359 PrplWhlTot2_Tq_Actl 65535 "Fault" 65534 "NoDataExists" ;
VAL_ 359 PwPckTq_D_Stat 3 "PwPckOn_TqAvailable" 2 "StartInPrgrss_TqNotAvail" 1 "PwPckOn_TqNotAvailable" 0 "PwPckOff_TqNotAvailable" ;
VAL_ 359 Eng_D_Stat 3 "NotUsed" 2 "EngAutoStopped" 1 "EngOn" 0 "EngOff" ;
VAL_ 359 PlgActvArb_B_Actl 1 "On" 0 "Off" ;
VAL_ 359 ElPw_D_Stat 7 "NotUsed_3" 6 "NotUsed_2" 5 "NotUsed_1" 4 "Fault_Limited" 3 "LV_Event_In_Progress" 2 "Not_Supported_Imminent" 1 "Supported" 0 "Not_Supported" ;
VAL_ 359 TrnAinTq_D_Qf 3 "OK" 2 "Not_Within_Specifications" 1 "No_Data_Exists" 0 "Faulty" ;
VAL_ 358 StopStrtStdby_D_Indic 6 "NotUsed2" 5 "Telltale_Struck_Out" 4 "Telltale_Flashing_Amber" 3 "Telltale_On_Amber" 2 "Telltale_Flashing_Green" 1 "Telltale_On_Green" 0 "Telltale_Off" 7 "NotUsed3" ;
VAL_ 358 StopStrtIODTxt_D_Rq 31 "Message31" 30 "Message30" 29 "Message29" 28 "Message28" 27 "Message27" 26 "Message26" 25 "Message25" 24 "Message24" 23 "Message23" 22 "Message22" 21 "Message21" 20 "Message20" 19 "Message19" 18 "Message18" 17 "Message17" 16 "Message16" 15 "Message15" 14 "Message14" 13 "Message13" 12 "Message12" 11 "Message11" 10 "Message10" 9 "Message9" 8 "Message8" 7 "Message7" 6 "Message6" 5 "Message5" 4 "Message4" 3 "Message3" 2 "Message2" 1 "Message1" 0 "NoMessage" ;
VAL_ 358 StopStrtDrvMde_D_Indic 3 "NotUsed" 2 "StartStop_IndirectDeselect" 1 "StopStart_Deselected" 0 "StopStart_Selected" ;
VAL_ 358 StopStrtMsgTxt_D_Rq 15 "Message_15" 14 "Message_14" 13 "Message_13" 12 "Message_12" 11 "Message_11" 10 "Message_10" 9 "Message_9" 8 "Message_8" 7 "Message_7" 6 "Message_6" 5 "Message_5" 4 "Message_4" 3 "Message_3" 2 "Message_2" 1 "Message_1" 0 "NoMessage" ;
VAL_ 358 OdoTripVerify_L_Actl 16777215 "Fault" ;
VAL_ 358 HiElPwInhbt_B_Stat 1 "Inhibit" 0 "No_Inibit" ;
VAL_ 358 AutoStopPtDelta_I_Est 255 "Fault" ;
VAL_ 357 BPedDrvAppl_D_QF 3 "OK" 2 "Not_Within_Specifications" 1 "No_Data_Exists" 0 "Faulty" ;
VAL_ 357 CmbbDeny_B_ActlPrpl 1 "Yes" 0 "No" ;
VAL_ 357 PrplTqMnSat_B_Actl 1 "Yes" 0 "No" ;
VAL_ 357 BpedDrvAppl_D_Actl 3 "_Not_Allowed" 2 "Driver_Braking" 1 "Driver_Not_Braking" 0 "Not_Allowed" ;
VAL_ 357 CmbbEngTqMn_B_Actl 1 "Yes" 0 "No" ;
VAL_ 357 Veh_V_DsplyCcSet 255 "Fault" 254 "Unknown" ;
VAL_ 357 AccEngStat_D_Actl 7 "Undefined_2" 6 "Undefined_1" 5 "ACCSoonCancel_due_Low_Spd" 4 "Shift_Down_Recommendation" 3 "Shift_Up_Recommendation" 2 "ACCNotAllowedToBeActivated" 1 "ACCStandby_due_Auto_Cancel" 0 "Normal_Operation" ;
VAL_ 357 CcMde_D_Actl 7 "TapDownWaiting" 6 "TapUpWaiting" 5 "Resuming_Low" 4 "Resuming_High" 3 "Decelerating" 2 "Accelerating" 1 "Keeping_Speed" 0 "Not_Active" ;
VAL_ 357 CcStat_D_Actl 7 "Undefined_2" 6 "Undefined_1" 5 "Active" 4 "Active_Que_Assist" 3 "Standby" 2 "Standby_Denied" 1 "Denied" 0 "Off" ;
VAL_ 357 CcOvrrdActv_B_Actl 1 "Cruise_Overridden" 0 "Cruise_Req_Not_Overridden" ;
VAL_ 357 AccStopMde_D_Rq 3 "Stop_Mode_Active" 2 "EPBApplyOrBrakeReleaseWarn" 1 "Limit_Rolling_Speed" 0 "Stop_Mode_Not_Active" ;
VAL_ 342 EngOvrhtMitgActv_D_Ind 3 "Undefined" 2 "Mode2" 1 "Mode1" 0 "Normal_Mode" ;
VAL_ 342 EngClntTe_D_Qf 3 "OK" 2 "Not_Within_Specifications" 1 "No_Data_Exists" 0 "Faulty" ;
VAL_ 342 EngOil_Te_Actl 255 "Fault" 254 "Unknown" ;
VAL_ 71 immoTarget1Status 7 "Unused4" 6 "Unused3" 5 "Unused2" 4 "Unused1" 3 "DISABLED_RESET   " 2 "ENABLED_NONMOTIVE_START" 1 "ENABLED_MOTIVE_START" 0 "DISABLED" ;
VAL_ 71 immoTarget1Cmd 7 "Unused4" 6 "Unused3" 5 "Unused2" 4 "Unused1" 3 "TARGET1_IDBLOCK2" 2 "TARGET1_IDBLOCK1" 1 "CHALLENGE" 0 "IDLE" ;
VAL_ 131 HeadLghtHiFlash_D_Stat 3 "NotUsed" 2 "High" 1 "Flash_to_Pass" 0 "Null" ;
VAL_ 131 TurnLghtSwtch_D_Stat 3 "Unused_Treat_As_Off" 2 "Right" 1 "Left" 0 "Off" ;
VAL_ 131 WiprFront_D_Stat 15 "NO_DATA_EXISTS" 14 "STALLED" 13 "RESERVED" 12 "AUTO_ADJUST" 11 "COURTESYWIPE" 10 "AUTO_HIGH" 9 "AUTO_LOW" 8 "WASH" 7 "MIST_FLICK" 6 "MAN_HIGH" 5 "MAN_LOW" 4 "MAN_INT_ON" 3 "MAN_INT_OFF" 2 "OFF_MOVING" 1 "AUTO_OFF" 0 "OFF" ;
VAL_ 131 LghtAmb_D_Sns 7 "No_Data_Exists" 6 "Unused2" 5 "Unused1" 4 "Tunnel_Off" 3 "Tunnel_On" 2 "Twilight" 1 "Light" 0 "Dark" ;
VAL_ 131 AccButtnGapDecPress 1 "Button_Pressed" 0 "Button_Not_Pressed" ;
VAL_ 131 AccButtnGapIncPress 1 "Button_Pressed" 0 "Button_Not_Pressed" ;
VAL_ 131 AslButtnOnOffCnclPress 1 "Button_Pressed" 0 "Button_Not_Pressed" ;
VAL_ 131 AslButtnOnOffPress 1 "Button_Pressed" 0 "Button_Not_Pressed" ;
VAL_ 131 CcAslButtnCnclPress 1 "Button_Pressed" 0 "Button_Not_Pressed" ;
VAL_ 131 LaSwtchPos_D_Stat 3 "Fault" 2 "Unused" 1 "Pressed" 0 "Open" ;
VAL_ 131 CcAslButtnCnclResPress 1 "Button_Pressed" 0 "Button_Not_Pressed" ;
VAL_ 131 CcAslButtnDeny_B_Actl 1 "Yes" 0 "No" ;
VAL_ 131 CcAslButtnIndxDecPress 1 "Button_Pressed" 0 "Button_Not_Pressed" ;
VAL_ 131 CcAslButtnIndxIncPress 1 "Button_Pressed" 0 "Button_Not_Pressed" ;
VAL_ 131 CcAslButtnOffCnclPress 1 "Button_Pressed" 0 "Button_Not_Pressed" ;
VAL_ 131 CcAslButtnOnOffCncl 1 "Button_Pressed" 0 "Button_Not_Pressed" ;
VAL_ 131 CcAslButtnOnPress 1 "Button_Pressed" 0 "Button_Not_Pressed" ;
VAL_ 131 CcAslButtnResDecPress 1 "Button_Pressed" 0 "Button_Not_Pressed" ;
VAL_ 131 CcAslButtnResIncPress 1 "Button_Pressed" 0 "Button_Not_Pressed" ;
VAL_ 131 CcAslButtnSetDecPress 1 "Button_Pressed" 0 "Button_Not_Pressed" ;
VAL_ 131 CcAslButtnSetIncPress 1 "Button_Pressed" 0 "Button_Not_Pressed" ;
VAL_ 131 CcAslButtnSetPress 1 "Button_Pressed" 0 "Button_Not_Pressed" ;
VAL_ 131 CcAsllButtnResPress 1 "Button_Pressed" 0 "Button_Not_Pressed" ;
VAL_ 131 CcButtnOffPress 1 "Button_Pressed" 0 "Button_Not_Pressed" ;
VAL_ 131 CcButtnOnOffCnclPress 1 "Button_Pressed" 0 "Button_Not_Pressed" ;
VAL_ 131 CcButtnOnOffPress 1 "Button_Pressed" 0 "Button_Not_Pressed" ;
VAL_ 131 CcButtnOnPress 1 "Button_Pressed" 0 "Button_Not_Pressed" ;
VAL_ 131 HeadLghtHiFlash_D_Actl 3 "NotUsed" 2 "High" 1 "Flash_to_Pass" 0 "Null" ;
VAL_ 131 HeadLghtHiOn_B_StatAhb 1 "On" 0 "Off" ;
VAL_ 131 AhbStat_B_Dsply 1 "On" 0 "Off" ;
VAL_ 131 AccButtnGapTogglePress 1 "Pressed" 0 "Not_Pressed" ;
VAL_ 131 WiprFrontSwtch_D_Stat 15 "NotUsed6" 14 "NotUsed5" 13 "NotUsed4" 12 "NotUsed3" 11 "NotUsed2" 10 "NotUsed1" 9 "PositionNotDetermined" 8 "High" 7 "Low" 6 "Position6" 5 "Position5" 4 "Position4" 3 "Position3" 2 "Position2" 1 "Position1" 0 "Off" ;
VAL_ 131 HeadLghtHiCtrl_D_RqAhb 7 "NotUsed2" 6 "NotUsed1" 5 "Auto_HiBeam" 4 "Auto_LoBeam" 3 "Flash" 2 "Man_HiBeam" 1 "Man_LoBeam" 0 "Null" ;
VAL_ 131 TjaButtnOnOffPress 1 "Pressed" 0 "Not_Pressed" ;
VAL_ 968 SlMde_D_Rq 3 "IsaNotConfigured" 2 "Manual_Mode" 1 "Auto_Mode" 0 "Null" ;
VAL_ 968 IsaOffst_D_Rq 15 "Faulty" 14 "Null" 13 "Thirteen" 12 "Twelve" 11 "Eleven" 10 "Ten" 9 "Nine" 8 "Eight" 7 "Seven" 6 "Six" 5 "Five" 4 "Four" 3 "Three" 2 "Two" 1 "One" 0 "Zero" ;
VAL_ 806 SnowPlowMde_B_Enbl 1 "Enable" 0 "Disable" ;
VAL_ 806 StopStrtDrvMde_B_RqBtn 1 "Pressed" 0 "Not_Pressed" ;
VAL_ 806 ClimtHeat_D_Rq 7 "NotUsed4" 6 "NotUsed3" 5 "NotUsed2" 4 "PtcHtrTestMde" 3 "Defrost_Defog" 2 "FastTempPullDownHeatingReq" 1 "OpportunisticHeatingReq" 0 "NoHeatingRequest" ;
VAL_ 806 ClimtCool_D_Rq 7 "NotUsed4" 6 "NotUsed3" 5 "NotUsed2" 4 "ElACTestMde" 3 "Defrost_Defog" 2 "FastTempPullDownCoolReq" 1 "OpportunisticCoolingReq" 0 "NoCoolingRequest" ;
VAL_ 806 HvacEvap_Te_Actl 1023 "Fault" ;
VAL_ 806 HvacAirCond_B_Rq 1 "Yes" 0 "No" ;
VAL_ 806 ClimtPw_B_Rq 1 "Yes" 0 "No" ;
VAL_ 1072 LscmbbStat_B_Actl 1 "On" 0 "Off" ;
VAL_ 1072 HaDsplyCpblty_B_Stat 1 "Available" 0 "NotAvailable" ;
VAL_ 1072 AccDeny_B_RqIpc 1 "Yes" 0 "No" ;
VAL_ 1072 DrvSlipCtlMde_D_Rq 3 "App_Specific_Off_Mode_3" 2 "App_Specific_Off_Mode_2" 1 "App_Specific_Off_Mode_1" 0 "Default_Mode" ;
VAL_ 1072 EngIdlShutDown_B_RqDrv 1 "Inhibit" 0 "No_Inibit" ;
VAL_ 1072 HsaMde_D_Rq 3 "Undefined" 2 "Manual" 1 "Automatic" 0 "Off" ;
VAL_ 1072 NtrlTowMdeEnbl_B_RqDrv 1 "Yes" 0 "No" ;
VAL_ 1072 BulbChkActv_B_Stat 1 "Active" 0 "Inactive" ;
VAL_ 1072 ParkDetect_Stat 1 "Park" 0 "Not_Park" ;
VAL_ 1072 ReducedGuard_D_Rq 3 "NotUsed" 2 "On" 1 "Off" 0 "Null" ;
VAL_ 1072 TrlrBrkMde_D_Rq 1 "ElectricOverHydraulic" 0 "Electric" ;
VAL_ 1072 TRLR_SWAY_CONFIG_CMD 1 "On" 0 "Off" ;
VAL_ 1072 TRAILER_BRAKE_CONFIG 1 "Yes" 0 "No" ;
VAL_ 1072 Power_Liftgate_Mode_Cmd 1 "Enable" 0 "Disable" ;
VAL_ 1072 AccEnbl_B_RqDrv 1 "Adaptive_Cruise" 0 "Normal_Cruise" ;
VAL_ 1072 OdometerMasterValue 16777215 "Invalid" ;
VAL_ 1072 EngOilLife_B_RqReset 1 "Yes" 0 "No" ;
VAL_ 1072 ePRNDL_MODE 1 "On" 0 "Off" ;
VAL_ 1072 DrvSlipCtlMde_B_Rq2 1 "Pressed" 0 "Not_Pressed" ;
VAL_ 1072 MetricActv_B_Actl 1 "Active" 0 "Inactive" ;
VAL_ 1072 KeyTypeChngMykey_D_Rq 3 "Search_PE_BackupSlot" 2 "Clear_All_MyKeys" 1 "Request_New_MyKey" 0 "None" ;
VAL_ 1072 ManRgen_D_Rq 3 "NotUsed2" 2 "NotUsed1" 1 "CustInitManExhFilterClean" 0 "No_Customer_Request" ;
VAL_ 963 Illuminated_Entry_Stat 3 "Invalid" 2 "Unknown" 1 "On" 0 "Off" ;
VAL_ 963 Dr_Courtesy_Light_Stat 3 "Invalid" 2 "Unknown" 1 "On" 0 "Off" ;
VAL_ 963 Courtesy_Delay_Status 3 "Invalid" 2 "Unknown" 1 "On" 0 "Off" ;
VAL_ 963 ImpactEvntFdbck_D_Stat 3 "NotUsed" 2 "EventComplete" 1 "EventInProgress" 0 "Normal" ;
VAL_ 963 WrlssAcsyChrgInhbt_B_Rq 1 "Yes" 0 "No" ;
VAL_ 963 PudLampPsngr_D_Rq 3 "Ramp_Down" 2 "Ramp_Up" 1 "On" 0 "Off" ;
VAL_ 963 HeadLampLoOut_B_Stat 1 "Out" 0 "Null" ;
VAL_ 963 HeadLghtHiFdbck_D_Stat 3 "NotUsed" 2 "Cancel" 1 "Hold" 0 "Allow_Change" ;
VAL_ 963 PudLampDrv_D_Rq 3 "Ramp_Down" 2 "Ramp_Up" 1 "On" 0 "Off" ;
VAL_ 963 TrnNotInPrkChime_B_Rq 1 "On" 0 "Off" ;
VAL_ 963 PrkLightChime_B_Rq 1 "On" 0 "Off" ;
VAL_ 963 KeyInIgnWarn_B_Cmd 1 "On" 0 "Off" ;
VAL_ 963 HomeSafeLtChime_B_Rq 1 "On" 0 "Off" ;
VAL_ 963 StopLghtOn_B_Stat 1 "On" 0 "Off" ;
VAL_ 963 RvrseLghtOn_B_Stat 1 "On" 0 "Off" ;
VAL_ 963 PrkLght_D_Stat 3 "Park_Both" 2 "Park_Right" 1 "Park_Left" 0 "Off" ;
VAL_ 963 HeadLghtSwtch_D_Stat 3 "Autolamp" 2 "Headlamp" 1 "Parklamp" 0 "Off" ;
VAL_ 963 HeadLampLoFrOn_B_Stat 1 "Low" 0 "Not_Low" ;
VAL_ 963 HeadLampLoFlOn_B_Stat 1 "Low" 0 "Not_Low" ;
VAL_ 963 HeadLampLoActv_B_Stat 1 "On" 0 "Off" ;
VAL_ 963 Headlamp_On_Wrning_Cmd 1 "On" 0 "Off" ;
VAL_ 963 Park_Brake_Chime_Rqst 1 "On" 0 "Off" ;
VAL_ 963 HeadLghtHiOn_B_Stat 1 "On" 0 "Off" ;
VAL_ 963 BrkWarnInd_B_Rq 1 "On" 0 "Off" ;
VAL_ 963 Brk_Fluid_Lvl_Low 3 "Invalid" 2 "Unknown" 1 "Low" 0 "OK" ;
VAL_ 963 ReducedGuard_D_Stat 3 "NotUsed" 2 "Alarm_On" 1 "Alarm_Off_Previously_On" 0 "Alarm_Off" ;
VAL_ 963 Perimeter_Alarm_Status 3 "Activated" 2 "Armed" 1 "Prearmed" 0 "Disarmed" ;
VAL_ 963 Courtesy_BSave_Stat 3 "Invalid" 2 "Unknown" 1 "No_Effect" 0 "Off" ;
VAL_ 963 DrTgateLck_D_Stat 3 "NotUsed" 2 "Unlock" 1 "Lock" 0 "Null" ;
VAL_ 963 WndwGlbl_D_Cmd 7 "NotUsed3" 6 "NotUsed2" 5 "NotUsed1" 4 "GLEARN" 3 "GCLOSE" 2 "GOPEN" 1 "GSTOP" 0 "Null" ;
VAL_ 963 PudLamp_D_Rq 3 "RAMP_DOWN" 2 "RAMP_UP" 1 "ON" 0 "OFF" ;
VAL_ 963 DayRnngLampOn_B_Stat 1 "On" 0 "Off" ;
VAL_ 963 PerimeterAlarmChimeRq 1 "On" 0 "Off" ;
VAL_ 76 FirstRowBuckleMid 3 "Unknown" 2 "Unbelted" 1 "Belted" 0 "Faulty" ;
VAL_ 76 SecondRowBucklePsngr 3 "Unknown" 2 "Unbelted" 1 "Belted" 0 "Faulty" ;
VAL_ 76 SecondRowBuckleMid 3 "Unknown" 2 "Unbelted" 1 "Belted" 0 "Faulty" ;
VAL_ 76 SecondRowBuckleDriver 3 "Unknown" 2 "Unbelted" 1 "Belted" 0 "Faulty" ;
VAL_ 76 FirstRowBuckleDriver 3 "Unknown" 2 "Unbelted" 1 "Belted" 0 "Faulty" ;
VAL_ 76 RILReq 3 "Not_Used" 2 "Plant_Mode" 1 "On" 0 "Off" ;
VAL_ 76 FirstRowBucklePsngr 3 "Unknown" 2 "Unbelted" 1 "Belted" 0 "Faulty" ;
VAL_ 76 RstrnImpactEvntStatus 7 "Invalid" 6 "Not_Used_4" 5 "Threshold_2_Exceeded" 4 "Not_Used_3" 3 "Threshold_1_Exceeded" 2 "Not_Used_2" 1 "Not_Used_1" 0 "Normal" ;
VAL_ 76 PsngrFrntDetct_D_Actl 3 "Unknown" 2 "Empty" 0 "Faulty" 1 "Occupied" ;
VAL_ 76 EDRTriggerEvntSync 1 "Threshold_Exceeded" 0 "Normal" ;
VAL_ 76 PassRstrnInd_Req 3 "ABOnNotIllum_OffNotIllum" 2 "AirbagOnNot_Illum_OffIllum" 1 "AirbagOn_Illum_OffNotIllum" 0 "AirbagOn_Illum_Off_Illum" ;
VAL_ 65 immoControlCmd_T1 0 "IDLE" 1 "MOTIVE_START_RQST" 2 "NONMOTIVE_START_RQST" 3 "RQST_TARGET1_IDBLOCK1" 4 "RQST_TARGET1_IDBLOCK2" 5 "Unused" 6 "ECHO_TARGET1_IDBLOCK2" 7 "SHUTDOWN" ;
VAL_ 1076 HILL_DESC_SW 1 "On" 0 "Off" ;
VAL_ 1076 AutoRgen_D_Rq 3 "NotUsed" 2 "AutExhFilterCleanOFF" 1 "AutExhFilterCleanON" 0 "No_Mode_Selected" ;
VAL_ 1076 W2S_LAMP_OK 1 "Yes" 0 "No" ;
VAL_ 1076 OdoTripRx_B_Actl 1 "Yes" 0 "No" ;
VAL_ 1076 DrvSlipCtlMde_B_RqMyKey 1 "On" 0 "Off" ;
VAL_ 1076 FuelLvlWarn_D_Actl 3 "NotUsed" 2 "VeryLow" 1 "Low" 0 "OK" ;
VAL_ 1076 FuelSecndActv_B_Actl 1 "Yes" 0 "No" ;
VAL_ 1076 FUEL_SENSOR_NUM 1 "Dual_Sensors" 0 "Single_Sensor" ;
VAL_ 862 AutoStpHvacDelta_I_Est 255 "Fault" ;
VAL_ 862 HvacBlwrFront_D_Stat 31 "Not_Used" 20 "Full_On" 19 "95_Percent" 18 "90_Percent" 17 "85_Percent" 16 "80_Percent" 15 "75_Percent" 14 "70_Percent" 13 "65_Percent" 12 "60_Percent" 11 "55_Percent" 10 "50_Percent" 9 "45_Percent" 8 "40_Percent" 7 "35_Percent" 6 "30_Percent" 5 "25_Percent" 4 "20_Percent" 3 "15_Percent" 2 "10_Percent" 1 "5_Percent" 0 "Off" ;
VAL_ 862 CabnAmb_Te_Actl 255 "Fault" ;
VAL_ 862 ClimtThrmlLoad_No_Actl 255 "Fault" ;
VAL_ 578 PtLatchActv_B_RqBcm 1 "On" 0 "Off" ;
VAL_ 578 immoSecureIdleMode 3 "NotUsed2" 2 "NotUsed1" 1 "Active" 0 "Inactive" ;
VAL_ 578 ReFuelSwtchStat_D_Actl 3 "NotUsed2" 2 "NotUsed1" 1 "On" 0 "Off" ;
VAL_ 578 FuelPumpPwr_D_Stat 7 "NotUsed3" 6 "NotUsed2" 5 "NotUsed1" 4 "Power_Off_Default" 3 "Power_Off_Command" 2 "Power_Off_Service" 1 "Power_Off_Impact" 0 "Power_On" ;
VAL_ 578 BattULo_U_Actl 255 "Fault" ;
VAL_ 578 PrkLckCtl_B_Enbl 1 "Enable" 0 "Disable" ;
VAL_ 578 PrkLckCtlMsgTxt_D_Rq 3 "BTSI_DI_3" 2 "BTSI_DI_2" 1 "BTSI_DI_1" 0 "Null_BTSI_DI" ;
VAL_ 578 BrkTrnShifLck_B_Stat 1 "Shift" 0 "NoShift" ;
VAL_ 578 PrkLckCtlUnlck_D_Stat 3 "Trans_And_Steer_Unlckd" 2 "Steering_Unlckd" 1 "Transmission_Unlckd" 0 "Null" ;
VAL_ 578 PrkLckCtlTow_B_Enbl 1 "Enable" 0 "Disable" ;
VAL_ 578 DriverCrankingReq 1 "Crank_Request" 0 "No_Crank_Request" ;
VAL_ 578 EngOff_T_Actl 65535 "Invalid" ;
VAL_ 578 DcacElPw_D_Rq 3 "NotUsed" 2 "AC_HighPower_Requested" 1 "AC_LowPower_Requested" 0 "AC_Power_NotRequested" ;
VAL_ 578 BattULo_I_Actl 16383 "Fault" ;
VAL_ 1084 BattULoState_D_Qlty 3 "OK" 2 "Not_Within_Specifications" 1 "Eval_In_Progress" 0 "Fault" ;
VAL_ 1084 BSFault 1 "Fault" 0 "No_Fault" ;
VAL_ 1084 BattULo2_Te_Actl 127 "Fault" ;
VAL_ 1068 EngStrtInhbt_B_RqBatt 1 "Start_Inhibit" 0 "Dont_Care" ;
VAL_ 1068 BattULoChrg_D_Rq 3 "Low_Battery_Temperature" 2 "Charging_Requested" 1 "Chrg_Requested_HighCurrent" 0 "No_Request" ;
VAL_ 1068 PwSysULoFalt_D_Stat 15 "Not_Used_6" 14 "LowBatterySOC" 13 "PSS_Shed2_Contin" 12 "Not_Used_4" 11 "Not_Used_3" 10 "Not_Used_2" 9 "BattMonitoringSensorFault" 8 "LowBattVoltDuringPwSrcOn" 7 "LowBatt2_PowerSaveMode" 6 "LowBatt1_Warning" 5 "Overvoltage" 4 "Fault_NoOutput" 3 "Fault_ReducedOutput" 2 "Fault_Nonspecific" 1 "Cluster_Proveout" 0 "No_Fault" ;
VAL_ 1068 Shed_T_Eng_Off_B 1 "Active" 0 "Inactive" ;
VAL_ 1068 Shed_Feature_Group_ID 16 "PtcHeater" 14 "HtdMirr" 13 "HvacRearBlwr_Third" 12 "HvacRearBlwr_Second" 11 "HvacRearBlwr_First" 31 "All LSHED1 Features" 10 "Htd_Windscrn" 9 "SpltHtdBcklight_HtdMirr" 8 "HtdBcklight_HtdMirr" 7 "HtdCoolSeat_FrtDriver" 6 "HtdCoolSeat_FrtPass" 5 "HtdCoolSeat_RearPass" 4 "HtdCoolSeat_RearDriver" 3 "SmartTrlrTowBattCharge" 2 "Htd_StrWhl" 1 "Htd_Washer_Fluid" 0 "No_LSHED1_Features" 15 "Engine_Coolant_Fan" ;
VAL_ 1068 Shed_Drain_Eng_Off_B 1 "Active" 0 "Inactive" ;
VAL_ 1068 Shed_Level_Req 7 "Unused_2" 6 "Loads_On" 5 "SHED_ENG_OFF" 4 "SOON_ENG_OFF" 3 "SHED2_CONTIN" 2 "SHED2_TRANS" 1 "SHED1" 0 "NO_SHED" ;
VAL_ 1068 ULoRgenTestMde_B_Rq 1 "Request" 0 "NoRequest" ;
VAL_ 1068 ChargeMode 7 "Undefined_2" 6 "Undefined_1" 5 "Battery_Identify" 4 "Battery_Refresh" 3 "SlowRegenAllowNoDischarge" 2 "Fast_Regen_Allowed" 1 "Slow_Regen_Allowed" 0 "Conventional_Charging" ;
VAL_ 1068 IdleSpeedIncrease_El 1 "Yes" 0 "No" ;
VAL_ 1068 Batt_Lo_SoC_B 1 "Active" 0 "Inactive" ;
VAL_ 1068 PeriodicElLoad_B_Stat 1 "Active" 0 "Inactive" ;
VAL_ 1068 Batt_Crit_SoC_B 1 "Active" 0 "Inactive" ;
VAL_ 146 VehVert2_A_Actl 8191 "Faulty" 8190 "NoDataExists" ;
VAL_ 146 VehLong2_A_Actl 8191 "Faulty" 8190 "NoDataExists" ;
VAL_ 146 VehLat2_A_Actl 8191 "Faulty" 8190 "NoDataExists" ;
VAL_ 146 VehVertAActl_D_Qf 3 "OK" 2 "Not_Within_Specifications" 1 "No_Data_Exists" 0 "Faulty" ;
VAL_ 146 VehLongAActl_D_Qf 3 "OK" 2 "Not_Within_Specifications" 1 "No_Data_Exists" 0 "Faulty" ;
VAL_ 146 VehLatAActl_D_Qf 3 "OK" 2 "Not_Within_Specifications" 1 "No_Data_Exists" 0 "Faulty" ;
VAL_ 997 PersIndexCcm_D_Actl 7 "Unused_3" 6 "Unused_2" 5 "Unused_1" 4 "Vehicle" 3 "PERS_4" 2 "PERS_3" 1 "PERS_2" 0 "PERS_1" ;
